VERSION "HNNBNNNYNNNNNNNNNNNNNNNNNNNNNNNNNNNNNNNNNN/4/%%%/4/'%**4NNN///"

NS_ :

BS_:

BU_: BAP_Tester FASFrontradar ICAS1_X_Gateway MFK MFK120 MIK MRR2023 NR_1 NR_2

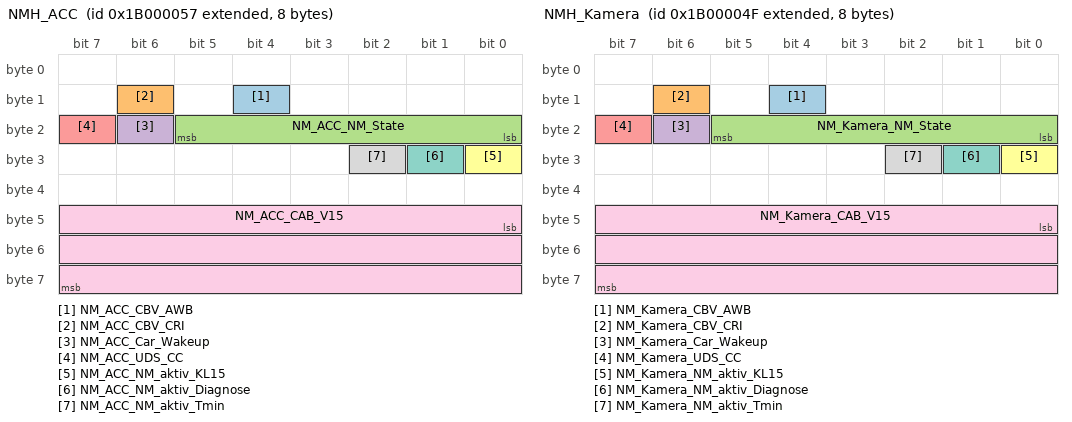
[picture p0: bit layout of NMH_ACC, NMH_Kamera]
BO_ 2600468567 NMH_ACC: 8 FASFrontradar
 SG_ NM_ACC_CBV_AWB : 12|1@1+ (1.0,0.0) [0.0|1] ""  ICAS1_X_Gateway
 SG_ NM_ACC_CBV_CRI : 14|1@1+ (1.0,0.0) [0.0|1] ""  ICAS1_X_Gateway
 SG_ NM_ACC_NM_State : 16|6@1+ (1.0,0.0) [0.0|63] ""  MFK,MFK120,MIK,NR_1,NR_2
 SG_ NM_ACC_Car_Wakeup : 22|1@1+ (1.0,0.0) [0.0|1] ""  ICAS1_X_Gateway
 SG_ NM_ACC_UDS_CC : 23|1@1+ (1.0,0.0) [0.0|1] ""  Vector__XXX
 SG_ NM_ACC_NM_aktiv_KL15 : 24|1@1+ (1.0,0.0) [0.0|1] ""  Vector__XXX
 SG_ NM_ACC_NM_aktiv_Diagnose : 25|1@1+ (1.0,0.0) [0.0|1] ""  Vector__XXX
 SG_ NM_ACC_NM_aktiv_Tmin : 26|1@1+ (1.0,0.0) [0.0|1] ""  Vector__XXX
 SG_ NM_ACC_CAB_V15 : 40|24@1+ (1.0,0.0) [0.0|16777215] ""  ICAS1_X_Gateway

BO_ 2600468496 NMH_Gateway: 8 ICAS1_X_Gateway
 SG_ NM_Gateway_CBV_AWB : 12|1@1+ (1.0,0.0) [0.0|1] ""  Vector__XXX
 SG_ NM_Gateway_CBV_CRI : 14|1@1+ (1.0,0.0) [0.0|1] ""  Vector__XXX
 SG_ NM_Gateway_NM_State : 16|6@1+ (1.0,0.0) [0.0|63] ""  FASFrontradar,MFK,MFK120,MIK,MRR2023,NR_1,NR_2
 SG_ NM_Gateway_Car_Wakeup : 22|1@1+ (1.0,0.0) [0.0|1] ""  Vector__XXX
 SG_ NM_Gateway_UDS_CC : 23|1@1+ (1.0,0.0) [0.0|1] ""  Vector__XXX
 SG_ NM_Gateway_NM_aktiv_KL15 : 24|1@1+ (1.0,0.0) [0.0|1] ""  Vector__XXX
 SG_ NM_Gateway_NM_aktiv_Diagnose : 25|1@1+ (1.0,0.0) [0.0|1] ""  Vector__XXX
 SG_ NM_Gateway_NM_aktiv_Tmin : 26|1@1+ (1.0,0.0) [0.0|1] ""  Vector__XXX
 SG_ NM_Gateway_NM_aktiv_Kessy : 27|1@1+ (1.0,0.0) [0.0|1] ""  Vector__XXX
 SG_ NM_Gateway_NM_aktiv_Energie : 28|1@1+ (1.0,0.0) [0.0|1] ""  Vector__XXX
 SG_ NM_Gateway_NM_aktiv_Licht : 29|1@1+ (1.0,0.0) [0.0|1] ""  Vector__XXX
 SG_ NM_Gateway_NM_aktiv_USS : 30|1@1+ (1.0,0.0) [0.0|1] ""  Vector__XXX
 SG_ NM_Gateway_NM_aktiv_IAA_PSO : 31|1@1+ (1.0,0.0) [0.0|1] ""  Vector__XXX
 SG_ NM_Gateway_NM_aktiv_CAB : 32|1@1+ (1.0,0.0) [0.0|1] ""  Vector__XXX
 SG_ NM_Gateway_NM_aktiv_KS : 33|1@1+ (1.0,0.0) [0.0|1] ""  Vector__XXX
 SG_ NM_Gateway_NM_aktiv_PaCo : 34|1@1+ (1.0,0.0) [0.0|1] ""  Vector__XXX
 SG_ NM_Gateway_NM_aktiv_Standklima : 35|1@1+ (1.0,0.0) [0.0|1] ""  Vector__XXX
 SG_ NM_Gateway_NM_aktiv_ZV : 36|1@1+ (1.0,0.0) [0.0|1] ""  Vector__XXX
 SG_ NM_Gateway_NM_aktiv_RTM : 37|1@1+ (1.0,0.0) [0.0|1] ""  Vector__XXX
 SG_ NM_Gateway_NM_aktiv_ZM : 38|1@1+ (1.0,0.0) [0.0|1] ""  Vector__XXX
 SG_ NM_Gateway_NM_aktiv_FoD : 39|1@1+ (1.0,0.0) [0.0|1] ""  Vector__XXX
 SG_ NM_Gateway_CAB_V15 : 40|24@1+ (1.0,0.0) [0.0|16777215] ""  Vector__XXX

BO_ 2600468559 NMH_Kamera: 8 MFK
 SG_ NM_Kamera_CBV_AWB : 12|1@1+ (1.0,0.0) [0.0|1] ""  ICAS1_X_Gateway
 SG_ NM_Kamera_CBV_CRI : 14|1@1+ (1.0,0.0) [0.0|1] ""  ICAS1_X_Gateway
 SG_ NM_Kamera_NM_State : 16|6@1+ (1.0,0.0) [0.0|63] ""  FASFrontradar,MIK,MRR2023,NR_1,NR_2
 SG_ NM_Kamera_Car_Wakeup : 22|1@1+ (1.0,0.0) [0.0|1] ""  ICAS1_X_Gateway
 SG_ NM_Kamera_UDS_CC : 23|1@1+ (1.0,0.0) [0.0|1] ""  Vector__XXX
 SG_ NM_Kamera_NM_aktiv_KL15 : 24|1@1+ (1.0,0.0) [0.0|1] ""  Vector__XXX
 SG_ NM_Kamera_NM_aktiv_Diagnose : 25|1@1+ (1.0,0.0) [0.0|1] ""  Vector__XXX
 SG_ NM_Kamera_NM_aktiv_Tmin : 26|1@1+ (1.0,0.0) [0.0|1] ""  Vector__XXX
 SG_ NM_Kamera_CAB_V15 : 40|24@1+ (1.0,0.0) [0.0|16777215] ""  ICAS1_X_Gateway

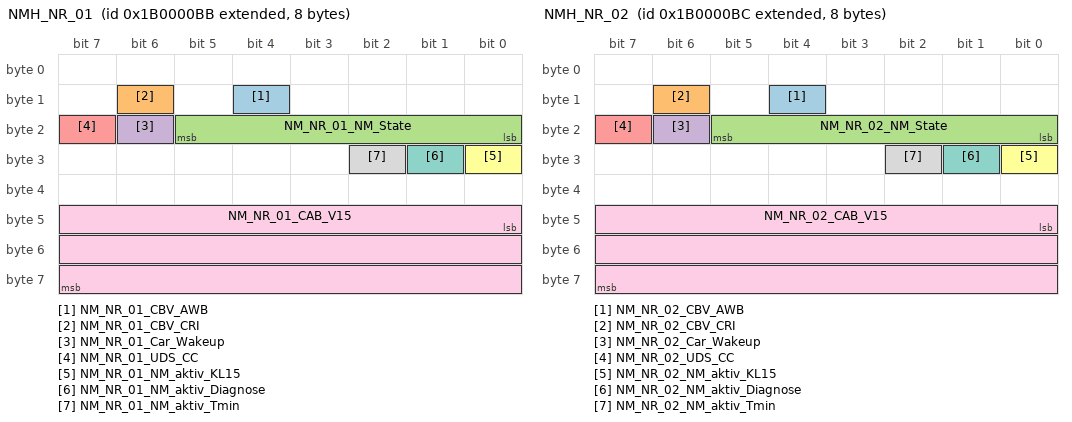
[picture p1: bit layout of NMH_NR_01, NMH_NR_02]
BO_ 2600468667 NMH_NR_01: 8 NR_1
 SG_ NM_NR_01_CBV_AWB : 12|1@1+ (1.0,0.0) [0.0|1] ""  ICAS1_X_Gateway
 SG_ NM_NR_01_CBV_CRI : 14|1@1+ (1.0,0.0) [0.0|1] ""  ICAS1_X_Gateway
 SG_ NM_NR_01_NM_State : 16|6@1+ (1.0,0.0) [0.0|63] ""  MFK120,MIK,MRR2023,NR_2
 SG_ NM_NR_01_Car_Wakeup : 22|1@1+ (1.0,0.0) [0.0|1] ""  ICAS1_X_Gateway
 SG_ NM_NR_01_UDS_CC : 23|1@1+ (1.0,0.0) [0.0|1] ""  Vector__XXX
 SG_ NM_NR_01_NM_aktiv_KL15 : 24|1@1+ (1.0,0.0) [0.0|1] ""  Vector__XXX
 SG_ NM_NR_01_NM_aktiv_Diagnose : 25|1@1+ (1.0,0.0) [0.0|1] ""  Vector__XXX
 SG_ NM_NR_01_NM_aktiv_Tmin : 26|1@1+ (1.0,0.0) [0.0|1] ""  Vector__XXX
 SG_ NM_NR_01_CAB_V15 : 40|24@1+ (1.0,0.0) [0.0|16777215] ""  ICAS1_X_Gateway

BO_ 2600468668 NMH_NR_02: 8 NR_2
 SG_ NM_NR_02_CBV_AWB : 12|1@1+ (1.0,0.0) [0.0|1] ""  ICAS1_X_Gateway
 SG_ NM_NR_02_CBV_CRI : 14|1@1+ (1.0,0.0) [0.0|1] ""  ICAS1_X_Gateway
 SG_ NM_NR_02_NM_State : 16|6@1+ (1.0,0.0) [0.0|63] ""  MFK120,MIK,MRR2023,NR_1
 SG_ NM_NR_02_Car_Wakeup : 22|1@1+ (1.0,0.0) [0.0|1] ""  ICAS1_X_Gateway
 SG_ NM_NR_02_UDS_CC : 23|1@1+ (1.0,0.0) [0.0|1] ""  Vector__XXX
 SG_ NM_NR_02_NM_aktiv_KL15 : 24|1@1+ (1.0,0.0) [0.0|1] ""  Vector__XXX
 SG_ NM_NR_02_NM_aktiv_Diagnose : 25|1@1+ (1.0,0.0) [0.0|1] ""  Vector__XXX
 SG_ NM_NR_02_NM_aktiv_Tmin : 26|1@1+ (1.0,0.0) [0.0|1] ""  Vector__XXX
 SG_ NM_NR_02_CAB_V15 : 40|24@1+ (1.0,0.0) [0.0|16777215] ""  ICAS1_X_Gateway

BO_ 2589283909 NR_01_CAL_Text_01: 8 NR_1
 SG_ NR_01_CAL_Text_Request : 0|1@1+ (1.0,0.0) [0.0|1] ""  ICAS1_X_Gateway
 SG_ NR_01_CAL_Text_Data_1 : 8|56@1+ (1.0,0.0) [0.0|72057594037927935] ""  ICAS1_X_Gateway

BO_ 2589283910 NR_01_CAL_Text_02: 8 NR_1
 SG_ NR_01_CAL_Text_Data_2 : 0|64@1+ (1.0,0.0) [0.0|18446744073709551615] ""  ICAS1_X_Gateway

BO_ 2589283911 NR_01_CAL_Text_03: 8 NR_1
 SG_ NR_01_CAL_Text_Data_3 : 0|64@1+ (1.0,0.0) [0.0|18446744073709551615] ""  ICAS1_X_Gateway

BO_ 2527679889 NR_02_CAL_01: 8 NR_2
 SG_ NR_02_CAL_LgtLimV_StAcv : 12|2@1+ (1.0,0.0) [0.0|3] ""  Vector__XXX
 SG_ NR_02_CAL_LgtLimV_VDmd : 14|7@1+ (0.1,0) [0.0|12.4] "Unit_MeterPerSecon"  Vector__XXX

BO_ 2589283912 NR_02_CAL_Text_01: 8 NR_2
 SG_ NR_02_CAL_Text_Request : 0|1@1+ (1.0,0.0) [0.0|1] ""  ICAS1_X_Gateway
 SG_ NR_02_CAL_Text_Data_1 : 8|56@1+ (1.0,0.0) [0.0|72057594037927935] ""  ICAS1_X_Gateway

BO_ 2589283913 NR_02_CAL_Text_02: 8 NR_2
 SG_ NR_02_CAL_Text_Data_2 : 0|64@1+ (1.0,0.0) [0.0|18446744073709551615] ""  ICAS1_X_Gateway

BO_ 2589283914 NR_02_CAL_Text_03: 8 NR_2
 SG_ NR_02_CAL_Text_Data_3 : 0|64@1+ (1.0,0.0) [0.0|18446744073709551615] ""  ICAS1_X_Gateway

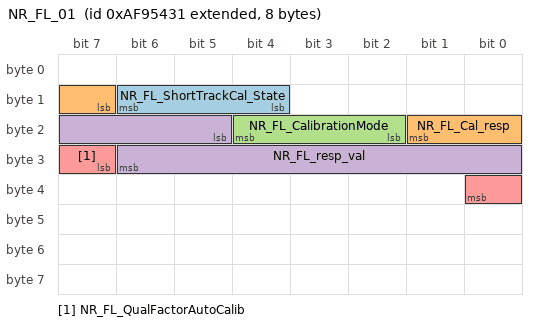
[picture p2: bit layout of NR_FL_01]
BO_ 2331595825 NR_FL_01: 8 NR_1
 SG_ NR_FL_ShortTrackCal_State : 12|3@1+ (1.0,0.0) [0.0|7] ""  ICAS1_X_Gateway,MRR2023
 SG_ NR_FL_Cal_resp : 15|3@1+ (1.0,0.0) [0.0|7] ""  ICAS1_X_Gateway,MRR2023
 SG_ NR_FL_CalibrationMode : 18|3@1+ (1.0,0.0) [0.0|7] ""  ICAS1_X_Gateway,MRR2023
 SG_ NR_FL_resp_val : 21|10@1+ (0.01,-5) [-5.00|5.00] "Unit_DegreOfArc"  ICAS1_X_Gateway,MRR2023
 SG_ NR_FL_QualFactorAutoCalib : 31|2@1+ (1.0,0.0) [0.0|3] ""  ICAS1_X_Gateway,MRR2023

BO_ 2331595790 NR_FL_Contour: 64 NR_1
 SG_ NR_FL_Contour_CRC : 0|8@1+ (1,0) [0|255] ""  ICAS1_X_Gateway,MRR2023
 SG_ NR_FL_Contour_BZ : 8|4@1+ (1,0) [0|15] ""  ICAS1_X_Gateway,MRR2023
 SG_ NR_FL_Contour_BlockID_01 : 12|4@1+ (1,0) [0|15] "Unit_None"  ICAS1_X_Gateway,MRR2023
 SG_ NR_FL_Contour_left_01_x01 : 16|13@1+ (0.0625,-256) [-256.0000|255.8750] "Unit_Meter"  ICAS1_X_Gateway,MRR2023
 SG_ NR_FL_Contour_left_01_y01 : 29|11@1+ (0.0625,-64) [-64.0000|63.8750] "Unit_Meter"  ICAS1_X_Gateway,MRR2023
 SG_ NR_FL_Contour_left_01_x02 : 40|13@1+ (0.0625,-256) [-256.0000|255.8750] "Unit_Meter"  ICAS1_X_Gateway,MRR2023
 SG_ NR_FL_Contour_left_01_y02 : 53|11@1+ (0.0625,-64) [-64.0000|63.8750] "Unit_Meter"  ICAS1_X_Gateway,MRR2023
 SG_ NR_FL_Contour_left_01_x03 : 64|13@1+ (0.0625,-256) [-256.0000|255.8750] "Unit_Meter"  ICAS1_X_Gateway,MRR2023
 SG_ NR_FL_Contour_left_01_y03 : 77|11@1+ (0.0625,-64) [-64.0000|63.8750] "Unit_Meter"  ICAS1_X_Gateway,MRR2023
 SG_ NR_FL_Contour_left_01_x04 : 88|13@1+ (0.0625,-256) [-256.0000|255.8750] "Unit_Meter"  ICAS1_X_Gateway,MRR2023
 SG_ NR_FL_Contour_left_01_y04 : 101|11@1+ (0.0625,-64) [-64.0000|63.8750] "Unit_Meter"  ICAS1_X_Gateway,MRR2023
 SG_ NR_FL_Contour_left_01_x05 : 112|13@1+ (0.0625,-256) [-256.0000|255.8750] "Unit_Meter"  ICAS1_X_Gateway,MRR2023
 SG_ NR_FL_Contour_left_01_y05 : 125|11@1+ (0.0625,-64) [-64.0000|63.8750] "Unit_Meter"  ICAS1_X_Gateway,MRR2023
 SG_ NR_FL_Contour_left_01_x06 : 136|13@1+ (0.0625,-256) [-256.0000|255.8750] "Unit_Meter"  ICAS1_X_Gateway,MRR2023
 SG_ NR_FL_Contour_left_01_y06 : 149|11@1+ (0.0625,-64) [-64.0000|63.8750] "Unit_Meter"  ICAS1_X_Gateway,MRR2023
 SG_ NR_FL_Contour_left_01_x07 : 160|13@1+ (0.0625,-256) [-256.0000|255.8750] "Unit_Meter"  ICAS1_X_Gateway,MRR2023
 SG_ NR_FL_Contour_left_01_y07 : 173|11@1+ (0.0625,-64) [-64.0000|63.8750] "Unit_Meter"  ICAS1_X_Gateway,MRR2023
 SG_ NR_FL_Contour_left_01_Type : 184|3@1+ (1.0,0.0) [0.0|7] ""  ICAS1_X_Gateway,MRR2023
 SG_ NR_FL_Contour_left_01_Age : 187|7@1+ (1,0) [0|126] "Unit_None"  ICAS1_X_Gateway,MRR2023
 SG_ NR_FL_Contour_left_02_x01 : 194|13@1+ (0.0625,-256) [-256.0000|255.8750] "Unit_Meter"  ICAS1_X_Gateway,MRR2023
 SG_ NR_FL_Contour_left_02_y01 : 207|11@1+ (0.0625,-64) [-64.0000|63.8750] "Unit_Meter"  ICAS1_X_Gateway,MRR2023
 SG_ NR_FL_Contour_left_02_x02 : 218|13@1+ (0.0625,-256) [-256.0000|255.8750] "Unit_Meter"  ICAS1_X_Gateway,MRR2023
 SG_ NR_FL_Contour_left_02_y02 : 231|11@1+ (0.0625,-64) [-64.0000|63.8750] "Unit_Meter"  ICAS1_X_Gateway,MRR2023
 SG_ NR_FL_Contour_left_02_x03 : 242|13@1+ (0.0625,-256) [-256.0000|255.8750] "Unit_Meter"  ICAS1_X_Gateway,MRR2023
 SG_ NR_FL_Contour_left_02_y03 : 255|11@1+ (0.0625,-64) [-64.0000|63.8750] "Unit_Meter"  ICAS1_X_Gateway,MRR2023
 SG_ NR_FL_Contour_left_02_x04 : 266|13@1+ (0.0625,-256) [-256.0000|255.8750] "Unit_Meter"  ICAS1_X_Gateway,MRR2023
 SG_ NR_FL_Contour_left_02_y04 : 279|11@1+ (0.0625,-64) [-64.0000|63.8750] "Unit_Meter"  ICAS1_X_Gateway,MRR2023
 SG_ NR_FL_Contour_left_02_x05 : 290|13@1+ (0.0625,-256) [-256.0000|255.8750] "Unit_Meter"  ICAS1_X_Gateway,MRR2023
 SG_ NR_FL_Contour_left_02_y05 : 303|11@1+ (0.0625,-64) [-64.0000|63.8750] "Unit_Meter"  ICAS1_X_Gateway,MRR2023
 SG_ NR_FL_Contour_left_02_x06 : 314|13@1+ (0.0625,-256) [-256.0000|255.8750] "Unit_Meter"  ICAS1_X_Gateway,MRR2023
 SG_ NR_FL_Contour_left_02_y06 : 327|11@1+ (0.0625,-64) [-64.0000|63.8750] "Unit_Meter"  ICAS1_X_Gateway,MRR2023
 SG_ NR_FL_Contour_left_02_x07 : 338|13@1+ (0.0625,-256) [-256.0000|255.8750] "Unit_Meter"  ICAS1_X_Gateway,MRR2023
 SG_ NR_FL_Contour_left_02_y07 : 351|11@1+ (0.0625,-64) [-64.0000|63.8750] "Unit_Meter"  ICAS1_X_Gateway,MRR2023
 SG_ NR_FL_Contour_left_02_Type : 362|3@1+ (1.0,0.0) [0.0|7] ""  ICAS1_X_Gateway,MRR2023
 SG_ NR_FL_Contour_left_02_Age : 365|7@1+ (1,0) [0|126] "Unit_None"  ICAS1_X_Gateway,MRR2023
 SG_ NR_FL_Contour_left_Linkage : 372|1@1+ (1.0,0.0) [0.0|1] ""  ICAS1_X_Gateway,MRR2023
 SG_ SOK_NR_FL_Contour_Signatur : 480|32@1+ (1,0) [0|4294967295] ""  ICAS1_X_Gateway

BO_ 2331595781 NR_FL_Header: 20 NR_1
 SG_ NR_FL_Header_CRC : 0|8@1+ (1,0) [0|255] ""  ICAS1_X_Gateway,MRR2023
 SG_ NR_FL_Header_BZ : 8|4@1+ (1,0) [0|15] ""  ICAS1_X_Gateway,MRR2023
 SG_ NR_FL_BlockID_01 : 12|4@1+ (1,0) [0|15] "Unit_None"  ICAS1_X_Gateway,MRR2023
 SG_ NR_FL_NotAvailable : 16|1@1+ (1.0,0.0) [0.0|1] ""  ICAS1_X_Gateway,MRR2023
 SG_ NR_FL_Failure : 17|1@1+ (1.0,0.0) [0.0|1] ""  ICAS1_X_Gateway,MRR2023
 SG_ NR_FL_Blindness : 18|1@1+ (1.0,0.0) [0.0|1] ""  ICAS1_X_Gateway,MRR2023
 SG_ NR_FL_CalibrationState : 19|3@1+ (1.0,0.0) [0.0|7] ""  ICAS1_X_Gateway,MRR2023
 SG_ NR_FL_Freesight_NOK : 22|1@1+ (1.0,0.0) [0.0|1] ""  ICAS1_X_Gateway,MRR2023
 SG_ NR_FL_MeasurementTimeLow : 30|32@1+ (1,0) [0|999999999] "Unit_NanoSecon"  ICAS1_X_Gateway,MRR2023
 SG_ NR_FL_MeasurementTimeHigh : 62|32@1+ (1,0) [0|4294967293] "Unit_Secon"  ICAS1_X_Gateway,MRR2023
 SG_ NR_FL_RangeDegradation_Sect1 : 94|3@1+ (1.0,0.0) [0.0|7] ""  ICAS1_X_Gateway,MRR2023
 SG_ NR_FL_RangeDegradation_Sect2 : 97|3@1+ (1.0,0.0) [0.0|7] ""  ICAS1_X_Gateway,MRR2023
 SG_ NR_FL_RangeDegradation_Sect3 : 100|3@1+ (1.0,0.0) [0.0|7] ""  ICAS1_X_Gateway,MRR2023
 SG_ NR_FL_MeasurementTimeLapNumber : 103|14@1+ (1,0) [0|16381] "Unit_None"  ICAS1_X_Gateway,MRR2023
 SG_ NR_FL_MeasurementTimeStatus : 117|2@1+ (1.0,0.0) [0.0|3] ""  ICAS1_X_Gateway,MRR2023
 SG_ SOK_NR_FL_Header_Signatur : 128|32@1+ (1,0) [0|4294967295] ""  ICAS1_X_Gateway

BO_ 2331595776 NR_FL_Object_01_02: 64 NR_1
 SG_ NR_FL_Object_01_02_CRC : 0|8@1+ (1,0) [0|255] ""  ICAS1_X_Gateway,MRR2023
 SG_ NR_FL_Object_01_02_BZ : 8|4@1+ (1,0) [0|15] ""  ICAS1_X_Gateway,MRR2023
 SG_ NR_FL_Object_01_02_BlockID_01 : 12|4@1+ (1,0) [0|15] "Unit_None"  ICAS1_X_Gateway,MRR2023
 SG_ NR_FL_Object_01_ID : 16|8@1+ (1,0) [1|254] "Unit_None"  ICAS1_X_Gateway,MRR2023
 SG_ NR_FL_Object_01_ReferencePoint : 24|4@1+ (1.0,0.0) [0.0|15] ""  ICAS1_X_Gateway,MRR2023
 SG_ NR_FL_Object_01_PosX : 28|14@1+ (0.03125,-200) [-200.00000|311.93750] "Unit_Meter"  ICAS1_X_Gateway,MRR2023
 SG_ NR_FL_Object_01_PosXSD : 42|8@1+ (0.03125,0) [0.00000|7.93750] "Unit_Meter"  ICAS1_X_Gateway,MRR2023
 SG_ NR_FL_Object_01_PosY : 50|13@1+ (0.03125,-128) [-128.00000|127.93750] "Unit_Meter"  ICAS1_X_Gateway,MRR2023
 SG_ NR_FL_Object_01_PosYSD : 63|8@1+ (0.03125,0) [0.00000|7.93750] "Unit_Meter"  ICAS1_X_Gateway,MRR2023
 SG_ NR_FL_Object_01_vAbsX : 71|12@1+ (0.0625,-128) [-128.0000|127.8750] "Unit_MeterPerSecon"  ICAS1_X_Gateway,MRR2023
 SG_ NR_FL_Object_01_vAbsXSD : 83|6@1+ (0.0625,0) [0.0000|3.8750] "Unit_MeterPerSecon"  ICAS1_X_Gateway,MRR2023
 SG_ NR_FL_Object_01_vAbsY : 89|12@1+ (0.0625,-128) [-128.0000|127.8750] "Unit_MeterPerSecon"  ICAS1_X_Gateway,MRR2023
 SG_ NR_FL_Object_01_vAbsYSD : 101|6@1+ (0.0625,0) [0.0000|3.8750] "Unit_MeterPerSecon"  ICAS1_X_Gateway,MRR2023
 SG_ NR_FL_Object_01_aAbsX : 107|9@1+ (0.0625,-16) [-16.0000|15.8750] "Unit_MeterPerSeconSquar"  ICAS1_X_Gateway,MRR2023
 SG_ NR_FL_Object_01_aAbsXSD : 116|6@1+ (0.0625,0) [0.0000|3.8750] "Unit_MeterPerSeconSquar"  ICAS1_X_Gateway,MRR2023
 SG_ NR_FL_Object_01_aAbsY : 122|9@1+ (0.0625,-16) [-16.0000|15.8750] "Unit_MeterPerSeconSquar"  ICAS1_X_Gateway,MRR2023
 SG_ NR_FL_Object_01_aAbsYSD : 131|6@1+ (0.0625,0) [0.0000|3.8750] "Unit_MeterPerSeconSquar"  ICAS1_X_Gateway,MRR2023
 SG_ NR_FL_Object_01_DynamicState : 137|2@1+ (1.0,0.0) [0.0|3] ""  ICAS1_X_Gateway,MRR2023
 SG_ NR_FL_Object_01_YawAngle : 139|12@1+ (0.001953125,-4) [-4.000000000|3.996093750] "Unit_Radia"  ICAS1_X_Gateway,MRR2023
 SG_ NR_FL_Object_01_YawAngleSD : 151|9@1+ (0.001953125,0) [0E-9|0.996093750] "Unit_Radia"  ICAS1_X_Gateway,MRR2023
 SG_ NR_FL_Object_01_Width : 160|8@1+ (0.03125,0) [0.00000|7.93750] "Unit_Meter"  ICAS1_X_Gateway,MRR2023
 SG_ NR_FL_Object_01_WidthSD : 168|7@1+ (0.03125,0) [0.00000|3.93750] "Unit_Meter"  ICAS1_X_Gateway,MRR2023
 SG_ NR_FL_Object_01_Length : 175|10@1+ (0.03125,0) [0.00000|31.93750] "Unit_Meter"  ICAS1_X_Gateway,MRR2023
 SG_ NR_FL_Object_01_LengthSD : 185|7@1+ (0.03125,0) [0.00000|3.93750] "Unit_Meter"  ICAS1_X_Gateway,MRR2023
 SG_ NR_FL_Object_01_Class : 192|4@1+ (1.0,0.0) [0.0|15] ""  ICAS1_X_Gateway,MRR2023
 SG_ NR_FL_Object_01_ClassPlausib : 196|4@1+ (0.0714285714,0) [0E-10|0.9999999996] "Unit_None"  ICAS1_X_Gateway,MRR2023
 SG_ NR_FL_Object_01_ExistProb : 200|7@1+ (0.0078125,0.015625) [0.0156250|1.0000000] "Unit_None"  ICAS1_X_Gateway,MRR2023
 SG_ NR_FL_Object_01_Age : 207|7@1+ (1,0) [0|126] "Unit_None"  ICAS1_X_Gateway,MRR2023
 SG_ NR_FL_Object_01_YawRateAbs : 214|12@1+ (0.001953125,-4) [-4.000000000|3.996093750] "Unit_RadiaPerSecon"  ICAS1_X_Gateway,MRR2023
 SG_ NR_FL_Object_01_YawRateAbsSD : 226|6@1+ (0.003906,0) [0.000000|0.242172] "Unit_RadiaPerSecon"  ICAS1_X_Gateway,MRR2023
 SG_ NR_FL_Object_01_MeasurementState : 232|1@1+ (1.0,0.0) [0.0|1] ""  ICAS1_X_Gateway,MRR2023
 SG_ NR_FL_Object_02_ID : 233|8@1+ (1,0) [1|254] "Unit_None"  ICAS1_X_Gateway,MRR2023
 SG_ NR_FL_Object_02_ReferencePoint : 241|4@1+ (1.0,0.0) [0.0|15] ""  ICAS1_X_Gateway,MRR2023
 SG_ NR_FL_Object_02_PosX : 245|14@1+ (0.03125,-200) [-200.00000|311.93750] "Unit_Meter"  ICAS1_X_Gateway,MRR2023
 SG_ NR_FL_Object_02_PosXSD : 259|8@1+ (0.03125,0) [0.00000|7.93750] "Unit_Meter"  ICAS1_X_Gateway,MRR2023
 SG_ NR_FL_Object_02_PosY : 267|13@1+ (0.03125,-128) [-128.00000|127.93750] "Unit_Meter"  ICAS1_X_Gateway,MRR2023
 SG_ NR_FL_Object_02_PosYSD : 280|8@1+ (0.03125,0) [0.00000|7.93750] "Unit_Meter"  ICAS1_X_Gateway,MRR2023
 SG_ NR_FL_Object_02_vAbsX : 288|12@1+ (0.0625,-128) [-128.0000|127.8750] "Unit_MeterPerSecon"  ICAS1_X_Gateway,MRR2023
 SG_ NR_FL_Object_02_vAbsXSD : 300|6@1+ (0.0625,0) [0.0000|3.8750] "Unit_MeterPerSecon"  ICAS1_X_Gateway,MRR2023
 SG_ NR_FL_Object_02_vAbsY : 306|12@1+ (0.0625,-128) [-128.0000|127.8750] "Unit_MeterPerSecon"  ICAS1_X_Gateway,MRR2023
 SG_ NR_FL_Object_02_vAbsYSD : 318|6@1+ (0.0625,0) [0.0000|3.8750] "Unit_MeterPerSecon"  ICAS1_X_Gateway,MRR2023
 SG_ NR_FL_Object_02_aAbsX : 324|9@1+ (0.0625,-16) [-16.0000|15.8750] "Unit_MeterPerSeconSquar"  ICAS1_X_Gateway,MRR2023
 SG_ NR_FL_Object_02_aAbsXSD : 333|6@1+ (0.0625,0) [0.0000|3.8750] "Unit_MeterPerSeconSquar"  ICAS1_X_Gateway,MRR2023
 SG_ NR_FL_Object_02_aAbsY : 339|9@1+ (0.0625,-16) [-16.0000|15.8750] "Unit_MeterPerSeconSquar"  ICAS1_X_Gateway,MRR2023
 SG_ NR_FL_Object_02_aAbsYSD : 348|6@1+ (0.0625,0) [0.0000|3.8750] "Unit_MeterPerSeconSquar"  ICAS1_X_Gateway,MRR2023
 SG_ NR_FL_Object_02_DynamicState : 354|2@1+ (1.0,0.0) [0.0|3] ""  ICAS1_X_Gateway,MRR2023
 SG_ NR_FL_Object_02_YawAngle : 356|12@1+ (0.001953125,-4) [-4.000000000|3.996093750] "Unit_Radia"  ICAS1_X_Gateway,MRR2023
 SG_ NR_FL_Object_02_YawAngleSD : 368|9@1+ (0.001953125,0) [0E-9|0.996093750] "Unit_Radia"  ICAS1_X_Gateway,MRR2023
 SG_ NR_FL_Object_02_Width : 377|8@1+ (0.03125,0) [0.00000|7.93750] "Unit_Meter"  ICAS1_X_Gateway,MRR2023
 SG_ NR_FL_Object_02_WidthSD : 385|7@1+ (0.03125,0) [0.00000|3.93750] "Unit_Meter"  ICAS1_X_Gateway,MRR2023
 SG_ NR_FL_Object_02_Length : 392|10@1+ (0.03125,0) [0.00000|31.93750] "Unit_Meter"  ICAS1_X_Gateway,MRR2023
 SG_ NR_FL_Object_02_LengthSD : 402|7@1+ (0.03125,0) [0.00000|3.93750] "Unit_Meter"  ICAS1_X_Gateway,MRR2023
 SG_ NR_FL_Object_02_Class : 409|4@1+ (1.0,0.0) [0.0|15] ""  ICAS1_X_Gateway,MRR2023
 SG_ NR_FL_Object_02_ClassPlausib : 413|4@1+ (0.0714285714,0) [0E-10|0.9999999996] "Unit_None"  ICAS1_X_Gateway,MRR2023
 SG_ NR_FL_Object_02_ExistProb : 417|7@1+ (0.0078125,0.015625) [0.0156250|1.0000000] "Unit_None"  ICAS1_X_Gateway,MRR2023
 SG_ NR_FL_Object_02_Age : 424|7@1+ (1,0) [0|126] "Unit_None"  ICAS1_X_Gateway,MRR2023
 SG_ NR_FL_Object_02_YawRateAbs : 431|12@1+ (0.001953125,-4) [-4.000000000|3.996093750] "Unit_RadiaPerSecon"  ICAS1_X_Gateway,MRR2023
 SG_ NR_FL_Object_02_YawRateAbsSD : 443|6@1+ (0.003906,0) [0.000000|0.242172] "Unit_RadiaPerSecon"  ICAS1_X_Gateway,MRR2023
 SG_ NR_FL_Object_02_MeasurementState : 449|1@1+ (1.0,0.0) [0.0|1] ""  ICAS1_X_Gateway,MRR2023
 SG_ SOK_NR_FL_Object_01_02_Signatur : 480|32@1+ (1,0) [0|4294967295] ""  ICAS1_X_Gateway

BO_ 2331595777 NR_FL_Object_03_04: 64 NR_1
 SG_ NR_FL_Object_03_04_CRC : 0|8@1+ (1,0) [0|255] ""  ICAS1_X_Gateway,MRR2023
 SG_ NR_FL_Object_03_04_BZ : 8|4@1+ (1,0) [0|15] ""  ICAS1_X_Gateway,MRR2023
 SG_ NR_FL_Object_03_04_BlockID_01 : 12|4@1+ (1,0) [0|15] "Unit_None"  ICAS1_X_Gateway,MRR2023
 SG_ NR_FL_Object_03_ID : 16|8@1+ (1,0) [1|254] "Unit_None"  ICAS1_X_Gateway,MRR2023
 SG_ NR_FL_Object_03_ReferencePoint : 24|4@1+ (1.0,0.0) [0.0|15] ""  ICAS1_X_Gateway,MRR2023
 SG_ NR_FL_Object_03_PosX : 28|14@1+ (0.03125,-200) [-200.00000|311.93750] "Unit_Meter"  ICAS1_X_Gateway,MRR2023
 SG_ NR_FL_Object_03_PosXSD : 42|8@1+ (0.03125,0) [0.00000|7.93750] "Unit_Meter"  ICAS1_X_Gateway,MRR2023
 SG_ NR_FL_Object_03_PosY : 50|13@1+ (0.03125,-128) [-128.00000|127.93750] "Unit_Meter"  ICAS1_X_Gateway,MRR2023
 SG_ NR_FL_Object_03_PosYSD : 63|8@1+ (0.03125,0) [0.00000|7.93750] "Unit_Meter"  ICAS1_X_Gateway,MRR2023
 SG_ NR_FL_Object_03_vAbsX : 71|12@1+ (0.0625,-128) [-128.0000|127.8750] "Unit_MeterPerSecon"  ICAS1_X_Gateway,MRR2023
 SG_ NR_FL_Object_03_vAbsXSD : 83|6@1+ (0.0625,0) [0.0000|3.8750] "Unit_MeterPerSecon"  ICAS1_X_Gateway,MRR2023
 SG_ NR_FL_Object_03_vAbsY : 89|12@1+ (0.0625,-128) [-128.0000|127.8750] "Unit_MeterPerSecon"  ICAS1_X_Gateway,MRR2023
 SG_ NR_FL_Object_03_vAbsYSD : 101|6@1+ (0.0625,0) [0.0000|3.8750] "Unit_MeterPerSecon"  ICAS1_X_Gateway,MRR2023
 SG_ NR_FL_Object_03_aAbsX : 107|9@1+ (0.0625,-16) [-16.0000|15.8750] "Unit_MeterPerSeconSquar"  ICAS1_X_Gateway,MRR2023
 SG_ NR_FL_Object_03_aAbsXSD : 116|6@1+ (0.0625,0) [0.0000|3.8750] "Unit_MeterPerSeconSquar"  ICAS1_X_Gateway,MRR2023
 SG_ NR_FL_Object_03_aAbsY : 122|9@1+ (0.0625,-16) [-16.0000|15.8750] "Unit_MeterPerSeconSquar"  ICAS1_X_Gateway,MRR2023
 SG_ NR_FL_Object_03_aAbsYSD : 131|6@1+ (0.0625,0) [0.0000|3.8750] "Unit_MeterPerSeconSquar"  ICAS1_X_Gateway,MRR2023
 SG_ NR_FL_Object_03_DynamicState : 137|2@1+ (1.0,0.0) [0.0|3] ""  ICAS1_X_Gateway,MRR2023
 SG_ NR_FL_Object_03_YawAngle : 139|12@1+ (0.001953125,-4) [-4.000000000|3.996093750] "Unit_Radia"  ICAS1_X_Gateway,MRR2023
 SG_ NR_FL_Object_03_YawAngleSD : 151|9@1+ (0.001953125,0) [0E-9|0.996093750] "Unit_Radia"  ICAS1_X_Gateway,MRR2023
 SG_ NR_FL_Object_03_Width : 160|8@1+ (0.03125,0) [0.00000|7.93750] "Unit_Meter"  ICAS1_X_Gateway,MRR2023
 SG_ NR_FL_Object_03_WidthSD : 168|7@1+ (0.03125,0) [0.00000|3.93750] "Unit_Meter"  ICAS1_X_Gateway,MRR2023
 SG_ NR_FL_Object_03_Length : 175|10@1+ (0.03125,0) [0.00000|31.93750] "Unit_Meter"  ICAS1_X_Gateway,MRR2023
 SG_ NR_FL_Object_03_LengthSD : 185|7@1+ (0.03125,0) [0.00000|3.93750] "Unit_Meter"  ICAS1_X_Gateway,MRR2023
 SG_ NR_FL_Object_03_Class : 192|4@1+ (1.0,0.0) [0.0|15] ""  ICAS1_X_Gateway,MRR2023
 SG_ NR_FL_Object_03_ClassPlausib : 196|4@1+ (0.0714285714,0) [0E-10|0.9999999996] "Unit_None"  ICAS1_X_Gateway,MRR2023
 SG_ NR_FL_Object_03_ExistProb : 200|7@1+ (0.0078125,0.015625) [0.0156250|1.0000000] "Unit_None"  ICAS1_X_Gateway,MRR2023
 SG_ NR_FL_Object_03_Age : 207|7@1+ (1,0) [0|126] "Unit_None"  ICAS1_X_Gateway,MRR2023
 SG_ NR_FL_Object_03_YawRateAbs : 214|12@1+ (0.001953125,-4) [-4.000000000|3.996093750] "Unit_RadiaPerSecon"  ICAS1_X_Gateway,MRR2023
 SG_ NR_FL_Object_03_YawRateAbsSD : 226|6@1+ (0.003906,0) [0.000000|0.242172] "Unit_RadiaPerSecon"  ICAS1_X_Gateway,MRR2023
 SG_ NR_FL_Object_03_MeasurementState : 232|1@1+ (1.0,0.0) [0.0|1] ""  ICAS1_X_Gateway,MRR2023
 SG_ NR_FL_Object_04_ID : 233|8@1+ (1,0) [1|254] "Unit_None"  ICAS1_X_Gateway,MRR2023
 SG_ NR_FL_Object_04_ReferencePoint : 241|4@1+ (1.0,0.0) [0.0|15] ""  ICAS1_X_Gateway,MRR2023
 SG_ NR_FL_Object_04_PosX : 245|14@1+ (0.03125,-200) [-200.00000|311.93750] "Unit_Meter"  ICAS1_X_Gateway,MRR2023
 SG_ NR_FL_Object_04_PosXSD : 259|8@1+ (0.03125,0) [0.00000|7.93750] "Unit_Meter"  ICAS1_X_Gateway,MRR2023
 SG_ NR_FL_Object_04_PosY : 267|13@1+ (0.03125,-128) [-128.00000|127.93750] "Unit_Meter"  ICAS1_X_Gateway,MRR2023
 SG_ NR_FL_Object_04_PosYSD : 280|8@1+ (0.03125,0) [0.00000|7.93750] "Unit_Meter"  ICAS1_X_Gateway,MRR2023
 SG_ NR_FL_Object_04_vAbsX : 288|12@1+ (0.0625,-128) [-128.0000|127.8750] "Unit_MeterPerSecon"  ICAS1_X_Gateway,MRR2023
 SG_ NR_FL_Object_04_vAbsXSD : 300|6@1+ (0.0625,0) [0.0000|3.8750] "Unit_MeterPerSecon"  ICAS1_X_Gateway,MRR2023
 SG_ NR_FL_Object_04_vAbsY : 306|12@1+ (0.0625,-128) [-128.0000|127.8750] "Unit_MeterPerSecon"  ICAS1_X_Gateway,MRR2023
 SG_ NR_FL_Object_04_vAbsYSD : 318|6@1+ (0.0625,0) [0.0000|3.8750] "Unit_MeterPerSecon"  ICAS1_X_Gateway,MRR2023
 SG_ NR_FL_Object_04_aAbsX : 324|9@1+ (0.0625,-16) [-16.0000|15.8750] "Unit_MeterPerSeconSquar"  ICAS1_X_Gateway,MRR2023
 SG_ NR_FL_Object_04_aAbsXSD : 333|6@1+ (0.0625,0) [0.0000|3.8750] "Unit_MeterPerSeconSquar"  ICAS1_X_Gateway,MRR2023
 SG_ NR_FL_Object_04_aAbsY : 339|9@1+ (0.0625,-16) [-16.0000|15.8750] "Unit_MeterPerSeconSquar"  ICAS1_X_Gateway,MRR2023
 SG_ NR_FL_Object_04_aAbsYSD : 348|6@1+ (0.0625,0) [0.0000|3.8750] "Unit_MeterPerSeconSquar"  ICAS1_X_Gateway,MRR2023
 SG_ NR_FL_Object_04_DynamicState : 354|2@1+ (1.0,0.0) [0.0|3] ""  ICAS1_X_Gateway,MRR2023
 SG_ NR_FL_Object_04_YawAngle : 356|12@1+ (0.001953125,-4) [-4.000000000|3.996093750] "Unit_Radia"  ICAS1_X_Gateway,MRR2023
 SG_ NR_FL_Object_04_YawAngleSD : 368|9@1+ (0.001953125,0) [0E-9|0.996093750] "Unit_Radia"  ICAS1_X_Gateway,MRR2023
 SG_ NR_FL_Object_04_Width : 377|8@1+ (0.03125,0) [0.00000|7.93750] "Unit_Meter"  ICAS1_X_Gateway,MRR2023
 SG_ NR_FL_Object_04_WidthSD : 385|7@1+ (0.03125,0) [0.00000|3.93750] "Unit_Meter"  ICAS1_X_Gateway,MRR2023
 SG_ NR_FL_Object_04_Length : 392|10@1+ (0.03125,0) [0.00000|31.93750] "Unit_Meter"  ICAS1_X_Gateway,MRR2023
 SG_ NR_FL_Object_04_LengthSD : 402|7@1+ (0.03125,0) [0.00000|3.93750] "Unit_Meter"  ICAS1_X_Gateway,MRR2023
 SG_ NR_FL_Object_04_Class : 409|4@1+ (1.0,0.0) [0.0|15] ""  ICAS1_X_Gateway,MRR2023
 SG_ NR_FL_Object_04_ClassPlausib : 413|4@1+ (0.0714285714,0) [0E-10|0.9999999996] "Unit_None"  ICAS1_X_Gateway,MRR2023
 SG_ NR_FL_Object_04_ExistProb : 417|7@1+ (0.0078125,0.015625) [0.0156250|1.0000000] "Unit_None"  ICAS1_X_Gateway,MRR2023
 SG_ NR_FL_Object_04_Age : 424|7@1+ (1,0) [0|126] "Unit_None"  ICAS1_X_Gateway,MRR2023
 SG_ NR_FL_Object_04_YawRateAbs : 431|12@1+ (0.001953125,-4) [-4.000000000|3.996093750] "Unit_RadiaPerSecon"  ICAS1_X_Gateway,MRR2023
 SG_ NR_FL_Object_04_YawRateAbsSD : 443|6@1+ (0.003906,0) [0.000000|0.242172] "Unit_RadiaPerSecon"  ICAS1_X_Gateway,MRR2023
 SG_ NR_FL_Object_04_MeasurementState : 449|1@1+ (1.0,0.0) [0.0|1] ""  ICAS1_X_Gateway,MRR2023
 SG_ SOK_NR_FL_Object_03_04_Signatur : 480|32@1+ (1,0) [0|4294967295] ""  ICAS1_X_Gateway

BO_ 2331595778 NR_FL_Object_05_06: 64 NR_1
 SG_ NR_FL_Object_05_06_CRC : 0|8@1+ (1,0) [0|255] ""  ICAS1_X_Gateway,MRR2023
 SG_ NR_FL_Object_05_06_BZ : 8|4@1+ (1,0) [0|15] ""  ICAS1_X_Gateway,MRR2023
 SG_ NR_FL_Object_05_06_BlockID_01 : 12|4@1+ (1,0) [0|15] "Unit_None"  ICAS1_X_Gateway,MRR2023
 SG_ NR_FL_Object_05_ID : 16|8@1+ (1,0) [1|254] "Unit_None"  ICAS1_X_Gateway,MRR2023
 SG_ NR_FL_Object_05_ReferencePoint : 24|4@1+ (1.0,0.0) [0.0|15] ""  ICAS1_X_Gateway,MRR2023
 SG_ NR_FL_Object_05_PosX : 28|14@1+ (0.03125,-200) [-200.00000|311.93750] "Unit_Meter"  ICAS1_X_Gateway,MRR2023
 SG_ NR_FL_Object_05_PosXSD : 42|8@1+ (0.03125,0) [0.00000|7.93750] "Unit_Meter"  ICAS1_X_Gateway,MRR2023
 SG_ NR_FL_Object_05_PosY : 50|13@1+ (0.03125,-128) [-128.00000|127.93750] "Unit_Meter"  ICAS1_X_Gateway,MRR2023
 SG_ NR_FL_Object_05_PosYSD : 63|8@1+ (0.03125,0) [0.00000|7.93750] "Unit_Meter"  ICAS1_X_Gateway,MRR2023
 SG_ NR_FL_Object_05_vAbsX : 71|12@1+ (0.0625,-128) [-128.0000|127.8750] "Unit_MeterPerSecon"  ICAS1_X_Gateway,MRR2023
 SG_ NR_FL_Object_05_vAbsXSD : 83|6@1+ (0.0625,0) [0.0000|3.8750] "Unit_MeterPerSecon"  ICAS1_X_Gateway,MRR2023
 SG_ NR_FL_Object_05_vAbsY : 89|12@1+ (0.0625,-128) [-128.0000|127.8750] "Unit_MeterPerSecon"  ICAS1_X_Gateway,MRR2023
 SG_ NR_FL_Object_05_vAbsYSD : 101|6@1+ (0.0625,0) [0.0000|3.8750] "Unit_MeterPerSecon"  ICAS1_X_Gateway,MRR2023
 SG_ NR_FL_Object_05_aAbsX : 107|9@1+ (0.0625,-16) [-16.0000|15.8750] "Unit_MeterPerSeconSquar"  ICAS1_X_Gateway,MRR2023
 SG_ NR_FL_Object_05_aAbsXSD : 116|6@1+ (0.0625,0) [0.0000|3.8750] "Unit_MeterPerSeconSquar"  ICAS1_X_Gateway,MRR2023
 SG_ NR_FL_Object_05_aAbsY : 122|9@1+ (0.0625,-16) [-16.0000|15.8750] "Unit_MeterPerSeconSquar"  ICAS1_X_Gateway,MRR2023
 SG_ NR_FL_Object_05_aAbsYSD : 131|6@1+ (0.0625,0) [0.0000|3.8750] "Unit_MeterPerSeconSquar"  ICAS1_X_Gateway,MRR2023
 SG_ NR_FL_Object_05_DynamicState : 137|2@1+ (1.0,0.0) [0.0|3] ""  ICAS1_X_Gateway,MRR2023
 SG_ NR_FL_Object_05_YawAngle : 139|12@1+ (0.001953125,-4) [-4.000000000|3.996093750] "Unit_Radia"  ICAS1_X_Gateway,MRR2023
 SG_ NR_FL_Object_05_YawAngleSD : 151|9@1+ (0.001953125,0) [0E-9|0.996093750] "Unit_Radia"  ICAS1_X_Gateway,MRR2023
 SG_ NR_FL_Object_05_Width : 160|8@1+ (0.03125,0) [0.00000|7.93750] "Unit_Meter"  ICAS1_X_Gateway,MRR2023
 SG_ NR_FL_Object_05_WidthSD : 168|7@1+ (0.03125,0) [0.00000|3.93750] "Unit_Meter"  ICAS1_X_Gateway,MRR2023
 SG_ NR_FL_Object_05_Length : 175|10@1+ (0.03125,0) [0.00000|31.93750] "Unit_Meter"  ICAS1_X_Gateway,MRR2023
 SG_ NR_FL_Object_05_LengthSD : 185|7@1+ (0.03125,0) [0.00000|3.93750] "Unit_Meter"  ICAS1_X_Gateway,MRR2023
 SG_ NR_FL_Object_05_Class : 192|4@1+ (1.0,0.0) [0.0|15] ""  ICAS1_X_Gateway,MRR2023
 SG_ NR_FL_Object_05_ClassPlausib : 196|4@1+ (0.0714285714,0) [0E-10|0.9999999996] "Unit_None"  ICAS1_X_Gateway,MRR2023
 SG_ NR_FL_Object_05_ExistProb : 200|7@1+ (0.0078125,0.015625) [0.0156250|1.0000000] "Unit_None"  ICAS1_X_Gateway,MRR2023
 SG_ NR_FL_Object_05_Age : 207|7@1+ (1,0) [0|126] "Unit_None"  ICAS1_X_Gateway,MRR2023
 SG_ NR_FL_Object_05_YawRateAbs : 214|12@1+ (0.001953125,-4) [-4.000000000|3.996093750] "Unit_RadiaPerSecon"  ICAS1_X_Gateway,MRR2023
 SG_ NR_FL_Object_05_YawRateAbsSD : 226|6@1+ (0.003906,0) [0.000000|0.242172] "Unit_RadiaPerSecon"  ICAS1_X_Gateway,MRR2023
 SG_ NR_FL_Object_05_MeasurementState : 232|1@1+ (1.0,0.0) [0.0|1] ""  ICAS1_X_Gateway,MRR2023
 SG_ NR_FL_Object_06_ID : 233|8@1+ (1,0) [1|254] "Unit_None"  ICAS1_X_Gateway,MRR2023
 SG_ NR_FL_Object_06_ReferencePoint : 241|4@1+ (1.0,0.0) [0.0|15] ""  ICAS1_X_Gateway,MRR2023
 SG_ NR_FL_Object_06_PosX : 245|14@1+ (0.03125,-200) [-200.00000|311.93750] "Unit_Meter"  ICAS1_X_Gateway,MRR2023
 SG_ NR_FL_Object_06_PosXSD : 259|8@1+ (0.03125,0) [0.00000|7.93750] "Unit_Meter"  ICAS1_X_Gateway,MRR2023
 SG_ NR_FL_Object_06_PosY : 267|13@1+ (0.03125,-128) [-128.00000|127.93750] "Unit_Meter"  ICAS1_X_Gateway,MRR2023
 SG_ NR_FL_Object_06_PosYSD : 280|8@1+ (0.03125,0) [0.00000|7.93750] "Unit_Meter"  ICAS1_X_Gateway,MRR2023
 SG_ NR_FL_Object_06_vAbsX : 288|12@1+ (0.0625,-128) [-128.0000|127.8750] "Unit_MeterPerSecon"  ICAS1_X_Gateway,MRR2023
 SG_ NR_FL_Object_06_vAbsXSD : 300|6@1+ (0.0625,0) [0.0000|3.8750] "Unit_MeterPerSecon"  ICAS1_X_Gateway,MRR2023
 SG_ NR_FL_Object_06_vAbsY : 306|12@1+ (0.0625,-128) [-128.0000|127.8750] "Unit_MeterPerSecon"  ICAS1_X_Gateway,MRR2023
 SG_ NR_FL_Object_06_vAbsYSD : 318|6@1+ (0.0625,0) [0.0000|3.8750] "Unit_MeterPerSecon"  ICAS1_X_Gateway,MRR2023
 SG_ NR_FL_Object_06_aAbsX : 324|9@1+ (0.0625,-16) [-16.0000|15.8750] "Unit_MeterPerSeconSquar"  ICAS1_X_Gateway,MRR2023
 SG_ NR_FL_Object_06_aAbsXSD : 333|6@1+ (0.0625,0) [0.0000|3.8750] "Unit_MeterPerSeconSquar"  ICAS1_X_Gateway,MRR2023
 SG_ NR_FL_Object_06_aAbsY : 339|9@1+ (0.0625,-16) [-16.0000|15.8750] "Unit_MeterPerSeconSquar"  ICAS1_X_Gateway,MRR2023
 SG_ NR_FL_Object_06_aAbsYSD : 348|6@1+ (0.0625,0) [0.0000|3.8750] "Unit_MeterPerSeconSquar"  ICAS1_X_Gateway,MRR2023
 SG_ NR_FL_Object_06_DynamicState : 354|2@1+ (1.0,0.0) [0.0|3] ""  ICAS1_X_Gateway,MRR2023
 SG_ NR_FL_Object_06_YawAngle : 356|12@1+ (0.001953125,-4) [-4.000000000|3.996093750] "Unit_Radia"  ICAS1_X_Gateway,MRR2023
 SG_ NR_FL_Object_06_YawAngleSD : 368|9@1+ (0.001953125,0) [0E-9|0.996093750] "Unit_Radia"  ICAS1_X_Gateway,MRR2023
 SG_ NR_FL_Object_06_Width : 377|8@1+ (0.03125,0) [0.00000|7.93750] "Unit_Meter"  ICAS1_X_Gateway,MRR2023
 SG_ NR_FL_Object_06_WidthSD : 385|7@1+ (0.03125,0) [0.00000|3.93750] "Unit_Meter"  ICAS1_X_Gateway,MRR2023
 SG_ NR_FL_Object_06_Length : 392|10@1+ (0.03125,0) [0.00000|31.93750] "Unit_Meter"  ICAS1_X_Gateway,MRR2023
 SG_ NR_FL_Object_06_LengthSD : 402|7@1+ (0.03125,0) [0.00000|3.93750] "Unit_Meter"  ICAS1_X_Gateway,MRR2023
 SG_ NR_FL_Object_06_Class : 409|4@1+ (1.0,0.0) [0.0|15] ""  ICAS1_X_Gateway,MRR2023
 SG_ NR_FL_Object_06_ClassPlausib : 413|4@1+ (0.0714285714,0) [0E-10|0.9999999996] "Unit_None"  ICAS1_X_Gateway,MRR2023
 SG_ NR_FL_Object_06_ExistProb : 417|7@1+ (0.0078125,0.015625) [0.0156250|1.0000000] "Unit_None"  ICAS1_X_Gateway,MRR2023
 SG_ NR_FL_Object_06_Age : 424|7@1+ (1,0) [0|126] "Unit_None"  ICAS1_X_Gateway,MRR2023
 SG_ NR_FL_Object_06_YawRateAbs : 431|12@1+ (0.001953125,-4) [-4.000000000|3.996093750] "Unit_RadiaPerSecon"  ICAS1_X_Gateway,MRR2023
 SG_ NR_FL_Object_06_YawRateAbsSD : 443|6@1+ (0.003906,0) [0.000000|0.242172] "Unit_RadiaPerSecon"  ICAS1_X_Gateway,MRR2023
 SG_ NR_FL_Object_06_MeasurementState : 449|1@1+ (1.0,0.0) [0.0|1] ""  ICAS1_X_Gateway,MRR2023
 SG_ SOK_NR_FL_Object_05_06_Signatur : 480|32@1+ (1,0) [0|4294967295] ""  ICAS1_X_Gateway

BO_ 2331595779 NR_FL_Object_07_08: 64 NR_1
 SG_ NR_FL_Object_07_08_CRC : 0|8@1+ (1,0) [0|255] ""  ICAS1_X_Gateway,MRR2023
 SG_ NR_FL_Object_07_08_BZ : 8|4@1+ (1,0) [0|15] ""  ICAS1_X_Gateway,MRR2023
 SG_ NR_FL_Object_07_08_BlockID_01 : 12|4@1+ (1,0) [0|15] "Unit_None"  ICAS1_X_Gateway,MRR2023
 SG_ NR_FL_Object_07_ID : 16|8@1+ (1,0) [1|254] "Unit_None"  ICAS1_X_Gateway,MRR2023
 SG_ NR_FL_Object_07_ReferencePoint : 24|4@1+ (1.0,0.0) [0.0|15] ""  ICAS1_X_Gateway,MRR2023
 SG_ NR_FL_Object_07_PosX : 28|14@1+ (0.03125,-200) [-200.00000|311.93750] "Unit_Meter"  ICAS1_X_Gateway,MRR2023
 SG_ NR_FL_Object_07_PosXSD : 42|8@1+ (0.03125,0) [0.00000|7.93750] "Unit_Meter"  ICAS1_X_Gateway,MRR2023
 SG_ NR_FL_Object_07_PosY : 50|13@1+ (0.03125,-128) [-128.00000|127.93750] "Unit_Meter"  ICAS1_X_Gateway,MRR2023
 SG_ NR_FL_Object_07_PosYSD : 63|8@1+ (0.03125,0) [0.00000|7.93750] "Unit_Meter"  ICAS1_X_Gateway,MRR2023
 SG_ NR_FL_Object_07_vAbsX : 71|12@1+ (0.0625,-128) [-128.0000|127.8750] "Unit_MeterPerSecon"  ICAS1_X_Gateway,MRR2023
 SG_ NR_FL_Object_07_vAbsXSD : 83|6@1+ (0.0625,0) [0.0000|3.8750] "Unit_MeterPerSecon"  ICAS1_X_Gateway,MRR2023
 SG_ NR_FL_Object_07_vAbsY : 89|12@1+ (0.0625,-128) [-128.0000|127.8750] "Unit_MeterPerSecon"  ICAS1_X_Gateway,MRR2023
 SG_ NR_FL_Object_07_vAbsYSD : 101|6@1+ (0.0625,0) [0.0000|3.8750] "Unit_MeterPerSecon"  ICAS1_X_Gateway,MRR2023
 SG_ NR_FL_Object_07_aAbsX : 107|9@1+ (0.0625,-16) [-16.0000|15.8750] "Unit_MeterPerSeconSquar"  ICAS1_X_Gateway,MRR2023
 SG_ NR_FL_Object_07_aAbsXSD : 116|6@1+ (0.0625,0) [0.0000|3.8750] "Unit_MeterPerSeconSquar"  ICAS1_X_Gateway,MRR2023
 SG_ NR_FL_Object_07_aAbsY : 122|9@1+ (0.0625,-16) [-16.0000|15.8750] "Unit_MeterPerSeconSquar"  ICAS1_X_Gateway,MRR2023
 SG_ NR_FL_Object_07_aAbsYSD : 131|6@1+ (0.0625,0) [0.0000|3.8750] "Unit_MeterPerSeconSquar"  ICAS1_X_Gateway,MRR2023
 SG_ NR_FL_Object_07_DynamicState : 137|2@1+ (1.0,0.0) [0.0|3] ""  ICAS1_X_Gateway,MRR2023
 SG_ NR_FL_Object_07_YawAngle : 139|12@1+ (0.001953125,-4) [-4.000000000|3.996093750] "Unit_Radia"  ICAS1_X_Gateway,MRR2023
 SG_ NR_FL_Object_07_YawAngleSD : 151|9@1+ (0.001953125,0) [0E-9|0.996093750] "Unit_Radia"  ICAS1_X_Gateway,MRR2023
 SG_ NR_FL_Object_07_Width : 160|8@1+ (0.03125,0) [0.00000|7.93750] "Unit_Meter"  ICAS1_X_Gateway,MRR2023
 SG_ NR_FL_Object_07_WidthSD : 168|7@1+ (0.03125,0) [0.00000|3.93750] "Unit_Meter"  ICAS1_X_Gateway,MRR2023
 SG_ NR_FL_Object_07_Length : 175|10@1+ (0.03125,0) [0.00000|31.93750] "Unit_Meter"  ICAS1_X_Gateway,MRR2023
 SG_ NR_FL_Object_07_LengthSD : 185|7@1+ (0.03125,0) [0.00000|3.93750] "Unit_Meter"  ICAS1_X_Gateway,MRR2023
 SG_ NR_FL_Object_07_Class : 192|4@1+ (1.0,0.0) [0.0|15] ""  ICAS1_X_Gateway,MRR2023
 SG_ NR_FL_Object_07_ClassPlausib : 196|4@1+ (0.0714285714,0) [0E-10|0.9999999996] "Unit_None"  ICAS1_X_Gateway,MRR2023
 SG_ NR_FL_Object_07_ExistProb : 200|7@1+ (0.0078125,0.015625) [0.0156250|1.0000000] "Unit_None"  ICAS1_X_Gateway,MRR2023
 SG_ NR_FL_Object_07_Age : 207|7@1+ (1,0) [0|126] "Unit_None"  ICAS1_X_Gateway,MRR2023
 SG_ NR_FL_Object_07_YawRateAbs : 214|12@1+ (0.001953125,-4) [-4.000000000|3.996093750] "Unit_RadiaPerSecon"  ICAS1_X_Gateway,MRR2023
 SG_ NR_FL_Object_07_YawRateAbsSD : 226|6@1+ (0.003906,0) [0.000000|0.242172] "Unit_RadiaPerSecon"  ICAS1_X_Gateway,MRR2023
 SG_ NR_FL_Object_07_MeasurementState : 232|1@1+ (1.0,0.0) [0.0|1] ""  ICAS1_X_Gateway,MRR2023
 SG_ NR_FL_Object_08_ID : 233|8@1+ (1,0) [1|254] "Unit_None"  ICAS1_X_Gateway,MRR2023
 SG_ NR_FL_Object_08_ReferencePoint : 241|4@1+ (1.0,0.0) [0.0|15] ""  ICAS1_X_Gateway,MRR2023
 SG_ NR_FL_Object_08_PosX : 245|14@1+ (0.03125,-200) [-200.00000|311.93750] "Unit_Meter"  ICAS1_X_Gateway,MRR2023
 SG_ NR_FL_Object_08_PosXSD : 259|8@1+ (0.03125,0) [0.00000|7.93750] "Unit_Meter"  ICAS1_X_Gateway,MRR2023
 SG_ NR_FL_Object_08_PosY : 267|13@1+ (0.03125,-128) [-128.00000|127.93750] "Unit_Meter"  ICAS1_X_Gateway,MRR2023
 SG_ NR_FL_Object_08_PosYSD : 280|8@1+ (0.03125,0) [0.00000|7.93750] "Unit_Meter"  ICAS1_X_Gateway,MRR2023
 SG_ NR_FL_Object_08_vAbsX : 288|12@1+ (0.0625,-128) [-128.0000|127.8750] "Unit_MeterPerSecon"  ICAS1_X_Gateway,MRR2023
 SG_ NR_FL_Object_08_vAbsXSD : 300|6@1+ (0.0625,0) [0.0000|3.8750] "Unit_MeterPerSecon"  ICAS1_X_Gateway,MRR2023
 SG_ NR_FL_Object_08_vAbsY : 306|12@1+ (0.0625,-128) [-128.0000|127.8750] "Unit_MeterPerSecon"  ICAS1_X_Gateway,MRR2023
 SG_ NR_FL_Object_08_vAbsYSD : 318|6@1+ (0.0625,0) [0.0000|3.8750] "Unit_MeterPerSecon"  ICAS1_X_Gateway,MRR2023
 SG_ NR_FL_Object_08_aAbsX : 324|9@1+ (0.0625,-16) [-16.0000|15.8750] "Unit_MeterPerSeconSquar"  ICAS1_X_Gateway,MRR2023
 SG_ NR_FL_Object_08_aAbsXSD : 333|6@1+ (0.0625,0) [0.0000|3.8750] "Unit_MeterPerSeconSquar"  ICAS1_X_Gateway,MRR2023
 SG_ NR_FL_Object_08_aAbsY : 339|9@1+ (0.0625,-16) [-16.0000|15.8750] "Unit_MeterPerSeconSquar"  ICAS1_X_Gateway,MRR2023
 SG_ NR_FL_Object_08_aAbsYSD : 348|6@1+ (0.0625,0) [0.0000|3.8750] "Unit_MeterPerSeconSquar"  ICAS1_X_Gateway,MRR2023
 SG_ NR_FL_Object_08_DynamicState : 354|2@1+ (1.0,0.0) [0.0|3] ""  ICAS1_X_Gateway,MRR2023
 SG_ NR_FL_Object_08_YawAngle : 356|12@1+ (0.001953125,-4) [-4.000000000|3.996093750] "Unit_Radia"  ICAS1_X_Gateway,MRR2023
 SG_ NR_FL_Object_08_YawAngleSD : 368|9@1+ (0.001953125,0) [0E-9|0.996093750] "Unit_Radia"  ICAS1_X_Gateway,MRR2023
 SG_ NR_FL_Object_08_Width : 377|8@1+ (0.03125,0) [0.00000|7.93750] "Unit_Meter"  ICAS1_X_Gateway,MRR2023
 SG_ NR_FL_Object_08_WidthSD : 385|7@1+ (0.03125,0) [0.00000|3.93750] "Unit_Meter"  ICAS1_X_Gateway,MRR2023
 SG_ NR_FL_Object_08_Length : 392|10@1+ (0.03125,0) [0.00000|31.93750] "Unit_Meter"  ICAS1_X_Gateway,MRR2023
 SG_ NR_FL_Object_08_LengthSD : 402|7@1+ (0.03125,0) [0.00000|3.93750] "Unit_Meter"  ICAS1_X_Gateway,MRR2023
 SG_ NR_FL_Object_08_Class : 409|4@1+ (1.0,0.0) [0.0|15] ""  ICAS1_X_Gateway,MRR2023
 SG_ NR_FL_Object_08_ClassPlausib : 413|4@1+ (0.0714285714,0) [0E-10|0.9999999996] "Unit_None"  ICAS1_X_Gateway,MRR2023
 SG_ NR_FL_Object_08_ExistProb : 417|7@1+ (0.0078125,0.015625) [0.0156250|1.0000000] "Unit_None"  ICAS1_X_Gateway,MRR2023
 SG_ NR_FL_Object_08_Age : 424|7@1+ (1,0) [0|126] "Unit_None"  ICAS1_X_Gateway,MRR2023
 SG_ NR_FL_Object_08_YawRateAbs : 431|12@1+ (0.001953125,-4) [-4.000000000|3.996093750] "Unit_RadiaPerSecon"  ICAS1_X_Gateway,MRR2023
 SG_ NR_FL_Object_08_YawRateAbsSD : 443|6@1+ (0.003906,0) [0.000000|0.242172] "Unit_RadiaPerSecon"  ICAS1_X_Gateway,MRR2023
 SG_ NR_FL_Object_08_MeasurementState : 449|1@1+ (1.0,0.0) [0.0|1] ""  ICAS1_X_Gateway,MRR2023
 SG_ SOK_NR_FL_Object_07_08_Signatur : 480|32@1+ (1,0) [0|4294967295] ""  ICAS1_X_Gateway

BO_TX_BU_ 2600468567 :FASFrontradar,MRR2023;
BO_TX_BU_ 2600468559 :MFK,MFK120;

CM_ SG_ 2600468567 NM_ACC_CAB_V15 "CAB = Clusteraktivbits (V15)";
CM_ SG_ 2600468567 NM_ACC_Car_Wakeup "Car Wakeup (Gateway wertet aus)";
CM_ SG_ 2600468567 NM_ACC_CBV_AWB "Das Signal ist zu setzen, wenn das SG aktiv den Bus geweckt hat
0 = Passiver_WakeUp = SG hat das Netzwerk nicht aktiv geweckt
1 = Akitiver_WakeUp = SG hat das Netzwerk aktiv geweckt";
CM_ SG_ 2600468567 NM_ACC_CBV_CRI "Das Signal ist dauerhaft gesetzt, wenn das NM-Layout Cluster- Anforderungen enthält";
CM_ SG_ 2600468567 NM_ACC_NM_aktiv_Diagnose "Diagnose befindet sich nach VW80124 in einer NonDefaultDiagnostic-Session, z.B. ExtendedDiagnostic-Session";
CM_ SG_ 2600468567 NM_ACC_NM_aktiv_KL15 "Steuergerät hat KL15-EIN erkannt";
CM_ SG_ 2600468567 NM_ACC_NM_aktiv_Tmin "Mindestaktivzeit ist noch nicht abgelaufen (bei jedem Weckereignis wird die Mindestaktivzeit neu gestartet)";
CM_ SG_ 2600468567 NM_ACC_NM_State "1 = Zustand Repeat Message (<-- Bus-Sleep Mode)
2 = Zustand Repeat Message (<-- Prepare Bus-Sleep Mode)
4 = Zustand Normal Operation (<-- Repeat Message)
8 = Zustand Normal Operation (<-- Ready Sleep)";
CM_ SG_ 2600468567 NM_ACC_UDS_CC "Funktionseinschränkung aufgrund aktivem UDS-Communication Control, siehe VW80124";

CM_ SG_ 2600468496 NM_Gateway_CAB_V15 "CAB = Clusteraktivbits (V15)";
CM_ SG_ 2600468496 NM_Gateway_Car_Wakeup "Car Wakeup (Subbusmaster wertet aus)

MQB: 
-Diagnose- oder Komponentenschutzmaster-Funktion weckt den schlafenden Subbus (z.B. MOST)

E3_Volumen:
- Diagnose aktiv -aktive Diagnosekommunikation am OBD-Stecker

MQBw_Baseline:
- Diagnose aktiv -akt";
CM_ SG_ 2600468496 NM_Gateway_CBV_AWB "Das Signal ist zu setzen, wenn das SG aktiv den Bus geweckt hat
0 = Passiver_WakeUp = SG hat das Netzwerk nicht aktiv geweckt
1 = Akitiver_WakeUp = SG hat das Netzwerk aktiv geweckt";
CM_ SG_ 2600468496 NM_Gateway_CBV_CRI "Das Signal ist dauerhaft gesetzt, wenn das NM-Layout Cluster- Anforderungen enthält";
CM_ SG_ 2600468496 NM_Gateway_NM_aktiv_CAB "Nachlauf aufgrund Kopplung mehrerer Busse. z.B. K-CAN und K2-CAN, Clusteranforderung über CAB und Car Wakeup Anforderung.";
CM_ SG_ 2600468496 NM_Gateway_NM_aktiv_Diagnose "Diagnose befindet sich nach VW80124 in einer NonDefaultDiagnostic-Session, z.B. ExtendedDiagnostic-Session";
CM_ SG_ 2600468496 NM_Gateway_NM_aktiv_Energie "Dieser Bus wird auf Grund einer Aktivität der Funktion EMHLR, HVEM, Dynamic Charging POI, Charging-Management-Server oder Extended Charging Monitoring wachgehalten";
CM_ SG_ 2600468496 NM_Gateway_NM_aktiv_FoD "Dieser Bus wird auf Grund einer Aktivität der Function on Demand wachgehalten";
CM_ SG_ 2600468496 NM_Gateway_NM_aktiv_IAA_PSO "Dieser Bus wird auf Grund einer Aktivität der Personalisierung wachgehalten";
CM_ SG_ 2600468496 NM_Gateway_NM_aktiv_Kessy "Dieser Bus wird auf Grund einer Aktivität der Funktion Kessy wachgehalten";
CM_ SG_ 2600468496 NM_Gateway_NM_aktiv_KL15 "Steuergerät hat KL15-EIN erkannt";
CM_ SG_ 2600468496 NM_Gateway_NM_aktiv_KS "Dieser Bus wird auf Grund einer Aktivität des Komponentenschutzes wachgehalten";
CM_ SG_ 2600468496 NM_Gateway_NM_aktiv_Licht "Dieser Bus wird auf Grund einer Aktivität der Funktion Dimmung oder Standard Außenlicht wachgehalten";
CM_ SG_ 2600468496 NM_Gateway_NM_aktiv_PaCo "Dieser Bus wird auf Grund einer Aktivität des Park Koordinators wachgehalten";
CM_ SG_ 2600468496 NM_Gateway_NM_aktiv_RTM "Dieser Bus wird auf Grund einer Aktivität des Real Time Monitors wachgehalten";
CM_ SG_ 2600468496 NM_Gateway_NM_aktiv_Standklima "Dieser Bus wird auf Grund einer Aktivität der Standklimatisierung wachgehalten";
CM_ SG_ 2600468496 NM_Gateway_NM_aktiv_Tmin "Mindestaktivzeit ist noch nicht abgelaufen (bei jedem Weckereignis wird die Mindestaktivzeit neu gestartet)";
CM_ SG_ 2600468496 NM_Gateway_NM_aktiv_USS "Dieser Bus wird auf Grund einer Aktivität des User State Servers wachgehalten";
CM_ SG_ 2600468496 NM_Gateway_NM_aktiv_ZM "Dieser Bus wird auf Grund einer Aktivität des Zeitmasters wachgehalten";
CM_ SG_ 2600468496 NM_Gateway_NM_aktiv_ZV "Dieser Bus wird auf Grund einer Aktivität der Zentralverriegelung wachgehalten";
CM_ SG_ 2600468496 NM_Gateway_NM_State "1 = Zustand Repeat Message (<-- Bus-Sleep Mode)
2 = Zustand Repeat Message (<-- Prepare Bus-Sleep Mode)
4 = Zustand Normal Operation (<-- Repeat Message)
8 = Zustand Normal Operation (<-- Ready Sleep)";
CM_ SG_ 2600468496 NM_Gateway_UDS_CC "Funktionseinschränkung aufgrund aktivem UDS-Communication Control, siehe VW80124";

CM_ SG_ 2600468559 NM_Kamera_CAB_V15 "CAB = Clusteraktivbits (V15)";
CM_ SG_ 2600468559 NM_Kamera_Car_Wakeup "Car Wakeup (Gateway wertet aus)";
CM_ SG_ 2600468559 NM_Kamera_CBV_AWB "Das Signal ist zu setzen, wenn das SG aktiv den Bus geweckt hat
0 = Passiver_WakeUp = SG hat das Netzwerk nicht aktiv geweckt
1 = Akitiver_WakeUp = SG hat das Netzwerk aktiv geweckt";
CM_ SG_ 2600468559 NM_Kamera_CBV_CRI "Das Signal ist dauerhaft gesetzt, wenn das NM-Layout Cluster- Anforderungen enthält";
CM_ SG_ 2600468559 NM_Kamera_NM_aktiv_Diagnose "Diagnose befindet sich nach VW80124 in einer NonDefaultDiagnostic-Session, z.B. ExtendedDiagnostic-Session";
CM_ SG_ 2600468559 NM_Kamera_NM_aktiv_KL15 "Steuergerät hat KL15-EIN erkannt";
CM_ SG_ 2600468559 NM_Kamera_NM_aktiv_Tmin "Mindestaktivzeit ist noch nicht abgelaufen (bei jedem Weckereignis wird die Mindestaktivzeit neu gestartet)";
CM_ SG_ 2600468559 NM_Kamera_NM_State "1 = Zustand Repeat Message (<-- Bus-Sleep Mode)
2 = Zustand Repeat Message (<-- Prepare Bus-Sleep Mode)
4 = Zustand Normal Operation (<-- Repeat Message)
8 = Zustand Normal Operation (<-- Ready Sleep)";
CM_ SG_ 2600468559 NM_Kamera_UDS_CC "Funktionseinschränkung aufgrund aktivem UDS-Communication Control, siehe VW80124";

CM_ SG_ 2600468667 NM_NR_01_CAB_V15 "CAB = Clusteraktivbits (V15)";
CM_ SG_ 2600468667 NM_NR_01_Car_Wakeup "Car Wakeup (Gateway wertet aus)";
CM_ SG_ 2600468667 NM_NR_01_CBV_AWB "Das Signal ist zu setzen, wenn das SG aktiv den Bus geweckt hat
0 = Passiver_WakeUp = SG hat das Netzwerk nicht aktiv geweckt
1 = Akitiver_WakeUp = SG hat das Netzwerk aktiv geweckt";
CM_ SG_ 2600468667 NM_NR_01_CBV_CRI "Das Signal ist dauerhaft gesetzt, wenn das NM-Layout Cluster- Anforderungen enthält";
CM_ SG_ 2600468667 NM_NR_01_NM_aktiv_Diagnose "Diagnose befindet sich nach VW80124 in einer NonDefaultDiagnostic-Session, z.B. ExtendedDiagnostic-Session";
CM_ SG_ 2600468667 NM_NR_01_NM_aktiv_KL15 "Steuergerät hat KL15-EIN erkannt";
CM_ SG_ 2600468667 NM_NR_01_NM_aktiv_Tmin "Mindestaktivzeit ist noch nicht abgelaufen (bei jedem Weckereignis wird die Mindestaktivzeit neu gestartet)";
CM_ SG_ 2600468667 NM_NR_01_NM_State "1 = Zustand Repeat Message (<-- Bus-Sleep Mode)
2 = Zustand Repeat Message (<-- Prepare Bus-Sleep Mode)
4 = Zustand Normal Operation (<-- Repeat Message)
8 = Zustand Normal Operation (<-- Ready Sleep)";
CM_ SG_ 2600468667 NM_NR_01_UDS_CC "Funktionseinschränkung aufgrund aktivem UDS-Communication Control, siehe VW80124";

CM_ SG_ 2600468668 NM_NR_02_CAB_V15 "CAB = Clusteraktivbits (V15)";
CM_ SG_ 2600468668 NM_NR_02_Car_Wakeup "Car Wakeup (Gateway wertet aus)";
CM_ SG_ 2600468668 NM_NR_02_CBV_AWB "Das Signal ist zu setzen, wenn das SG aktiv den Bus geweckt hat
0 = Passiver_WakeUp = SG hat das Netzwerk nicht aktiv geweckt
1 = Akitiver_WakeUp = SG hat das Netzwerk aktiv geweckt";
CM_ SG_ 2600468668 NM_NR_02_CBV_CRI "Das Signal ist dauerhaft gesetzt, wenn das NM-Layout Cluster- Anforderungen enthält";
CM_ SG_ 2600468668 NM_NR_02_NM_aktiv_Diagnose "Diagnose befindet sich nach VW80124 in einer NonDefaultDiagnostic-Session, z.B. ExtendedDiagnostic-Session";
CM_ SG_ 2600468668 NM_NR_02_NM_aktiv_KL15 "Steuergerät hat KL15-EIN erkannt";
CM_ SG_ 2600468668 NM_NR_02_NM_aktiv_Tmin "Mindestaktivzeit ist noch nicht abgelaufen (bei jedem Weckereignis wird die Mindestaktivzeit neu gestartet)";
CM_ SG_ 2600468668 NM_NR_02_NM_State "1 = Zustand Repeat Message (<-- Bus-Sleep Mode)
2 = Zustand Repeat Message (<-- Prepare Bus-Sleep Mode)
4 = Zustand Normal Operation (<-- Repeat Message)
8 = Zustand Normal Operation (<-- Ready Sleep)";
CM_ SG_ 2600468668 NM_NR_02_UDS_CC "Funktionseinschränkung aufgrund aktivem UDS-Communication Control, siehe VW80124";

CM_ SG_ 2589283909 NR_01_CAL_Text_Data_1 "Information regarding the Initial sensor calibration of the NanoRadar in the Plant and Service do be displayed via HMI. Formatted as UTF-8 String, part 1 (Characters 0 to 6)";
CM_ SG_ 2589283909 NR_01_CAL_Text_Request "Triggers the Display via HMI of the characters in the signals  NR_01_CAL_Text_Data_<1 to 3> for the NanoRadar";

CM_ SG_ 2589283910 NR_01_CAL_Text_Data_2 "Information regarding the Initial sensor calibration of the NanoRadar in the Plant and Service do be displayed via HMI. Formatted as UTF-8 String, part 2 (Characters 7 to 14)";

CM_ SG_ 2589283911 NR_01_CAL_Text_Data_3 "Information regarding the Initial sensor calibration of the NanoRadar in the Plant and Service do be displayed via HMI. Formatted as UTF-8 String, part 3 (Characters 15 to 22)";

CM_ SG_ 2527679889 NR_02_CAL_LgtLimV_StAcv "Activation demand for velocity limitation for initial Sensor Calibration of the NanoRadar";
CM_ SG_ 2527679889 NR_02_CAL_LgtLimV_VDmd "Activation demand for velocity limitation for initial Sensor Calibration of the NanoRadar";

CM_ SG_ 2589283912 NR_02_CAL_Text_Data_1 "Information regarding the Initial sensor calibration of the NanoRadar in the Plant and Service do be displayed via HMI. Formatted as UTF-8 String, part 1 (Characters 0 to 6)";
CM_ SG_ 2589283912 NR_02_CAL_Text_Request "Triggers the Display via HMI of the characters in the signals  NR_02_CAL_Text_Data_<1 to 3> for the NanoRadar";

CM_ SG_ 2589283913 NR_02_CAL_Text_Data_2 "Information regarding the Initial sensor calibration of the NanoRadar in the Plant and Service do be displayed via HMI. Formatted as UTF-8 String, part 2 (Characters 7 to 14)";

CM_ SG_ 2589283914 NR_02_CAL_Text_Data_3 "Information regarding the Initial sensor calibration of the NanoRadar in the Plant and Service do be displayed via HMI. Formatted as UTF-8 String, part 3 (Characters 15 to 22)";

CM_ SG_ 2331595825 NR_FL_Cal_resp "Signal is used for the calibration.";
CM_ SG_ 2331595825 NR_FL_CalibrationMode "Current mode of calibration.";
CM_ SG_ 2331595825 NR_FL_QualFactorAutoCalib "Estimated qulality factor of  auto-alignment.";
CM_ SG_ 2331595825 NR_FL_resp_val "Signal is used for the calibration.";
CM_ SG_ 2331595825 NR_FL_ShortTrackCal_State "Signal is used for short track calibration.";

CM_ SG_ 2331595790 NR_FL_Contour_BlockID_01 "BlockID is a counter to associate data togehter, which are split over severel PDUs.";
CM_ SG_ 2331595790 NR_FL_Contour_BZ "4bit Botschaftszähler, wird mit jeder Sendebotschaft inkrementiert";
CM_ SG_ 2331595790 NR_FL_Contour_CRC "Für MLB:
Berechnung siehe Lastenheft 'Kommunikationsabsicherung für FlexRay und CAN'
Ab MQB und MLBevo:
Berechnung siehe Lastenheft 'End-to-End Kommunikationsabsicherung'

Endwerte siehe Begleitdokument 'S-PDU Kennungsfolgen'";
CM_ SG_ 2331595790 NR_FL_Contour_left_01_Age "The signal indicates the age of the contour 1. How long has the contour been seen";
CM_ SG_ 2331595790 NR_FL_Contour_left_01_Type "Type of edge structure contour 1";
CM_ SG_ 2331595790 NR_FL_Contour_left_01_x01 "X position of the support point of the contour 1";
CM_ SG_ 2331595790 NR_FL_Contour_left_01_x02 "X position of the support point of the contour 1";
CM_ SG_ 2331595790 NR_FL_Contour_left_01_x03 "X position of the support point of the contour 1";
CM_ SG_ 2331595790 NR_FL_Contour_left_01_x04 "X position of the support point of the contour 1";
CM_ SG_ 2331595790 NR_FL_Contour_left_01_x05 "X position of the support point of the contour 1";
CM_ SG_ 2331595790 NR_FL_Contour_left_01_x06 "X position of the support point of the contour 1";
CM_ SG_ 2331595790 NR_FL_Contour_left_01_x07 "X position of the support point of the contour 1";
CM_ SG_ 2331595790 NR_FL_Contour_left_01_y01 "Y position of the support point of the contour 1";
CM_ SG_ 2331595790 NR_FL_Contour_left_01_y02 "Y position of the support point of the contour 1";
CM_ SG_ 2331595790 NR_FL_Contour_left_01_y03 "Y position of the support point of the contour 1";
CM_ SG_ 2331595790 NR_FL_Contour_left_01_y04 "Y position of the support point of the contour 1";
CM_ SG_ 2331595790 NR_FL_Contour_left_01_y05 "Y position of the support point of the contour 1";
CM_ SG_ 2331595790 NR_FL_Contour_left_01_y06 "Y position of the support point of the contour 1";
CM_ SG_ 2331595790 NR_FL_Contour_left_01_y07 "Y position of the support point of the contour 1";
CM_ SG_ 2331595790 NR_FL_Contour_left_02_Age "The signal indicates the age of the contour 2. How long has the contour been seen";
CM_ SG_ 2331595790 NR_FL_Contour_left_02_Type "Type of edge structure contour 2";
CM_ SG_ 2331595790 NR_FL_Contour_left_02_x01 "X position of the support point of the contour 2";
CM_ SG_ 2331595790 NR_FL_Contour_left_02_x02 "X position of the support point of the contour 2";
CM_ SG_ 2331595790 NR_FL_Contour_left_02_x03 "X position of the support point of the contour 2";
CM_ SG_ 2331595790 NR_FL_Contour_left_02_x04 "X position of the support point of the contour 2";
CM_ SG_ 2331595790 NR_FL_Contour_left_02_x05 "X position of the support point of the contour 2";
CM_ SG_ 2331595790 NR_FL_Contour_left_02_x06 "X position of the support point of the contour 2";
CM_ SG_ 2331595790 NR_FL_Contour_left_02_x07 "X position of the support point of the contour 2";
CM_ SG_ 2331595790 NR_FL_Contour_left_02_y01 "Y position of the support point of the contour 2";
CM_ SG_ 2331595790 NR_FL_Contour_left_02_y02 "Y position of the support point of the contour 2";
CM_ SG_ 2331595790 NR_FL_Contour_left_02_y03 "Y position of the support point of the contour 2";
CM_ SG_ 2331595790 NR_FL_Contour_left_02_y04 "Y position of the support point of the contour 2";
CM_ SG_ 2331595790 NR_FL_Contour_left_02_y05 "Y position of the support point of the contour 2";
CM_ SG_ 2331595790 NR_FL_Contour_left_02_y06 "Y position of the support point of the contour 2";
CM_ SG_ 2331595790 NR_FL_Contour_left_02_y07 "Y position of the support point of the contour 2";
CM_ SG_ 2331595790 NR_FL_Contour_left_Linkage "The signal indicates  whether contours are interconected";
CM_ SG_ 2331595790 SOK_NR_FL_Contour_Signatur "Signatur im Rahmen der durch SOK geschützen Broadcast-Kommunikation
";

CM_ SG_ 2331595781 NR_FL_Blindness "The signal indicates sensor blindness/occlusion";
CM_ SG_ 2331595781 NR_FL_BlockID_01 "BlockID is a counter to associate data togehter, which are split over severel PDUs.";
CM_ SG_ 2331595781 NR_FL_CalibrationState "The signal indicates the current calibration status of the sensor.";
CM_ SG_ 2331595781 NR_FL_Failure "The signal indicates an active failure on the sensor";
CM_ SG_ 2331595781 NR_FL_Freesight_NOK "The signal indicates if a free view was not possible";
CM_ SG_ 2331595781 NR_FL_Header_BZ "4bit Botschaftszähler, wird mit jeder Sendebotschaft inkrementiert";
CM_ SG_ 2331595781 NR_FL_Header_CRC "Für MLB:
Berechnung siehe Lastenheft 'Kommunikationsabsicherung für FlexRay und CAN'
Ab MQB und MLBevo:
Berechnung siehe Lastenheft 'End-to-End Kommunikationsabsicherung'

Endwerte siehe Begleitdokument 'S-PDU Kennungsfolgen'";
CM_ SG_ 2331595781 NR_FL_MeasurementTimeHigh "Time stamp based on time stamp format of base service Zeitmaster and its definition of 'Precise Local Time' and time format TMF_01. High part of the time stamp corresponds to the seconds part of the time";
CM_ SG_ 2331595781 NR_FL_MeasurementTimeLapNumber "The lap number of the TLT master under which the MeasurementTime was derived";
CM_ SG_ 2331595781 NR_FL_MeasurementTimeLow "Time stamp based on time stamp format of base service Zeitmaster and its definition of 'Precise Local Time' and time format TMF_01. Low part of the time stamp corresponds to the nanoseconds part of the time";
CM_ SG_ 2331595781 NR_FL_MeasurementTimeStatus "Describes the quality of the timestamp";
CM_ SG_ 2331595781 NR_FL_NotAvailable "The signal indicates not availability of the sensor";
CM_ SG_ 2331595781 NR_FL_RangeDegradation_Sect1 "Estimated degradation of the sensor in range for sector 1.";
CM_ SG_ 2331595781 NR_FL_RangeDegradation_Sect2 "Estimated degradation of the sensor in range for sector 2.";
CM_ SG_ 2331595781 NR_FL_RangeDegradation_Sect3 "This signal is used for the feature 'Blindheitsverdacht'(due to K-Matrix Freeze, this existing signal is used, instead of a correctly named signal). Like NR_XX_Blindness the signal indicates sensor blindness and uses the same algorithm. Parameters are adj";
CM_ SG_ 2331595781 SOK_NR_FL_Header_Signatur "Signatur im Rahmen der durch SOK geschützen Broadcast-Kommunikation
";

CM_ SG_ 2331595776 NR_FL_Object_01_02_BlockID_01 "BlockID is a counter to associate data togehter, which are split over severel PDUs.";
CM_ SG_ 2331595776 NR_FL_Object_01_02_BZ "4bit Botschaftszähler, wird mit jeder Sendebotschaft inkrementiert";
CM_ SG_ 2331595776 NR_FL_Object_01_02_CRC "Für MLB:
Berechnung siehe Lastenheft 'Kommunikationsabsicherung für FlexRay und CAN'
Ab MQB und MLBevo:
Berechnung siehe Lastenheft 'End-to-End Kommunikationsabsicherung'

Endwerte siehe Begleitdokument 'S-PDU Kennungsfolgen'";
CM_ SG_ 2331595776 NR_FL_Object_01_aAbsX "The signal indicates the absolute acceleration of the object in the X direction.";
CM_ SG_ 2331595776 NR_FL_Object_01_aAbsXSD "The signal indicates the standard deviation of the absolute acceleration of the object in the X direction.";
CM_ SG_ 2331595776 NR_FL_Object_01_aAbsY "The signal indicates the absolute acceleration of the object in the Y direction.";
CM_ SG_ 2331595776 NR_FL_Object_01_aAbsYSD "The signal indicates the standard deviation of the absolute acceleration of the object in the Y direction.";
CM_ SG_ 2331595776 NR_FL_Object_01_Age "The signal indicates the age of the object. How long has the object been seen";
CM_ SG_ 2331595776 NR_FL_Object_01_Class "The signal indicates the object class.";
CM_ SG_ 2331595776 NR_FL_Object_01_ClassPlausib "The signal indicates the plausibility of the object class.";
CM_ SG_ 2331595776 NR_FL_Object_01_DynamicState "The signal indicates the motion state of the object.";
CM_ SG_ 2331595776 NR_FL_Object_01_ExistProb "The signal indicates the existence probability of the object.";
CM_ SG_ 2331595776 NR_FL_Object_01_ID "Signal indicates the ID of the object.";
CM_ SG_ 2331595776 NR_FL_Object_01_Length "The signal indicates the length of the object.";
CM_ SG_ 2331595776 NR_FL_Object_01_LengthSD "The signal indicates the standard deviation of the length of the object.";
CM_ SG_ 2331595776 NR_FL_Object_01_MeasurementState "The signal indicates whether the object was measured in the current cycle.";
CM_ SG_ 2331595776 NR_FL_Object_01_PosX "Object X position in UKS";
CM_ SG_ 2331595776 NR_FL_Object_01_PosXSD "The signal indicates the standard deviation of the X position";
CM_ SG_ 2331595776 NR_FL_Object_01_PosY "Object Y position in UKS";
CM_ SG_ 2331595776 NR_FL_Object_01_PosYSD "The signal indicates the standard deviation of the Y position";
CM_ SG_ 2331595776 NR_FL_Object_01_ReferencePoint "Reference Point of the Object";
CM_ SG_ 2331595776 NR_FL_Object_01_vAbsX "The signal indicates the velocity in X direction";
CM_ SG_ 2331595776 NR_FL_Object_01_vAbsXSD "The signal indicates the standard deviation of the velocity in X direction";
CM_ SG_ 2331595776 NR_FL_Object_01_vAbsY "The signal indicates the velocity in Y direction.";
CM_ SG_ 2331595776 NR_FL_Object_01_vAbsYSD "The signal indicates the standard deviation of the velocity in Y direction.";
CM_ SG_ 2331595776 NR_FL_Object_01_Width "The signal indicates the width of the object.";
CM_ SG_ 2331595776 NR_FL_Object_01_WidthSD "The signal indicates the standard deviation of the width of the object.";
CM_ SG_ 2331595776 NR_FL_Object_01_YawAngle "The signal indicates the yaw angle of the object relative to the UKS.";
CM_ SG_ 2331595776 NR_FL_Object_01_YawAngleSD "The signal indicates the standard deviation to the yaw angle.";
CM_ SG_ 2331595776 NR_FL_Object_01_YawRateAbs "The signal indicates the yaw rate of the object relative to the UKS.";
CM_ SG_ 2331595776 NR_FL_Object_01_YawRateAbsSD "The signal indicates the standard deviation to the yaw rate.";
CM_ SG_ 2331595776 NR_FL_Object_02_aAbsX "The signal indicates the absolute acceleration of the object in the X direction.";
CM_ SG_ 2331595776 NR_FL_Object_02_aAbsXSD "The signal indicates the standard deviation of the absolute acceleration of the object in the X direction.";
CM_ SG_ 2331595776 NR_FL_Object_02_aAbsY "The signal indicates the absolute acceleration of the object in the Y direction.";
CM_ SG_ 2331595776 NR_FL_Object_02_aAbsYSD "The signal indicates the standard deviation of the absolute acceleration of the object in the Y direction.";
CM_ SG_ 2331595776 NR_FL_Object_02_Age "The signal indicates the age of the object. How long has the object been seen";
CM_ SG_ 2331595776 NR_FL_Object_02_Class "The signal indicates the object class.";
CM_ SG_ 2331595776 NR_FL_Object_02_ClassPlausib "The signal indicates the plausibility of the object class.";
CM_ SG_ 2331595776 NR_FL_Object_02_DynamicState "The signal indicates the motion state of the object.";
CM_ SG_ 2331595776 NR_FL_Object_02_ExistProb "The signal indicates the existence probability of the object.";
CM_ SG_ 2331595776 NR_FL_Object_02_ID "Signal indicates the ID of the object.";
CM_ SG_ 2331595776 NR_FL_Object_02_Length "The signal indicates the length of the object.";
CM_ SG_ 2331595776 NR_FL_Object_02_LengthSD "The signal indicates the standard deviation of the length of the object.";
CM_ SG_ 2331595776 NR_FL_Object_02_MeasurementState "The signal indicates whether the object was measured in the current cycle.";
CM_ SG_ 2331595776 NR_FL_Object_02_PosX "Object X position in UKS";
CM_ SG_ 2331595776 NR_FL_Object_02_PosXSD "The signal indicates the standard deviation of the X position";
CM_ SG_ 2331595776 NR_FL_Object_02_PosY "Object Y position in UKS";
CM_ SG_ 2331595776 NR_FL_Object_02_PosYSD "The signal indicates the standard deviation of the Y position";
CM_ SG_ 2331595776 NR_FL_Object_02_ReferencePoint "Reference Point of the Object";
CM_ SG_ 2331595776 NR_FL_Object_02_vAbsX "The signal indicates the velocity in X direction";
CM_ SG_ 2331595776 NR_FL_Object_02_vAbsXSD "The signal indicates the standard deviation of the velocity in X direction";
CM_ SG_ 2331595776 NR_FL_Object_02_vAbsY "The signal indicates the velocity in Y direction.";
CM_ SG_ 2331595776 NR_FL_Object_02_vAbsYSD "The signal indicates the standard deviation of the velocity in Y direction.";
CM_ SG_ 2331595776 NR_FL_Object_02_Width "The signal indicates the width of the object.";
CM_ SG_ 2331595776 NR_FL_Object_02_WidthSD "The signal indicates the standard deviation of the width of the object.";
CM_ SG_ 2331595776 NR_FL_Object_02_YawAngle "The signal indicates the yaw angle of the object relative to the UKS.";
CM_ SG_ 2331595776 NR_FL_Object_02_YawAngleSD "The signal indicates the standard deviation to the yaw angle.";
CM_ SG_ 2331595776 NR_FL_Object_02_YawRateAbs "The signal indicates the yaw rate of the object relative to the UKS.";
CM_ SG_ 2331595776 NR_FL_Object_02_YawRateAbsSD "The signal indicates the standard deviation to the yaw rate.";
CM_ SG_ 2331595776 SOK_NR_FL_Object_01_02_Signatur "Signatur im Rahmen der durch SOK geschützen Broadcast-Kommunikation
";

CM_ SG_ 2331595777 NR_FL_Object_03_04_BlockID_01 "BlockID is a counter to associate data togehter, which are split over severel PDUs.";
CM_ SG_ 2331595777 NR_FL_Object_03_04_BZ "4bit Botschaftszähler, wird mit jeder Sendebotschaft inkrementiert";
CM_ SG_ 2331595777 NR_FL_Object_03_04_CRC "Für MLB:
Berechnung siehe Lastenheft 'Kommunikationsabsicherung für FlexRay und CAN'
Ab MQB und MLBevo:
Berechnung siehe Lastenheft 'End-to-End Kommunikationsabsicherung'

Endwerte siehe Begleitdokument 'S-PDU Kennungsfolgen'";
CM_ SG_ 2331595777 NR_FL_Object_03_aAbsX "The signal indicates the absolute acceleration of the object in the X direction.";
CM_ SG_ 2331595777 NR_FL_Object_03_aAbsXSD "The signal indicates the standard deviation of the absolute acceleration of the object in the X direction.";
CM_ SG_ 2331595777 NR_FL_Object_03_aAbsY "The signal indicates the absolute acceleration of the object in the Y direction.";
CM_ SG_ 2331595777 NR_FL_Object_03_aAbsYSD "The signal indicates the standard deviation of the absolute acceleration of the object in the Y direction.";
CM_ SG_ 2331595777 NR_FL_Object_03_Age "The signal indicates the age of the object. How long has the object been seen";
CM_ SG_ 2331595777 NR_FL_Object_03_Class "The signal indicates the object class.";
CM_ SG_ 2331595777 NR_FL_Object_03_ClassPlausib "The signal indicates the plausibility of the object class.";
CM_ SG_ 2331595777 NR_FL_Object_03_DynamicState "The signal indicates the motion state of the object.";
CM_ SG_ 2331595777 NR_FL_Object_03_ExistProb "The signal indicates the existence probability of the object.";
CM_ SG_ 2331595777 NR_FL_Object_03_ID "Signal indicates the ID of the object.";
CM_ SG_ 2331595777 NR_FL_Object_03_Length "The signal indicates the length of the object.";
CM_ SG_ 2331595777 NR_FL_Object_03_LengthSD "The signal indicates the standard deviation of the length of the object.";
CM_ SG_ 2331595777 NR_FL_Object_03_MeasurementState "The signal indicates whether the object was measured in the current cycle.";
CM_ SG_ 2331595777 NR_FL_Object_03_PosX "Object X position in UKS";
CM_ SG_ 2331595777 NR_FL_Object_03_PosXSD "The signal indicates the standard deviation of the X position";
CM_ SG_ 2331595777 NR_FL_Object_03_PosY "Object Y position in UKS";
CM_ SG_ 2331595777 NR_FL_Object_03_PosYSD "The signal indicates the standard deviation of the Y position";
CM_ SG_ 2331595777 NR_FL_Object_03_ReferencePoint "Reference Point of the Object";
CM_ SG_ 2331595777 NR_FL_Object_03_vAbsX "The signal indicates the velocity in X direction";
CM_ SG_ 2331595777 NR_FL_Object_03_vAbsXSD "The signal indicates the standard deviation of the velocity in X direction";
CM_ SG_ 2331595777 NR_FL_Object_03_vAbsY "The signal indicates the velocity in Y direction.";
CM_ SG_ 2331595777 NR_FL_Object_03_vAbsYSD "The signal indicates the standard deviation of the velocity in Y direction.";
CM_ SG_ 2331595777 NR_FL_Object_03_Width "The signal indicates the width of the object.";
CM_ SG_ 2331595777 NR_FL_Object_03_WidthSD "The signal indicates the standard deviation of the width of the object.";
CM_ SG_ 2331595777 NR_FL_Object_03_YawAngle "The signal indicates the yaw angle of the object relative to the UKS.";
CM_ SG_ 2331595777 NR_FL_Object_03_YawAngleSD "The signal indicates the standard deviation to the yaw angle.";
CM_ SG_ 2331595777 NR_FL_Object_03_YawRateAbs "The signal indicates the yaw rate of the object relative to the UKS.";
CM_ SG_ 2331595777 NR_FL_Object_03_YawRateAbsSD "The signal indicates the standard deviation to the yaw rate.";
CM_ SG_ 2331595777 NR_FL_Object_04_aAbsX "The signal indicates the absolute acceleration of the object in the X direction.";
CM_ SG_ 2331595777 NR_FL_Object_04_aAbsXSD "The signal indicates the standard deviation of the absolute acceleration of the object in the X direction.";
CM_ SG_ 2331595777 NR_FL_Object_04_aAbsY "The signal indicates the absolute acceleration of the object in the Y direction.";
CM_ SG_ 2331595777 NR_FL_Object_04_aAbsYSD "The signal indicates the standard deviation of the absolute acceleration of the object in the Y direction.";
CM_ SG_ 2331595777 NR_FL_Object_04_Age "The signal indicates the age of the object. How long has the object been seen";
CM_ SG_ 2331595777 NR_FL_Object_04_Class "The signal indicates the object class.";
CM_ SG_ 2331595777 NR_FL_Object_04_ClassPlausib "The signal indicates the plausibility of the object class.";
CM_ SG_ 2331595777 NR_FL_Object_04_DynamicState "The signal indicates the motion state of the object.";
CM_ SG_ 2331595777 NR_FL_Object_04_ExistProb "The signal indicates the existence probability of the object.";
CM_ SG_ 2331595777 NR_FL_Object_04_ID "Signal indicates the ID of the object.";
CM_ SG_ 2331595777 NR_FL_Object_04_Length "The signal indicates the length of the object.";
CM_ SG_ 2331595777 NR_FL_Object_04_LengthSD "The signal indicates the standard deviation of the length of the object.";
CM_ SG_ 2331595777 NR_FL_Object_04_MeasurementState "The signal indicates whether the object was measured in the current cycle.";
CM_ SG_ 2331595777 NR_FL_Object_04_PosX "Object X position in UKS";
CM_ SG_ 2331595777 NR_FL_Object_04_PosXSD "The signal indicates the standard deviation of the X position";
CM_ SG_ 2331595777 NR_FL_Object_04_PosY "Object Y position in UKS";
CM_ SG_ 2331595777 NR_FL_Object_04_PosYSD "The signal indicates the standard deviation of the Y position";
CM_ SG_ 2331595777 NR_FL_Object_04_ReferencePoint "Reference Point of the Object";
CM_ SG_ 2331595777 NR_FL_Object_04_vAbsX "The signal indicates the velocity in X direction";
CM_ SG_ 2331595777 NR_FL_Object_04_vAbsXSD "The signal indicates the standard deviation of the velocity in X direction";
CM_ SG_ 2331595777 NR_FL_Object_04_vAbsY "The signal indicates the velocity in Y direction.";
CM_ SG_ 2331595777 NR_FL_Object_04_vAbsYSD "The signal indicates the standard deviation of the velocity in Y direction.";
CM_ SG_ 2331595777 NR_FL_Object_04_Width "The signal indicates the width of the object.";
CM_ SG_ 2331595777 NR_FL_Object_04_WidthSD "The signal indicates the standard deviation of the width of the object.";
CM_ SG_ 2331595777 NR_FL_Object_04_YawAngle "The signal indicates the yaw angle of the object relative to the UKS.";
CM_ SG_ 2331595777 NR_FL_Object_04_YawAngleSD "The signal indicates the standard deviation to the yaw angle.";
CM_ SG_ 2331595777 NR_FL_Object_04_YawRateAbs "The signal indicates the yaw rate of the object relative to the UKS.";
CM_ SG_ 2331595777 NR_FL_Object_04_YawRateAbsSD "The signal indicates the standard deviation to the yaw rate.";
CM_ SG_ 2331595777 SOK_NR_FL_Object_03_04_Signatur "Signatur im Rahmen der durch SOK geschützen Broadcast-Kommunikation
";

CM_ SG_ 2331595778 NR_FL_Object_05_06_BlockID_01 "BlockID is a counter to associate data togehter, which are split over severel PDUs.";
CM_ SG_ 2331595778 NR_FL_Object_05_06_BZ "4bit Botschaftszähler, wird mit jeder Sendebotschaft inkrementiert";
CM_ SG_ 2331595778 NR_FL_Object_05_06_CRC "Für MLB:
Berechnung siehe Lastenheft 'Kommunikationsabsicherung für FlexRay und CAN'
Ab MQB und MLBevo:
Berechnung siehe Lastenheft 'End-to-End Kommunikationsabsicherung'

Endwerte siehe Begleitdokument 'S-PDU Kennungsfolgen'";
CM_ SG_ 2331595778 NR_FL_Object_05_aAbsX "The signal indicates the absolute acceleration of the object in the X direction.";
CM_ SG_ 2331595778 NR_FL_Object_05_aAbsXSD "The signal indicates the standard deviation of the absolute acceleration of the object in the X direction.";
CM_ SG_ 2331595778 NR_FL_Object_05_aAbsY "The signal indicates the absolute acceleration of the object in the Y direction.";
CM_ SG_ 2331595778 NR_FL_Object_05_aAbsYSD "The signal indicates the standard deviation of the absolute acceleration of the object in the Y direction.";
CM_ SG_ 2331595778 NR_FL_Object_05_Age "The signal indicates the age of the object. How long has the object been seen";
CM_ SG_ 2331595778 NR_FL_Object_05_Class "The signal indicates the object class.";
CM_ SG_ 2331595778 NR_FL_Object_05_ClassPlausib "The signal indicates the plausibility of the object class.";
CM_ SG_ 2331595778 NR_FL_Object_05_DynamicState "The signal indicates the motion state of the object.";
CM_ SG_ 2331595778 NR_FL_Object_05_ExistProb "The signal indicates the existence probability of the object.";
CM_ SG_ 2331595778 NR_FL_Object_05_ID "Signal indicates the ID of the object.";
CM_ SG_ 2331595778 NR_FL_Object_05_Length "The signal indicates the length of the object.";
CM_ SG_ 2331595778 NR_FL_Object_05_LengthSD "The signal indicates the standard deviation of the length of the object.";
CM_ SG_ 2331595778 NR_FL_Object_05_MeasurementState "The signal indicates whether the object was measured in the current cycle.";
CM_ SG_ 2331595778 NR_FL_Object_05_PosX "Object X position in UKS";
CM_ SG_ 2331595778 NR_FL_Object_05_PosXSD "The signal indicates the standard deviation of the X position";
CM_ SG_ 2331595778 NR_FL_Object_05_PosY "Object Y position in UKS";
CM_ SG_ 2331595778 NR_FL_Object_05_PosYSD "The signal indicates the standard deviation of the Y position";
CM_ SG_ 2331595778 NR_FL_Object_05_ReferencePoint "Reference Point of the Object";
CM_ SG_ 2331595778 NR_FL_Object_05_vAbsX "The signal indicates the velocity in X direction";
CM_ SG_ 2331595778 NR_FL_Object_05_vAbsXSD "The signal indicates the standard deviation of the velocity in X direction";
CM_ SG_ 2331595778 NR_FL_Object_05_vAbsY "The signal indicates the velocity in Y direction.";
CM_ SG_ 2331595778 NR_FL_Object_05_vAbsYSD "The signal indicates the standard deviation of the velocity in Y direction.";
CM_ SG_ 2331595778 NR_FL_Object_05_Width "The signal indicates the width of the object.";
CM_ SG_ 2331595778 NR_FL_Object_05_WidthSD "The signal indicates the standard deviation of the width of the object.";
CM_ SG_ 2331595778 NR_FL_Object_05_YawAngle "The signal indicates the yaw angle of the object relative to the UKS.";
CM_ SG_ 2331595778 NR_FL_Object_05_YawAngleSD "The signal indicates the standard deviation to the yaw angle.";
CM_ SG_ 2331595778 NR_FL_Object_05_YawRateAbs "The signal indicates the yaw rate of the object relative to the UKS.";
CM_ SG_ 2331595778 NR_FL_Object_05_YawRateAbsSD "The signal indicates the standard deviation to the yaw rate.";
CM_ SG_ 2331595778 NR_FL_Object_06_aAbsX "The signal indicates the absolute acceleration of the object in the X direction.";
CM_ SG_ 2331595778 NR_FL_Object_06_aAbsXSD "The signal indicates the standard deviation of the absolute acceleration of the object in the X direction.";
CM_ SG_ 2331595778 NR_FL_Object_06_aAbsY "The signal indicates the absolute acceleration of the object in the Y direction.";
CM_ SG_ 2331595778 NR_FL_Object_06_aAbsYSD "The signal indicates the standard deviation of the absolute acceleration of the object in the Y direction.";
CM_ SG_ 2331595778 NR_FL_Object_06_Age "The signal indicates the age of the object. How long has the object been seen";
CM_ SG_ 2331595778 NR_FL_Object_06_Class "The signal indicates the object class.";
CM_ SG_ 2331595778 NR_FL_Object_06_ClassPlausib "The signal indicates the plausibility of the object class.";
CM_ SG_ 2331595778 NR_FL_Object_06_DynamicState "The signal indicates the motion state of the object.";
CM_ SG_ 2331595778 NR_FL_Object_06_ExistProb "The signal indicates the existence probability of the object.";
CM_ SG_ 2331595778 NR_FL_Object_06_ID "Signal indicates the ID of the object.";
CM_ SG_ 2331595778 NR_FL_Object_06_Length "The signal indicates the length of the object.";
CM_ SG_ 2331595778 NR_FL_Object_06_LengthSD "The signal indicates the standard deviation of the length of the object.";
CM_ SG_ 2331595778 NR_FL_Object_06_MeasurementState "The signal indicates whether the object was measured in the current cycle.";
CM_ SG_ 2331595778 NR_FL_Object_06_PosX "Object X position in UKS";
CM_ SG_ 2331595778 NR_FL_Object_06_PosXSD "The signal indicates the standard deviation of the X position";
CM_ SG_ 2331595778 NR_FL_Object_06_PosY "Object Y position in UKS";
CM_ SG_ 2331595778 NR_FL_Object_06_PosYSD "The signal indicates the standard deviation of the Y position";
CM_ SG_ 2331595778 NR_FL_Object_06_ReferencePoint "Reference Point of the Object";
CM_ SG_ 2331595778 NR_FL_Object_06_vAbsX "The signal indicates the velocity in X direction";
CM_ SG_ 2331595778 NR_FL_Object_06_vAbsXSD "The signal indicates the standard deviation of the velocity in X direction";
CM_ SG_ 2331595778 NR_FL_Object_06_vAbsY "The signal indicates the velocity in Y direction.";
CM_ SG_ 2331595778 NR_FL_Object_06_vAbsYSD "The signal indicates the standard deviation of the velocity in Y direction.";
CM_ SG_ 2331595778 NR_FL_Object_06_Width "The signal indicates the width of the object.";
CM_ SG_ 2331595778 NR_FL_Object_06_WidthSD "The signal indicates the standard deviation of the width of the object.";
CM_ SG_ 2331595778 NR_FL_Object_06_YawAngle "The signal indicates the yaw angle of the object relative to the UKS.";
CM_ SG_ 2331595778 NR_FL_Object_06_YawAngleSD "The signal indicates the standard deviation to the yaw angle.";
CM_ SG_ 2331595778 NR_FL_Object_06_YawRateAbs "The signal indicates the yaw rate of the object relative to the UKS.";
CM_ SG_ 2331595778 NR_FL_Object_06_YawRateAbsSD "The signal indicates the standard deviation to the yaw rate.";
CM_ SG_ 2331595778 SOK_NR_FL_Object_05_06_Signatur "Signatur im Rahmen der durch SOK geschützen Broadcast-Kommunikation
";

CM_ SG_ 2331595779 NR_FL_Object_07_08_BlockID_01 "BlockID is a counter to associate data togehter, which are split over severel PDUs.";
CM_ SG_ 2331595779 NR_FL_Object_07_08_BZ "4bit Botschaftszähler, wird mit jeder Sendebotschaft inkrementiert";
CM_ SG_ 2331595779 NR_FL_Object_07_08_CRC "Für MLB:
Berechnung siehe Lastenheft 'Kommunikationsabsicherung für FlexRay und CAN'
Ab MQB und MLBevo:
Berechnung siehe Lastenheft 'End-to-End Kommunikationsabsicherung'

Endwerte siehe Begleitdokument 'S-PDU Kennungsfolgen'";
CM_ SG_ 2331595779 NR_FL_Object_07_aAbsX "The signal indicates the absolute acceleration of the object in the X direction.";
CM_ SG_ 2331595779 NR_FL_Object_07_aAbsXSD "The signal indicates the standard deviation of the absolute acceleration of the object in the X direction.";
CM_ SG_ 2331595779 NR_FL_Object_07_aAbsY "The signal indicates the absolute acceleration of the object in the Y direction.";
CM_ SG_ 2331595779 NR_FL_Object_07_aAbsYSD "The signal indicates the standard deviation of the absolute acceleration of the object in the Y direction.";
CM_ SG_ 2331595779 NR_FL_Object_07_Age "The signal indicates the age of the object. How long has the object been seen";
CM_ SG_ 2331595779 NR_FL_Object_07_Class "The signal indicates the object class.";
CM_ SG_ 2331595779 NR_FL_Object_07_ClassPlausib "The signal indicates the plausibility of the object class.";
CM_ SG_ 2331595779 NR_FL_Object_07_DynamicState "The signal indicates the motion state of the object.";
CM_ SG_ 2331595779 NR_FL_Object_07_ExistProb "The signal indicates the existence probability of the object.";
CM_ SG_ 2331595779 NR_FL_Object_07_ID "Signal indicates the ID of the object.";
CM_ SG_ 2331595779 NR_FL_Object_07_Length "The signal indicates the length of the object.";
CM_ SG_ 2331595779 NR_FL_Object_07_LengthSD "The signal indicates the standard deviation of the length of the object.";
CM_ SG_ 2331595779 NR_FL_Object_07_MeasurementState "The signal indicates whether the object was measured in the current cycle.";
CM_ SG_ 2331595779 NR_FL_Object_07_PosX "Object X position in UKS";
CM_ SG_ 2331595779 NR_FL_Object_07_PosXSD "The signal indicates the standard deviation of the X position";
CM_ SG_ 2331595779 NR_FL_Object_07_PosY "Object Y position in UKS";
CM_ SG_ 2331595779 NR_FL_Object_07_PosYSD "The signal indicates the standard deviation of the Y position";
CM_ SG_ 2331595779 NR_FL_Object_07_ReferencePoint "Reference Point of the Object";
CM_ SG_ 2331595779 NR_FL_Object_07_vAbsX "The signal indicates the velocity in X direction";
CM_ SG_ 2331595779 NR_FL_Object_07_vAbsXSD "The signal indicates the standard deviation of the velocity in X direction";
CM_ SG_ 2331595779 NR_FL_Object_07_vAbsY "The signal indicates the velocity in Y direction.";
CM_ SG_ 2331595779 NR_FL_Object_07_vAbsYSD "The signal indicates the standard deviation of the velocity in Y direction.";
CM_ SG_ 2331595779 NR_FL_Object_07_Width "The signal indicates the width of the object.";
CM_ SG_ 2331595779 NR_FL_Object_07_WidthSD "The signal indicates the standard deviation of the width of the object.";
CM_ SG_ 2331595779 NR_FL_Object_07_YawAngle "The signal indicates the yaw angle of the object relative to the UKS.";
CM_ SG_ 2331595779 NR_FL_Object_07_YawAngleSD "The signal indicates the standard deviation to the yaw angle.";
CM_ SG_ 2331595779 NR_FL_Object_07_YawRateAbs "The signal indicates the yaw rate of the object relative to the UKS.";
CM_ SG_ 2331595779 NR_FL_Object_07_YawRateAbsSD "The signal indicates the standard deviation to the yaw rate.";
CM_ SG_ 2331595779 NR_FL_Object_08_aAbsX "The signal indicates the absolute acceleration of the object in the X direction.";
CM_ SG_ 2331595779 NR_FL_Object_08_aAbsXSD "The signal indicates the standard deviation of the absolute acceleration of the object in the X direction.";
CM_ SG_ 2331595779 NR_FL_Object_08_aAbsY "The signal indicates the absolute acceleration of the object in the Y direction.";
CM_ SG_ 2331595779 NR_FL_Object_08_aAbsYSD "The signal indicates the standard deviation of the absolute acceleration of the object in the Y direction.";
CM_ SG_ 2331595779 NR_FL_Object_08_Age "The signal indicates the age of the object. How long has the object been seen";
CM_ SG_ 2331595779 NR_FL_Object_08_Class "The signal indicates the object class.";
CM_ SG_ 2331595779 NR_FL_Object_08_ClassPlausib "The signal indicates the plausibility of the object class.";
CM_ SG_ 2331595779 NR_FL_Object_08_DynamicState "The signal indicates the motion state of the object.";
CM_ SG_ 2331595779 NR_FL_Object_08_ExistProb "The signal indicates the existence probability of the object.";
CM_ SG_ 2331595779 NR_FL_Object_08_ID "Signal indicates the ID of the object.";
CM_ SG_ 2331595779 NR_FL_Object_08_Length "The signal indicates the length of the object.";
CM_ SG_ 2331595779 NR_FL_Object_08_LengthSD "The signal indicates the standard deviation of the length of the object.";
CM_ SG_ 2331595779 NR_FL_Object_08_MeasurementState "The signal indicates whether the object was measured in the current cycle.";
CM_ SG_ 2331595779 NR_FL_Object_08_PosX "Object X position in UKS";
CM_ SG_ 2331595779 NR_FL_Object_08_PosXSD "The signal indicates the standard deviation of the X position";
CM_ SG_ 2331595779 NR_FL_Object_08_PosY "Object Y position in UKS";
CM_ SG_ 2331595779 NR_FL_Object_08_PosYSD "The signal indicates the standard deviation of the Y position";
CM_ SG_ 2331595779 NR_FL_Object_08_ReferencePoint "Reference Point of the Object";
CM_ SG_ 2331595779 NR_FL_Object_08_vAbsX "The signal indicates the velocity in X direction";
CM_ SG_ 2331595779 NR_FL_Object_08_vAbsXSD "The signal indicates the standard deviation of the velocity in X direction";
CM_ SG_ 2331595779 NR_FL_Object_08_vAbsY "The signal indicates the velocity in Y direction.";
CM_ SG_ 2331595779 NR_FL_Object_08_vAbsYSD "The signal indicates the standard deviation of the velocity in Y direction.";
CM_ SG_ 2331595779 NR_FL_Object_08_Width "The signal indicates the width of the object.";
CM_ SG_ 2331595779 NR_FL_Object_08_WidthSD "The signal indicates the standard deviation of the width of the object.";
CM_ SG_ 2331595779 NR_FL_Object_08_YawAngle "The signal indicates the yaw angle of the object relative to the UKS.";
CM_ SG_ 2331595779 NR_FL_Object_08_YawAngleSD "The signal indicates the standard deviation to the yaw angle.";
CM_ SG_ 2331595779 NR_FL_Object_08_YawRateAbs "The signal indicates the yaw rate of the object relative to the UKS.";
CM_ SG_ 2331595779 NR_FL_Object_08_YawRateAbsSD "The signal indicates the standard deviation to the yaw rate.";
CM_ SG_ 2331595779 SOK_NR_FL_Object_07_08_Signatur "Signatur im Rahmen der durch SOK geschützen Broadcast-Kommunikation
";
BA_DEF_REL_ BU_SG_REL_  "GenSigTimeoutTime" INT 0 65535;
BA_DEF_ BO_  "DiagRequest" ENUM "No", "Yes";
BA_DEF_ BO_  "DiagResponse" ENUM "No", "Yes";
BA_DEF_ BO_  "DiagState" ENUM "No", "Yes";
BA_DEF_ BO_  "GenMsgChkConstant" HEX 0 4095;
BA_DEF_ BO_  "GenMsgCycleTime" INT 0 65535;
BA_DEF_ BO_  "GenMsgCycleTimeFast" INT 0 65535;
BA_DEF_ BO_  "GenMsgDelayTime" INT 0 100000;
BA_DEF_ BO_  "GenMsgILSupport" ENUM "No", "Yes";
BA_DEF_ BO_  "GenMsgNrOfRepetition" INT 0 100;
BA_DEF_ BO_  "GenMsgPDUConstants" STRING;
BA_DEF_ BO_  "GenMsgSendType" ENUM "Cyclic", "not_used", "not_used", "not_used", "not_used", "not_used", "not_used", "IfActive", "NoMsgSendType";
BA_DEF_ BO_  "GenMsgStartDelayTime" INT 0 100000;
BA_DEF_ BO_  "NmMessage" ENUM "No", "Yes";
BA_DEF_ BO_  "NmhMessage" ENUM "No", "Yes";
BA_DEF_ BO_  "MsgType" ENUM "Application", "NM ", "NMH", "TP2.0", "ISO-TP ", "BAP", "EID", "KS", "XCP_PRE_CONFIGURED", "XCP_RUNTIME_CONFIGURED";
BA_DEF_ BO_  "VAGTP20_API" HEX 0 255;
BA_DEF_ BO_  "VAGTP20_DynConnection" ENUM "No", "Yes";
BA_DEF_ BO_  "VAGTP20_DynSetup" ENUM "No", "Yes";
BA_DEF_ BO_  "VAGTP20_StatConnection" ENUM "No", "Yes";
BA_DEF_ BO_  "CANFD_BRS" ENUM "0", "1";
BA_DEF_ BO_  "VFrameFormat" ENUM "StandardCAN", "ExtendedCAN", "reserved", "reserved", "reserved", "reserved", "reserved", "reserved", "reserved", "reserved", "reserved", "reserved", "reserved", "reserved", "StandardCAN_FD", "ExtendedCAN_FD";
BA_DEF_ SG_  "GenSigActiveRepetitions" INT -2147483648 2147483647;
BA_DEF_ SG_  "GenSigInactiveValue" INT -2147483648 2147483647;
BA_DEF_ SG_  "GenSigSendType" ENUM "Cyclic", "OnWrite", "OnWriteWithRepetition", "OnChange", "OnChangeWithRepetition", "IfActive", "IfActiveWithRepetition", "NoSigSendType", "OnChangeAndIfActive", "OnChangeAndIfActiveWithRepetition";
BA_DEF_ SG_  "GenSigStartValue" INT -2147483648 2147483647;
BA_DEF_ SG_  "NWM-WakeupAllowed" ENUM "No", "Yes";
BA_DEF_ SG_  "GenSigFuncType" ENUM "NoFunction", "MsgCounter", "CRC-8", "XOR", "XOR-2", "DatedBit", "SW-Kl15", "CHK", "Constant", "Protocol", "CRC-8-SAE_J1850", "CRC-32", "DataLength", "DataID", "MsgCounter16", "SOK-Signatur", "Cluster";
BA_DEF_ SG_  "GenSigSwitchedByIgnition" ENUM "No", "Yes";
BA_DEF_ SG_  "Fehlerwert" HEX 0 2147483647;
BA_DEF_ SG_  "GenSigMissingSourceValue" HEX 0 2147483647;
BA_DEF_DEF_REL_  "GenSigTimeoutTime" 0;
BA_DEF_DEF_  "DiagRequest" "No";
BA_DEF_DEF_  "DiagResponse" "No";
BA_DEF_DEF_  "DiagState" "No";
BA_DEF_DEF_  "GenMsgChkConstant" 0;
BA_DEF_DEF_  "GenMsgCycleTime" 0;
BA_DEF_DEF_  "GenMsgCycleTimeFast" 0;
BA_DEF_DEF_  "GenMsgDelayTime" 0;
BA_DEF_DEF_  "GenMsgILSupport" "No";
BA_DEF_DEF_  "GenMsgNrOfRepetition" 0;
BA_DEF_DEF_  "GenMsgPDUConstants" "";
BA_DEF_DEF_  "GenMsgSendType" "NoMsgSendType";
BA_DEF_DEF_  "GenMsgStartDelayTime" 0;
BA_DEF_DEF_  "NmMessage" "No";
BA_DEF_DEF_  "NmhMessage" "No";
BA_DEF_DEF_  "MsgType" "Application";
BA_DEF_DEF_  "VAGTP20_API" 0;
BA_DEF_DEF_  "VAGTP20_DynConnection" "No";
BA_DEF_DEF_  "VAGTP20_DynSetup" "No";
BA_DEF_DEF_  "VAGTP20_StatConnection" "No";
BA_DEF_DEF_  "CANFD_BRS" "1";
BA_DEF_DEF_  "VFrameFormat" "StandardCAN";
BA_DEF_DEF_  "GenSigActiveRepetitions" 0;
BA_DEF_DEF_  "GenSigInactiveValue" 0;
BA_DEF_DEF_  "GenSigSendType" "NoSigSendType";
BA_DEF_DEF_  "GenSigStartValue" 0;
BA_DEF_DEF_  "NWM-WakeupAllowed" "No";
BA_DEF_DEF_  "GenSigFuncType" "NoFunction";
BA_DEF_DEF_  "GenSigSwitchedByIgnition" "Yes";
BA_DEF_DEF_  "Fehlerwert" 0;
BA_DEF_DEF_  "GenSigMissingSourceValue" 0;
BA_ "GenMsgCycleTime" BO_ 2600468567 200;
BA_ "GenMsgCycleTimeFast" BO_ 2600468567 10;
BA_ "NmhMessage" BO_ 2600468567 1;
BA_ "MsgType" BO_ 2600468567 2;
BA_ "CANFD_BRS" BO_ 2600468567 0;
BA_ "VFrameFormat" BO_ 2600468567 1;
BA_ "GenMsgCycleTime" BO_ 2600468496 200;
BA_ "GenMsgCycleTimeFast" BO_ 2600468496 10;
BA_ "NmhMessage" BO_ 2600468496 1;
BA_ "MsgType" BO_ 2600468496 2;
BA_ "CANFD_BRS" BO_ 2600468496 0;
BA_ "VFrameFormat" BO_ 2600468496 1;
BA_ "GenMsgCycleTime" BO_ 2600468559 200;
BA_ "GenMsgCycleTimeFast" BO_ 2600468559 10;
BA_ "NmhMessage" BO_ 2600468559 1;
BA_ "MsgType" BO_ 2600468559 2;
BA_ "CANFD_BRS" BO_ 2600468559 0;
BA_ "VFrameFormat" BO_ 2600468559 1;
BA_ "GenMsgCycleTime" BO_ 2600468667 200;
BA_ "GenMsgCycleTimeFast" BO_ 2600468667 10;
BA_ "NmhMessage" BO_ 2600468667 1;
BA_ "MsgType" BO_ 2600468667 2;
BA_ "CANFD_BRS" BO_ 2600468667 0;
BA_ "VFrameFormat" BO_ 2600468667 1;
BA_ "GenMsgCycleTime" BO_ 2600468668 200;
BA_ "GenMsgCycleTimeFast" BO_ 2600468668 10;
BA_ "NmhMessage" BO_ 2600468668 1;
BA_ "MsgType" BO_ 2600468668 2;
BA_ "CANFD_BRS" BO_ 2600468668 0;
BA_ "VFrameFormat" BO_ 2600468668 1;
BA_ "GenMsgCycleTime" BO_ 2589283909 1000;
BA_ "GenMsgDelayTime" BO_ 2589283909 200;
BA_ "GenMsgILSupport" BO_ 2589283909 1;
BA_ "GenMsgSendType" BO_ 2589283909 0;
BA_ "VFrameFormat" BO_ 2589283909 15;
BA_ "GenMsgCycleTime" BO_ 2589283910 1000;
BA_ "GenMsgDelayTime" BO_ 2589283910 200;
BA_ "GenMsgILSupport" BO_ 2589283910 1;
BA_ "GenMsgSendType" BO_ 2589283910 0;
BA_ "VFrameFormat" BO_ 2589283910 15;
BA_ "GenMsgCycleTime" BO_ 2589283911 1000;
BA_ "GenMsgDelayTime" BO_ 2589283911 200;
BA_ "GenMsgILSupport" BO_ 2589283911 1;
BA_ "GenMsgSendType" BO_ 2589283911 0;
BA_ "VFrameFormat" BO_ 2589283911 15;
BA_ "GenMsgCycleTime" BO_ 2527679889 1000;
BA_ "GenMsgCycleTimeFast" BO_ 2527679889 100;
BA_ "GenMsgILSupport" BO_ 2527679889 1;
BA_ "GenMsgSendType" BO_ 2527679889 0;
BA_ "VFrameFormat" BO_ 2527679889 15;
BA_ "GenMsgCycleTime" BO_ 2589283912 1000;
BA_ "GenMsgDelayTime" BO_ 2589283912 200;
BA_ "GenMsgILSupport" BO_ 2589283912 1;
BA_ "GenMsgSendType" BO_ 2589283912 0;
BA_ "VFrameFormat" BO_ 2589283912 15;
BA_ "GenMsgCycleTime" BO_ 2589283913 1000;
BA_ "GenMsgDelayTime" BO_ 2589283913 200;
BA_ "GenMsgILSupport" BO_ 2589283913 1;
BA_ "GenMsgSendType" BO_ 2589283913 0;
BA_ "VFrameFormat" BO_ 2589283913 15;
BA_ "GenMsgCycleTime" BO_ 2589283914 1000;
BA_ "GenMsgDelayTime" BO_ 2589283914 200;
BA_ "GenMsgILSupport" BO_ 2589283914 1;
BA_ "GenMsgSendType" BO_ 2589283914 0;
BA_ "VFrameFormat" BO_ 2589283914 15;
BA_ "GenMsgCycleTime" BO_ 2331595825 50;
BA_ "GenMsgILSupport" BO_ 2331595825 1;
BA_ "GenMsgSendType" BO_ 2331595825 0;
BA_ "VFrameFormat" BO_ 2331595825 15;
BA_ "GenMsgCycleTime" BO_ 2331595790 50;
BA_ "GenMsgILSupport" BO_ 2331595790 1;
BA_ "GenMsgPDUConstants" BO_ 2331595790 "0x8d,0x78,0x0c,0x68,0x7e,0x3a,0x5e,0x31,0xeb,0x16,0x1e,0x08,0x3d,0x4f,0x8f,0xde";
BA_ "GenMsgSendType" BO_ 2331595790 0;
BA_ "VFrameFormat" BO_ 2331595790 15;
BA_ "GenMsgCycleTime" BO_ 2331595781 50;
BA_ "GenMsgILSupport" BO_ 2331595781 1;
BA_ "GenMsgPDUConstants" BO_ 2331595781 "0xe0,0x30,0x5a,0xf5,0xe6,0x04,0x6b,0x10,0xdb,0x58,0x21,0x4c,0x7c,0x3e,0xed,0xaa";
BA_ "GenMsgSendType" BO_ 2331595781 0;
BA_ "VFrameFormat" BO_ 2331595781 15;
BA_ "GenMsgCycleTime" BO_ 2331595776 50;
BA_ "GenMsgILSupport" BO_ 2331595776 1;
BA_ "GenMsgPDUConstants" BO_ 2331595776 "0xa9,0x4d,0x9c,0xb9,0x8d,0x2d,0x76,0x36,0x4b,0x78,0xb4,0xea,0x21,0x52,0x0c,0x3b";
BA_ "GenMsgSendType" BO_ 2331595776 0;
BA_ "VFrameFormat" BO_ 2331595776 15;
BA_ "GenMsgCycleTime" BO_ 2331595777 50;
BA_ "GenMsgILSupport" BO_ 2331595777 1;
BA_ "GenMsgPDUConstants" BO_ 2331595777 "0xa0,0x7c,0x1f,0xf6,0x43,0x2e,0xc0,0x74,0xb8,0xc3,0x9f,0x26,0x68,0x61,0xfb,0x70";
BA_ "GenMsgSendType" BO_ 2331595777 0;
BA_ "VFrameFormat" BO_ 2331595777 15;
BA_ "GenMsgCycleTime" BO_ 2331595778 50;
BA_ "GenMsgILSupport" BO_ 2331595778 1;
BA_ "GenMsgPDUConstants" BO_ 2331595778 "0xbe,0x17,0x52,0x1d,0xc4,0x8c,0x15,0x3c,0x50,0xe2,0x9e,0xee,0x8b,0xb8,0x4f,0x54";
BA_ "GenMsgSendType" BO_ 2331595778 0;
BA_ "VFrameFormat" BO_ 2331595778 15;
BA_ "GenMsgCycleTime" BO_ 2331595779 50;
BA_ "GenMsgILSupport" BO_ 2331595779 1;
BA_ "GenMsgPDUConstants" BO_ 2331595779 "0xd8,0xc4,0x5e,0xe2,0xcb,0x4f,0x4e,0xe4,0x33,0xf8,0x48,0x2f,0xa4,0x56,0xf0,0x81";
BA_ "GenMsgSendType" BO_ 2331595779 0;
BA_ "VFrameFormat" BO_ 2331595779 15;
BA_ "GenSigFuncType" SG_ 2600468567 NM_ACC_CAB_V15 16;
BA_ "GenSigSwitchedByIgnition" SG_ 2600468567 NM_ACC_CAB_V15 0;
BA_ "GenSigSwitchedByIgnition" SG_ 2600468567 NM_ACC_Car_Wakeup 0;
BA_ "GenSigSwitchedByIgnition" SG_ 2600468567 NM_ACC_CBV_AWB 0;
BA_ "GenSigSwitchedByIgnition" SG_ 2600468567 NM_ACC_CBV_CRI 0;
BA_ "GenSigSwitchedByIgnition" SG_ 2600468567 NM_ACC_NM_aktiv_Diagnose 0;
BA_ "GenSigSwitchedByIgnition" SG_ 2600468567 NM_ACC_NM_aktiv_KL15 0;
BA_ "GenSigSwitchedByIgnition" SG_ 2600468567 NM_ACC_NM_aktiv_Tmin 0;
BA_ "GenSigSwitchedByIgnition" SG_ 2600468567 NM_ACC_NM_State 0;
BA_ "GenSigSwitchedByIgnition" SG_ 2600468567 NM_ACC_UDS_CC 0;
BA_ "GenSigFuncType" SG_ 2600468496 NM_Gateway_CAB_V15 16;
BA_ "GenSigSwitchedByIgnition" SG_ 2600468496 NM_Gateway_CAB_V15 0;
BA_ "GenSigSwitchedByIgnition" SG_ 2600468496 NM_Gateway_Car_Wakeup 0;
BA_ "GenSigSwitchedByIgnition" SG_ 2600468496 NM_Gateway_CBV_AWB 0;
BA_ "GenSigSwitchedByIgnition" SG_ 2600468496 NM_Gateway_CBV_CRI 0;
BA_ "GenSigSwitchedByIgnition" SG_ 2600468496 NM_Gateway_NM_aktiv_CAB 0;
BA_ "GenSigSwitchedByIgnition" SG_ 2600468496 NM_Gateway_NM_aktiv_Diagnose 0;
BA_ "GenSigSwitchedByIgnition" SG_ 2600468496 NM_Gateway_NM_aktiv_Energie 0;
BA_ "GenSigSwitchedByIgnition" SG_ 2600468496 NM_Gateway_NM_aktiv_FoD 0;
BA_ "GenSigSwitchedByIgnition" SG_ 2600468496 NM_Gateway_NM_aktiv_IAA_PSO 0;
BA_ "GenSigSwitchedByIgnition" SG_ 2600468496 NM_Gateway_NM_aktiv_Kessy 0;
BA_ "GenSigSwitchedByIgnition" SG_ 2600468496 NM_Gateway_NM_aktiv_KL15 0;
BA_ "GenSigSwitchedByIgnition" SG_ 2600468496 NM_Gateway_NM_aktiv_KS 0;
BA_ "GenSigSwitchedByIgnition" SG_ 2600468496 NM_Gateway_NM_aktiv_Licht 0;
BA_ "GenSigSwitchedByIgnition" SG_ 2600468496 NM_Gateway_NM_aktiv_PaCo 0;
BA_ "GenSigSwitchedByIgnition" SG_ 2600468496 NM_Gateway_NM_aktiv_RTM 0;
BA_ "GenSigSwitchedByIgnition" SG_ 2600468496 NM_Gateway_NM_aktiv_Standklima 0;
BA_ "GenSigSwitchedByIgnition" SG_ 2600468496 NM_Gateway_NM_aktiv_Tmin 0;
BA_ "GenSigSwitchedByIgnition" SG_ 2600468496 NM_Gateway_NM_aktiv_USS 0;
BA_ "GenSigSwitchedByIgnition" SG_ 2600468496 NM_Gateway_NM_aktiv_ZM 0;
BA_ "GenSigSwitchedByIgnition" SG_ 2600468496 NM_Gateway_NM_aktiv_ZV 0;
BA_ "GenSigSwitchedByIgnition" SG_ 2600468496 NM_Gateway_NM_State 0;
BA_ "GenSigSwitchedByIgnition" SG_ 2600468496 NM_Gateway_UDS_CC 0;
BA_ "GenSigFuncType" SG_ 2600468559 NM_Kamera_CAB_V15 16;
BA_ "GenSigSwitchedByIgnition" SG_ 2600468559 NM_Kamera_CAB_V15 0;
BA_ "GenSigSwitchedByIgnition" SG_ 2600468559 NM_Kamera_Car_Wakeup 0;
BA_ "GenSigSwitchedByIgnition" SG_ 2600468559 NM_Kamera_CBV_AWB 0;
BA_ "GenSigSwitchedByIgnition" SG_ 2600468559 NM_Kamera_CBV_CRI 0;
BA_ "GenSigSwitchedByIgnition" SG_ 2600468559 NM_Kamera_NM_aktiv_Diagnose 0;
BA_ "GenSigSwitchedByIgnition" SG_ 2600468559 NM_Kamera_NM_aktiv_KL15 0;
BA_ "GenSigSwitchedByIgnition" SG_ 2600468559 NM_Kamera_NM_aktiv_Tmin 0;
BA_ "GenSigSwitchedByIgnition" SG_ 2600468559 NM_Kamera_NM_State 0;
BA_ "GenSigSwitchedByIgnition" SG_ 2600468559 NM_Kamera_UDS_CC 0;
BA_ "GenSigFuncType" SG_ 2600468667 NM_NR_01_CAB_V15 16;
BA_ "GenSigSwitchedByIgnition" SG_ 2600468667 NM_NR_01_CAB_V15 0;
BA_ "GenSigSwitchedByIgnition" SG_ 2600468667 NM_NR_01_Car_Wakeup 0;
BA_ "GenSigSwitchedByIgnition" SG_ 2600468667 NM_NR_01_CBV_AWB 0;
BA_ "GenSigSwitchedByIgnition" SG_ 2600468667 NM_NR_01_CBV_CRI 0;
BA_ "GenSigSwitchedByIgnition" SG_ 2600468667 NM_NR_01_NM_aktiv_Diagnose 0;
BA_ "GenSigSwitchedByIgnition" SG_ 2600468667 NM_NR_01_NM_aktiv_KL15 0;
BA_ "GenSigSwitchedByIgnition" SG_ 2600468667 NM_NR_01_NM_aktiv_Tmin 0;
BA_ "GenSigSwitchedByIgnition" SG_ 2600468667 NM_NR_01_NM_State 0;
BA_ "GenSigSwitchedByIgnition" SG_ 2600468667 NM_NR_01_UDS_CC 0;
BA_ "GenSigFuncType" SG_ 2600468668 NM_NR_02_CAB_V15 16;
BA_ "GenSigSwitchedByIgnition" SG_ 2600468668 NM_NR_02_CAB_V15 0;
BA_ "GenSigSwitchedByIgnition" SG_ 2600468668 NM_NR_02_Car_Wakeup 0;
BA_ "GenSigSwitchedByIgnition" SG_ 2600468668 NM_NR_02_CBV_AWB 0;
BA_ "GenSigSwitchedByIgnition" SG_ 2600468668 NM_NR_02_CBV_CRI 0;
BA_ "GenSigSwitchedByIgnition" SG_ 2600468668 NM_NR_02_NM_aktiv_Diagnose 0;
BA_ "GenSigSwitchedByIgnition" SG_ 2600468668 NM_NR_02_NM_aktiv_KL15 0;
BA_ "GenSigSwitchedByIgnition" SG_ 2600468668 NM_NR_02_NM_aktiv_Tmin 0;
BA_ "GenSigSwitchedByIgnition" SG_ 2600468668 NM_NR_02_NM_State 0;
BA_ "GenSigSwitchedByIgnition" SG_ 2600468668 NM_NR_02_UDS_CC 0;
BA_ "GenSigSendType" SG_ 2589283909 NR_01_CAL_Text_Data_1 3;
BA_ "GenSigSendType" SG_ 2589283909 NR_01_CAL_Text_Request 3;
BA_ "GenSigSendType" SG_ 2589283910 NR_01_CAL_Text_Data_2 3;
BA_ "GenSigSendType" SG_ 2589283911 NR_01_CAL_Text_Data_3 3;
BA_ "GenSigSendType" SG_ 2527679889 NR_02_CAL_LgtLimV_StAcv 5;
BA_ "GenSigStartValue" SG_ 2527679889 NR_02_CAL_LgtLimV_StAcv 2;
BA_ "Fehlerwert" SG_ 2527679889 NR_02_CAL_LgtLimV_StAcv 3;
BA_ "GenSigInactiveValue" SG_ 2527679889 NR_02_CAL_LgtLimV_VDmd 125;
BA_ "GenSigSendType" SG_ 2527679889 NR_02_CAL_LgtLimV_VDmd 5;
BA_ "GenSigStartValue" SG_ 2527679889 NR_02_CAL_LgtLimV_VDmd 126;
BA_ "Fehlerwert" SG_ 2527679889 NR_02_CAL_LgtLimV_VDmd 127;
BA_ "GenSigSendType" SG_ 2589283912 NR_02_CAL_Text_Data_1 3;
BA_ "GenSigSendType" SG_ 2589283912 NR_02_CAL_Text_Request 3;
BA_ "GenSigSendType" SG_ 2589283913 NR_02_CAL_Text_Data_2 3;
BA_ "GenSigSendType" SG_ 2589283914 NR_02_CAL_Text_Data_3 3;
BA_ "GenSigSendType" SG_ 2331595825 NR_FL_Cal_resp 0;
BA_ "GenSigSendType" SG_ 2331595825 NR_FL_CalibrationMode 0;
BA_ "GenSigSendType" SG_ 2331595825 NR_FL_QualFactorAutoCalib 0;
BA_ "GenSigSendType" SG_ 2331595825 NR_FL_resp_val 0;
BA_ "GenSigSendType" SG_ 2331595825 NR_FL_ShortTrackCal_State 0;
BA_ "GenSigStartValue" SG_ 2331595825 NR_FL_ShortTrackCal_State 7;
BA_ "GenSigSendType" SG_ 2331595790 NR_FL_Contour_BlockID_01 0;
BA_ "GenSigSendType" SG_ 2331595790 NR_FL_Contour_BZ 0;
BA_ "GenSigFuncType" SG_ 2331595790 NR_FL_Contour_BZ 1;
BA_ "GenSigSwitchedByIgnition" SG_ 2331595790 NR_FL_Contour_BZ 0;
BA_ "GenSigSendType" SG_ 2331595790 NR_FL_Contour_CRC 0;
BA_ "GenSigFuncType" SG_ 2331595790 NR_FL_Contour_CRC 2;
BA_ "GenSigSwitchedByIgnition" SG_ 2331595790 NR_FL_Contour_CRC 0;
BA_ "GenSigSendType" SG_ 2331595790 NR_FL_Contour_left_01_Age 0;
BA_ "GenSigStartValue" SG_ 2331595790 NR_FL_Contour_left_01_Age 127;
BA_ "GenSigSendType" SG_ 2331595790 NR_FL_Contour_left_01_Type 0;
BA_ "GenSigStartValue" SG_ 2331595790 NR_FL_Contour_left_01_Type 7;
BA_ "GenSigSendType" SG_ 2331595790 NR_FL_Contour_left_01_x01 0;
BA_ "GenSigStartValue" SG_ 2331595790 NR_FL_Contour_left_01_x01 8191;
BA_ "GenSigSendType" SG_ 2331595790 NR_FL_Contour_left_01_x02 0;
BA_ "GenSigStartValue" SG_ 2331595790 NR_FL_Contour_left_01_x02 8191;
BA_ "GenSigSendType" SG_ 2331595790 NR_FL_Contour_left_01_x03 0;
BA_ "GenSigStartValue" SG_ 2331595790 NR_FL_Contour_left_01_x03 8191;
BA_ "GenSigSendType" SG_ 2331595790 NR_FL_Contour_left_01_x04 0;
BA_ "GenSigStartValue" SG_ 2331595790 NR_FL_Contour_left_01_x04 8191;
BA_ "GenSigSendType" SG_ 2331595790 NR_FL_Contour_left_01_x05 0;
BA_ "GenSigStartValue" SG_ 2331595790 NR_FL_Contour_left_01_x05 8191;
BA_ "GenSigSendType" SG_ 2331595790 NR_FL_Contour_left_01_x06 0;
BA_ "GenSigStartValue" SG_ 2331595790 NR_FL_Contour_left_01_x06 8191;
BA_ "GenSigSendType" SG_ 2331595790 NR_FL_Contour_left_01_x07 0;
BA_ "GenSigStartValue" SG_ 2331595790 NR_FL_Contour_left_01_x07 8191;
BA_ "GenSigSendType" SG_ 2331595790 NR_FL_Contour_left_01_y01 0;
BA_ "GenSigStartValue" SG_ 2331595790 NR_FL_Contour_left_01_y01 2047;
BA_ "GenSigSendType" SG_ 2331595790 NR_FL_Contour_left_01_y02 0;
BA_ "GenSigStartValue" SG_ 2331595790 NR_FL_Contour_left_01_y02 2047;
BA_ "GenSigSendType" SG_ 2331595790 NR_FL_Contour_left_01_y03 0;
BA_ "GenSigStartValue" SG_ 2331595790 NR_FL_Contour_left_01_y03 2047;
BA_ "GenSigSendType" SG_ 2331595790 NR_FL_Contour_left_01_y04 0;
BA_ "GenSigStartValue" SG_ 2331595790 NR_FL_Contour_left_01_y04 2047;
BA_ "GenSigSendType" SG_ 2331595790 NR_FL_Contour_left_01_y05 0;
BA_ "GenSigStartValue" SG_ 2331595790 NR_FL_Contour_left_01_y05 2047;
BA_ "GenSigSendType" SG_ 2331595790 NR_FL_Contour_left_01_y06 0;
BA_ "GenSigStartValue" SG_ 2331595790 NR_FL_Contour_left_01_y06 2047;
BA_ "GenSigSendType" SG_ 2331595790 NR_FL_Contour_left_01_y07 0;
BA_ "GenSigStartValue" SG_ 2331595790 NR_FL_Contour_left_01_y07 2047;
BA_ "GenSigSendType" SG_ 2331595790 NR_FL_Contour_left_02_Age 0;
BA_ "GenSigStartValue" SG_ 2331595790 NR_FL_Contour_left_02_Age 127;
BA_ "GenSigSendType" SG_ 2331595790 NR_FL_Contour_left_02_Type 0;
BA_ "GenSigStartValue" SG_ 2331595790 NR_FL_Contour_left_02_Type 7;
BA_ "GenSigSendType" SG_ 2331595790 NR_FL_Contour_left_02_x01 0;
BA_ "GenSigStartValue" SG_ 2331595790 NR_FL_Contour_left_02_x01 8191;
BA_ "GenSigSendType" SG_ 2331595790 NR_FL_Contour_left_02_x02 0;
BA_ "GenSigStartValue" SG_ 2331595790 NR_FL_Contour_left_02_x02 8191;
BA_ "GenSigSendType" SG_ 2331595790 NR_FL_Contour_left_02_x03 0;
BA_ "GenSigStartValue" SG_ 2331595790 NR_FL_Contour_left_02_x03 8191;
BA_ "GenSigSendType" SG_ 2331595790 NR_FL_Contour_left_02_x04 0;
BA_ "GenSigStartValue" SG_ 2331595790 NR_FL_Contour_left_02_x04 8191;
BA_ "GenSigSendType" SG_ 2331595790 NR_FL_Contour_left_02_x05 0;
BA_ "GenSigStartValue" SG_ 2331595790 NR_FL_Contour_left_02_x05 8191;
BA_ "GenSigSendType" SG_ 2331595790 NR_FL_Contour_left_02_x06 0;
BA_ "GenSigStartValue" SG_ 2331595790 NR_FL_Contour_left_02_x06 8191;
BA_ "GenSigSendType" SG_ 2331595790 NR_FL_Contour_left_02_x07 0;
BA_ "GenSigStartValue" SG_ 2331595790 NR_FL_Contour_left_02_x07 8191;
BA_ "GenSigSendType" SG_ 2331595790 NR_FL_Contour_left_02_y01 0;
BA_ "GenSigStartValue" SG_ 2331595790 NR_FL_Contour_left_02_y01 2047;
BA_ "GenSigSendType" SG_ 2331595790 NR_FL_Contour_left_02_y02 0;
BA_ "GenSigStartValue" SG_ 2331595790 NR_FL_Contour_left_02_y02 2047;
BA_ "GenSigSendType" SG_ 2331595790 NR_FL_Contour_left_02_y03 0;
BA_ "GenSigStartValue" SG_ 2331595790 NR_FL_Contour_left_02_y03 2047;
BA_ "GenSigSendType" SG_ 2331595790 NR_FL_Contour_left_02_y04 0;
BA_ "GenSigStartValue" SG_ 2331595790 NR_FL_Contour_left_02_y04 2047;
BA_ "GenSigSendType" SG_ 2331595790 NR_FL_Contour_left_02_y05 0;
BA_ "GenSigStartValue" SG_ 2331595790 NR_FL_Contour_left_02_y05 2047;
BA_ "GenSigSendType" SG_ 2331595790 NR_FL_Contour_left_02_y06 0;
BA_ "GenSigStartValue" SG_ 2331595790 NR_FL_Contour_left_02_y06 2047;
BA_ "GenSigSendType" SG_ 2331595790 NR_FL_Contour_left_02_y07 0;
BA_ "GenSigStartValue" SG_ 2331595790 NR_FL_Contour_left_02_y07 2047;
BA_ "GenSigSendType" SG_ 2331595790 NR_FL_Contour_left_Linkage 0;
BA_ "GenSigStartValue" SG_ 2331595790 NR_FL_Contour_left_Linkage 1;
BA_ "GenSigSendType" SG_ 2331595790 SOK_NR_FL_Contour_Signatur 0;
BA_ "GenSigFuncType" SG_ 2331595790 SOK_NR_FL_Contour_Signatur 15;
BA_ "GenSigSendType" SG_ 2331595781 NR_FL_Blindness 0;
BA_ "GenSigSendType" SG_ 2331595781 NR_FL_BlockID_01 0;
BA_ "GenSigSendType" SG_ 2331595781 NR_FL_CalibrationState 0;
BA_ "GenSigSendType" SG_ 2331595781 NR_FL_Failure 0;
BA_ "GenSigSendType" SG_ 2331595781 NR_FL_Freesight_NOK 0;
BA_ "GenSigSendType" SG_ 2331595781 NR_FL_Header_BZ 0;
BA_ "GenSigFuncType" SG_ 2331595781 NR_FL_Header_BZ 1;
BA_ "GenSigSwitchedByIgnition" SG_ 2331595781 NR_FL_Header_BZ 0;
BA_ "GenSigSendType" SG_ 2331595781 NR_FL_Header_CRC 0;
BA_ "GenSigFuncType" SG_ 2331595781 NR_FL_Header_CRC 2;
BA_ "GenSigSwitchedByIgnition" SG_ 2331595781 NR_FL_Header_CRC 0;
BA_ "GenSigSendType" SG_ 2331595781 NR_FL_MeasurementTimeHigh 0;
BA_ "GenSigSendType" SG_ 2331595781 NR_FL_MeasurementTimeLapNumber 0;
BA_ "Fehlerwert" SG_ 2331595781 NR_FL_MeasurementTimeLapNumber 16383;
BA_ "GenSigSendType" SG_ 2331595781 NR_FL_MeasurementTimeLow 0;
BA_ "GenSigSendType" SG_ 2331595781 NR_FL_MeasurementTimeStatus 0;
BA_ "GenSigSendType" SG_ 2331595781 NR_FL_NotAvailable 0;
BA_ "GenSigStartValue" SG_ 2331595781 NR_FL_NotAvailable 1;
BA_ "GenSigSendType" SG_ 2331595781 NR_FL_RangeDegradation_Sect1 0;
BA_ "GenSigSendType" SG_ 2331595781 NR_FL_RangeDegradation_Sect2 0;
BA_ "GenSigSendType" SG_ 2331595781 NR_FL_RangeDegradation_Sect3 0;
BA_ "GenSigSendType" SG_ 2331595781 SOK_NR_FL_Header_Signatur 0;
BA_ "GenSigFuncType" SG_ 2331595781 SOK_NR_FL_Header_Signatur 15;
BA_ "GenSigSendType" SG_ 2331595776 NR_FL_Object_01_02_BlockID_01 0;
BA_ "GenSigSendType" SG_ 2331595776 NR_FL_Object_01_02_BZ 0;
BA_ "GenSigFuncType" SG_ 2331595776 NR_FL_Object_01_02_BZ 1;
BA_ "GenSigSwitchedByIgnition" SG_ 2331595776 NR_FL_Object_01_02_BZ 0;
BA_ "GenSigSendType" SG_ 2331595776 NR_FL_Object_01_02_CRC 0;
BA_ "GenSigFuncType" SG_ 2331595776 NR_FL_Object_01_02_CRC 2;
BA_ "GenSigSwitchedByIgnition" SG_ 2331595776 NR_FL_Object_01_02_CRC 0;
BA_ "GenSigSendType" SG_ 2331595776 NR_FL_Object_01_aAbsX 0;
BA_ "GenSigStartValue" SG_ 2331595776 NR_FL_Object_01_aAbsX 511;
BA_ "GenSigSendType" SG_ 2331595776 NR_FL_Object_01_aAbsXSD 0;
BA_ "GenSigStartValue" SG_ 2331595776 NR_FL_Object_01_aAbsXSD 63;
BA_ "GenSigSendType" SG_ 2331595776 NR_FL_Object_01_aAbsY 0;
BA_ "GenSigStartValue" SG_ 2331595776 NR_FL_Object_01_aAbsY 511;
BA_ "GenSigSendType" SG_ 2331595776 NR_FL_Object_01_aAbsYSD 0;
BA_ "GenSigStartValue" SG_ 2331595776 NR_FL_Object_01_aAbsYSD 63;
BA_ "GenSigSendType" SG_ 2331595776 NR_FL_Object_01_Age 0;
BA_ "GenSigStartValue" SG_ 2331595776 NR_FL_Object_01_Age 127;
BA_ "GenSigSendType" SG_ 2331595776 NR_FL_Object_01_Class 0;
BA_ "GenSigStartValue" SG_ 2331595776 NR_FL_Object_01_Class 15;
BA_ "GenSigSendType" SG_ 2331595776 NR_FL_Object_01_ClassPlausib 0;
BA_ "GenSigStartValue" SG_ 2331595776 NR_FL_Object_01_ClassPlausib 15;
BA_ "GenSigSendType" SG_ 2331595776 NR_FL_Object_01_DynamicState 0;
BA_ "GenSigStartValue" SG_ 2331595776 NR_FL_Object_01_DynamicState 3;
BA_ "GenSigSendType" SG_ 2331595776 NR_FL_Object_01_ExistProb 0;
BA_ "GenSigStartValue" SG_ 2331595776 NR_FL_Object_01_ExistProb 127;
BA_ "GenSigSendType" SG_ 2331595776 NR_FL_Object_01_ID 0;
BA_ "GenSigStartValue" SG_ 2331595776 NR_FL_Object_01_ID 255;
BA_ "GenSigSendType" SG_ 2331595776 NR_FL_Object_01_Length 0;
BA_ "GenSigStartValue" SG_ 2331595776 NR_FL_Object_01_Length 1023;
BA_ "GenSigSendType" SG_ 2331595776 NR_FL_Object_01_LengthSD 0;
BA_ "GenSigStartValue" SG_ 2331595776 NR_FL_Object_01_LengthSD 127;
BA_ "GenSigSendType" SG_ 2331595776 NR_FL_Object_01_MeasurementState 0;
BA_ "GenSigSendType" SG_ 2331595776 NR_FL_Object_01_PosX 0;
BA_ "GenSigStartValue" SG_ 2331595776 NR_FL_Object_01_PosX 16383;
BA_ "GenSigSendType" SG_ 2331595776 NR_FL_Object_01_PosXSD 0;
BA_ "GenSigStartValue" SG_ 2331595776 NR_FL_Object_01_PosXSD 255;
BA_ "GenSigSendType" SG_ 2331595776 NR_FL_Object_01_PosY 0;
BA_ "GenSigStartValue" SG_ 2331595776 NR_FL_Object_01_PosY 8191;
BA_ "GenSigSendType" SG_ 2331595776 NR_FL_Object_01_PosYSD 0;
BA_ "GenSigStartValue" SG_ 2331595776 NR_FL_Object_01_PosYSD 255;
BA_ "GenSigSendType" SG_ 2331595776 NR_FL_Object_01_ReferencePoint 0;
BA_ "GenSigStartValue" SG_ 2331595776 NR_FL_Object_01_ReferencePoint 15;
BA_ "GenSigSendType" SG_ 2331595776 NR_FL_Object_01_vAbsX 0;
BA_ "GenSigStartValue" SG_ 2331595776 NR_FL_Object_01_vAbsX 4095;
BA_ "GenSigSendType" SG_ 2331595776 NR_FL_Object_01_vAbsXSD 0;
BA_ "GenSigStartValue" SG_ 2331595776 NR_FL_Object_01_vAbsXSD 63;
BA_ "GenSigSendType" SG_ 2331595776 NR_FL_Object_01_vAbsY 0;
BA_ "GenSigStartValue" SG_ 2331595776 NR_FL_Object_01_vAbsY 4095;
BA_ "GenSigSendType" SG_ 2331595776 NR_FL_Object_01_vAbsYSD 0;
BA_ "GenSigStartValue" SG_ 2331595776 NR_FL_Object_01_vAbsYSD 63;
BA_ "GenSigSendType" SG_ 2331595776 NR_FL_Object_01_Width 0;
BA_ "GenSigStartValue" SG_ 2331595776 NR_FL_Object_01_Width 255;
BA_ "GenSigSendType" SG_ 2331595776 NR_FL_Object_01_WidthSD 0;
BA_ "GenSigStartValue" SG_ 2331595776 NR_FL_Object_01_WidthSD 127;
BA_ "GenSigSendType" SG_ 2331595776 NR_FL_Object_01_YawAngle 0;
BA_ "GenSigStartValue" SG_ 2331595776 NR_FL_Object_01_YawAngle 4095;
BA_ "GenSigSendType" SG_ 2331595776 NR_FL_Object_01_YawAngleSD 0;
BA_ "GenSigStartValue" SG_ 2331595776 NR_FL_Object_01_YawAngleSD 511;
BA_ "GenSigSendType" SG_ 2331595776 NR_FL_Object_01_YawRateAbs 0;
BA_ "GenSigStartValue" SG_ 2331595776 NR_FL_Object_01_YawRateAbs 4095;
BA_ "GenSigSendType" SG_ 2331595776 NR_FL_Object_01_YawRateAbsSD 0;
BA_ "GenSigStartValue" SG_ 2331595776 NR_FL_Object_01_YawRateAbsSD 63;
BA_ "GenSigSendType" SG_ 2331595776 NR_FL_Object_02_aAbsX 0;
BA_ "GenSigStartValue" SG_ 2331595776 NR_FL_Object_02_aAbsX 511;
BA_ "GenSigSendType" SG_ 2331595776 NR_FL_Object_02_aAbsXSD 0;
BA_ "GenSigStartValue" SG_ 2331595776 NR_FL_Object_02_aAbsXSD 63;
BA_ "GenSigSendType" SG_ 2331595776 NR_FL_Object_02_aAbsY 0;
BA_ "GenSigStartValue" SG_ 2331595776 NR_FL_Object_02_aAbsY 511;
BA_ "GenSigSendType" SG_ 2331595776 NR_FL_Object_02_aAbsYSD 0;
BA_ "GenSigStartValue" SG_ 2331595776 NR_FL_Object_02_aAbsYSD 63;
BA_ "GenSigSendType" SG_ 2331595776 NR_FL_Object_02_Age 0;
BA_ "GenSigStartValue" SG_ 2331595776 NR_FL_Object_02_Age 127;
BA_ "GenSigSendType" SG_ 2331595776 NR_FL_Object_02_Class 0;
BA_ "GenSigStartValue" SG_ 2331595776 NR_FL_Object_02_Class 15;
BA_ "GenSigSendType" SG_ 2331595776 NR_FL_Object_02_ClassPlausib 0;
BA_ "GenSigStartValue" SG_ 2331595776 NR_FL_Object_02_ClassPlausib 15;
BA_ "GenSigSendType" SG_ 2331595776 NR_FL_Object_02_DynamicState 0;
BA_ "GenSigStartValue" SG_ 2331595776 NR_FL_Object_02_DynamicState 3;
BA_ "GenSigSendType" SG_ 2331595776 NR_FL_Object_02_ExistProb 0;
BA_ "GenSigStartValue" SG_ 2331595776 NR_FL_Object_02_ExistProb 127;
BA_ "GenSigSendType" SG_ 2331595776 NR_FL_Object_02_ID 0;
BA_ "GenSigStartValue" SG_ 2331595776 NR_FL_Object_02_ID 255;
BA_ "GenSigSendType" SG_ 2331595776 NR_FL_Object_02_Length 0;
BA_ "GenSigStartValue" SG_ 2331595776 NR_FL_Object_02_Length 1023;
BA_ "GenSigSendType" SG_ 2331595776 NR_FL_Object_02_LengthSD 0;
BA_ "GenSigStartValue" SG_ 2331595776 NR_FL_Object_02_LengthSD 127;
BA_ "GenSigSendType" SG_ 2331595776 NR_FL_Object_02_MeasurementState 0;
BA_ "GenSigSendType" SG_ 2331595776 NR_FL_Object_02_PosX 0;
BA_ "GenSigStartValue" SG_ 2331595776 NR_FL_Object_02_PosX 16383;
BA_ "GenSigSendType" SG_ 2331595776 NR_FL_Object_02_PosXSD 0;
BA_ "GenSigStartValue" SG_ 2331595776 NR_FL_Object_02_PosXSD 255;
BA_ "GenSigSendType" SG_ 2331595776 NR_FL_Object_02_PosY 0;
BA_ "GenSigStartValue" SG_ 2331595776 NR_FL_Object_02_PosY 8191;
BA_ "GenSigSendType" SG_ 2331595776 NR_FL_Object_02_PosYSD 0;
BA_ "GenSigStartValue" SG_ 2331595776 NR_FL_Object_02_PosYSD 255;
BA_ "GenSigSendType" SG_ 2331595776 NR_FL_Object_02_ReferencePoint 0;
BA_ "GenSigStartValue" SG_ 2331595776 NR_FL_Object_02_ReferencePoint 15;
BA_ "GenSigSendType" SG_ 2331595776 NR_FL_Object_02_vAbsX 0;
BA_ "GenSigStartValue" SG_ 2331595776 NR_FL_Object_02_vAbsX 4095;
BA_ "GenSigSendType" SG_ 2331595776 NR_FL_Object_02_vAbsXSD 0;
BA_ "GenSigStartValue" SG_ 2331595776 NR_FL_Object_02_vAbsXSD 63;
BA_ "GenSigSendType" SG_ 2331595776 NR_FL_Object_02_vAbsY 0;
BA_ "GenSigStartValue" SG_ 2331595776 NR_FL_Object_02_vAbsY 4095;
BA_ "GenSigSendType" SG_ 2331595776 NR_FL_Object_02_vAbsYSD 0;
BA_ "GenSigStartValue" SG_ 2331595776 NR_FL_Object_02_vAbsYSD 63;
BA_ "GenSigSendType" SG_ 2331595776 NR_FL_Object_02_Width 0;
BA_ "GenSigStartValue" SG_ 2331595776 NR_FL_Object_02_Width 255;
BA_ "GenSigSendType" SG_ 2331595776 NR_FL_Object_02_WidthSD 0;
BA_ "GenSigStartValue" SG_ 2331595776 NR_FL_Object_02_WidthSD 127;
BA_ "GenSigSendType" SG_ 2331595776 NR_FL_Object_02_YawAngle 0;
BA_ "GenSigStartValue" SG_ 2331595776 NR_FL_Object_02_YawAngle 4095;
BA_ "GenSigSendType" SG_ 2331595776 NR_FL_Object_02_YawAngleSD 0;
BA_ "GenSigStartValue" SG_ 2331595776 NR_FL_Object_02_YawAngleSD 511;
BA_ "GenSigSendType" SG_ 2331595776 NR_FL_Object_02_YawRateAbs 0;
BA_ "GenSigStartValue" SG_ 2331595776 NR_FL_Object_02_YawRateAbs 4095;
BA_ "GenSigSendType" SG_ 2331595776 NR_FL_Object_02_YawRateAbsSD 0;
BA_ "GenSigStartValue" SG_ 2331595776 NR_FL_Object_02_YawRateAbsSD 63;
BA_ "GenSigSendType" SG_ 2331595776 SOK_NR_FL_Object_01_02_Signatur 0;
BA_ "GenSigFuncType" SG_ 2331595776 SOK_NR_FL_Object_01_02_Signatur 15;
BA_ "GenSigSendType" SG_ 2331595777 NR_FL_Object_03_04_BlockID_01 0;
BA_ "GenSigSendType" SG_ 2331595777 NR_FL_Object_03_04_BZ 0;
BA_ "GenSigFuncType" SG_ 2331595777 NR_FL_Object_03_04_BZ 1;
BA_ "GenSigSwitchedByIgnition" SG_ 2331595777 NR_FL_Object_03_04_BZ 0;
BA_ "GenSigSendType" SG_ 2331595777 NR_FL_Object_03_04_CRC 0;
BA_ "GenSigFuncType" SG_ 2331595777 NR_FL_Object_03_04_CRC 2;
BA_ "GenSigSwitchedByIgnition" SG_ 2331595777 NR_FL_Object_03_04_CRC 0;
BA_ "GenSigSendType" SG_ 2331595777 NR_FL_Object_03_aAbsX 0;
BA_ "GenSigStartValue" SG_ 2331595777 NR_FL_Object_03_aAbsX 511;
BA_ "GenSigSendType" SG_ 2331595777 NR_FL_Object_03_aAbsXSD 0;
BA_ "GenSigStartValue" SG_ 2331595777 NR_FL_Object_03_aAbsXSD 63;
BA_ "GenSigSendType" SG_ 2331595777 NR_FL_Object_03_aAbsY 0;
BA_ "GenSigStartValue" SG_ 2331595777 NR_FL_Object_03_aAbsY 511;
BA_ "GenSigSendType" SG_ 2331595777 NR_FL_Object_03_aAbsYSD 0;
BA_ "GenSigStartValue" SG_ 2331595777 NR_FL_Object_03_aAbsYSD 63;
BA_ "GenSigSendType" SG_ 2331595777 NR_FL_Object_03_Age 0;
BA_ "GenSigStartValue" SG_ 2331595777 NR_FL_Object_03_Age 127;
BA_ "GenSigSendType" SG_ 2331595777 NR_FL_Object_03_Class 0;
BA_ "GenSigStartValue" SG_ 2331595777 NR_FL_Object_03_Class 15;
BA_ "GenSigSendType" SG_ 2331595777 NR_FL_Object_03_ClassPlausib 0;
BA_ "GenSigStartValue" SG_ 2331595777 NR_FL_Object_03_ClassPlausib 15;
BA_ "GenSigSendType" SG_ 2331595777 NR_FL_Object_03_DynamicState 0;
BA_ "GenSigStartValue" SG_ 2331595777 NR_FL_Object_03_DynamicState 3;
BA_ "GenSigSendType" SG_ 2331595777 NR_FL_Object_03_ExistProb 0;
BA_ "GenSigStartValue" SG_ 2331595777 NR_FL_Object_03_ExistProb 127;
BA_ "GenSigSendType" SG_ 2331595777 NR_FL_Object_03_ID 0;
BA_ "GenSigStartValue" SG_ 2331595777 NR_FL_Object_03_ID 255;
BA_ "GenSigSendType" SG_ 2331595777 NR_FL_Object_03_Length 0;
BA_ "GenSigStartValue" SG_ 2331595777 NR_FL_Object_03_Length 1023;
BA_ "GenSigSendType" SG_ 2331595777 NR_FL_Object_03_LengthSD 0;
BA_ "GenSigStartValue" SG_ 2331595777 NR_FL_Object_03_LengthSD 127;
BA_ "GenSigSendType" SG_ 2331595777 NR_FL_Object_03_MeasurementState 0;
BA_ "GenSigSendType" SG_ 2331595777 NR_FL_Object_03_PosX 0;
BA_ "GenSigStartValue" SG_ 2331595777 NR_FL_Object_03_PosX 16383;
BA_ "GenSigSendType" SG_ 2331595777 NR_FL_Object_03_PosXSD 0;
BA_ "GenSigStartValue" SG_ 2331595777 NR_FL_Object_03_PosXSD 255;
BA_ "GenSigSendType" SG_ 2331595777 NR_FL_Object_03_PosY 0;
BA_ "GenSigStartValue" SG_ 2331595777 NR_FL_Object_03_PosY 8191;
BA_ "GenSigSendType" SG_ 2331595777 NR_FL_Object_03_PosYSD 0;
BA_ "GenSigStartValue" SG_ 2331595777 NR_FL_Object_03_PosYSD 255;
BA_ "GenSigSendType" SG_ 2331595777 NR_FL_Object_03_ReferencePoint 0;
BA_ "GenSigStartValue" SG_ 2331595777 NR_FL_Object_03_ReferencePoint 15;
BA_ "GenSigSendType" SG_ 2331595777 NR_FL_Object_03_vAbsX 0;
BA_ "GenSigStartValue" SG_ 2331595777 NR_FL_Object_03_vAbsX 4095;
BA_ "GenSigSendType" SG_ 2331595777 NR_FL_Object_03_vAbsXSD 0;
BA_ "GenSigStartValue" SG_ 2331595777 NR_FL_Object_03_vAbsXSD 63;
BA_ "GenSigSendType" SG_ 2331595777 NR_FL_Object_03_vAbsY 0;
BA_ "GenSigStartValue" SG_ 2331595777 NR_FL_Object_03_vAbsY 4095;
BA_ "GenSigSendType" SG_ 2331595777 NR_FL_Object_03_vAbsYSD 0;
BA_ "GenSigStartValue" SG_ 2331595777 NR_FL_Object_03_vAbsYSD 63;
BA_ "GenSigSendType" SG_ 2331595777 NR_FL_Object_03_Width 0;
BA_ "GenSigStartValue" SG_ 2331595777 NR_FL_Object_03_Width 255;
BA_ "GenSigSendType" SG_ 2331595777 NR_FL_Object_03_WidthSD 0;
BA_ "GenSigStartValue" SG_ 2331595777 NR_FL_Object_03_WidthSD 127;
BA_ "GenSigSendType" SG_ 2331595777 NR_FL_Object_03_YawAngle 0;
BA_ "GenSigStartValue" SG_ 2331595777 NR_FL_Object_03_YawAngle 4095;
BA_ "GenSigSendType" SG_ 2331595777 NR_FL_Object_03_YawAngleSD 0;
BA_ "GenSigStartValue" SG_ 2331595777 NR_FL_Object_03_YawAngleSD 511;
BA_ "GenSigSendType" SG_ 2331595777 NR_FL_Object_03_YawRateAbs 0;
BA_ "GenSigStartValue" SG_ 2331595777 NR_FL_Object_03_YawRateAbs 4095;
BA_ "GenSigSendType" SG_ 2331595777 NR_FL_Object_03_YawRateAbsSD 0;
BA_ "GenSigStartValue" SG_ 2331595777 NR_FL_Object_03_YawRateAbsSD 63;
BA_ "GenSigSendType" SG_ 2331595777 NR_FL_Object_04_aAbsX 0;
BA_ "GenSigStartValue" SG_ 2331595777 NR_FL_Object_04_aAbsX 511;
BA_ "GenSigSendType" SG_ 2331595777 NR_FL_Object_04_aAbsXSD 0;
BA_ "GenSigStartValue" SG_ 2331595777 NR_FL_Object_04_aAbsXSD 63;
BA_ "GenSigSendType" SG_ 2331595777 NR_FL_Object_04_aAbsY 0;
BA_ "GenSigStartValue" SG_ 2331595777 NR_FL_Object_04_aAbsY 511;
BA_ "GenSigSendType" SG_ 2331595777 NR_FL_Object_04_aAbsYSD 0;
BA_ "GenSigStartValue" SG_ 2331595777 NR_FL_Object_04_aAbsYSD 63;
BA_ "GenSigSendType" SG_ 2331595777 NR_FL_Object_04_Age 0;
BA_ "GenSigStartValue" SG_ 2331595777 NR_FL_Object_04_Age 127;
BA_ "GenSigSendType" SG_ 2331595777 NR_FL_Object_04_Class 0;
BA_ "GenSigStartValue" SG_ 2331595777 NR_FL_Object_04_Class 15;
BA_ "GenSigSendType" SG_ 2331595777 NR_FL_Object_04_ClassPlausib 0;
BA_ "GenSigStartValue" SG_ 2331595777 NR_FL_Object_04_ClassPlausib 15;
BA_ "GenSigSendType" SG_ 2331595777 NR_FL_Object_04_DynamicState 0;
BA_ "GenSigStartValue" SG_ 2331595777 NR_FL_Object_04_DynamicState 3;
BA_ "GenSigSendType" SG_ 2331595777 NR_FL_Object_04_ExistProb 0;
BA_ "GenSigStartValue" SG_ 2331595777 NR_FL_Object_04_ExistProb 127;
BA_ "GenSigSendType" SG_ 2331595777 NR_FL_Object_04_ID 0;
BA_ "GenSigStartValue" SG_ 2331595777 NR_FL_Object_04_ID 255;
BA_ "GenSigSendType" SG_ 2331595777 NR_FL_Object_04_Length 0;
BA_ "GenSigStartValue" SG_ 2331595777 NR_FL_Object_04_Length 1023;
BA_ "GenSigSendType" SG_ 2331595777 NR_FL_Object_04_LengthSD 0;
BA_ "GenSigStartValue" SG_ 2331595777 NR_FL_Object_04_LengthSD 127;
BA_ "GenSigSendType" SG_ 2331595777 NR_FL_Object_04_MeasurementState 0;
BA_ "GenSigSendType" SG_ 2331595777 NR_FL_Object_04_PosX 0;
BA_ "GenSigStartValue" SG_ 2331595777 NR_FL_Object_04_PosX 16383;
BA_ "GenSigSendType" SG_ 2331595777 NR_FL_Object_04_PosXSD 0;
BA_ "GenSigStartValue" SG_ 2331595777 NR_FL_Object_04_PosXSD 255;
BA_ "GenSigSendType" SG_ 2331595777 NR_FL_Object_04_PosY 0;
BA_ "GenSigStartValue" SG_ 2331595777 NR_FL_Object_04_PosY 8191;
BA_ "GenSigSendType" SG_ 2331595777 NR_FL_Object_04_PosYSD 0;
BA_ "GenSigStartValue" SG_ 2331595777 NR_FL_Object_04_PosYSD 255;
BA_ "GenSigSendType" SG_ 2331595777 NR_FL_Object_04_ReferencePoint 0;
BA_ "GenSigStartValue" SG_ 2331595777 NR_FL_Object_04_ReferencePoint 15;
BA_ "GenSigSendType" SG_ 2331595777 NR_FL_Object_04_vAbsX 0;
BA_ "GenSigStartValue" SG_ 2331595777 NR_FL_Object_04_vAbsX 4095;
BA_ "GenSigSendType" SG_ 2331595777 NR_FL_Object_04_vAbsXSD 0;
BA_ "GenSigStartValue" SG_ 2331595777 NR_FL_Object_04_vAbsXSD 63;
BA_ "GenSigSendType" SG_ 2331595777 NR_FL_Object_04_vAbsY 0;
BA_ "GenSigStartValue" SG_ 2331595777 NR_FL_Object_04_vAbsY 4095;
BA_ "GenSigSendType" SG_ 2331595777 NR_FL_Object_04_vAbsYSD 0;
BA_ "GenSigStartValue" SG_ 2331595777 NR_FL_Object_04_vAbsYSD 63;
BA_ "GenSigSendType" SG_ 2331595777 NR_FL_Object_04_Width 0;
BA_ "GenSigStartValue" SG_ 2331595777 NR_FL_Object_04_Width 255;
BA_ "GenSigSendType" SG_ 2331595777 NR_FL_Object_04_WidthSD 0;
BA_ "GenSigStartValue" SG_ 2331595777 NR_FL_Object_04_WidthSD 127;
BA_ "GenSigSendType" SG_ 2331595777 NR_FL_Object_04_YawAngle 0;
BA_ "GenSigStartValue" SG_ 2331595777 NR_FL_Object_04_YawAngle 4095;
BA_ "GenSigSendType" SG_ 2331595777 NR_FL_Object_04_YawAngleSD 0;
BA_ "GenSigStartValue" SG_ 2331595777 NR_FL_Object_04_YawAngleSD 511;
BA_ "GenSigSendType" SG_ 2331595777 NR_FL_Object_04_YawRateAbs 0;
BA_ "GenSigStartValue" SG_ 2331595777 NR_FL_Object_04_YawRateAbs 4095;
BA_ "GenSigSendType" SG_ 2331595777 NR_FL_Object_04_YawRateAbsSD 0;
BA_ "GenSigStartValue" SG_ 2331595777 NR_FL_Object_04_YawRateAbsSD 63;
BA_ "GenSigSendType" SG_ 2331595777 SOK_NR_FL_Object_03_04_Signatur 0;
BA_ "GenSigFuncType" SG_ 2331595777 SOK_NR_FL_Object_03_04_Signatur 15;
BA_ "GenSigSendType" SG_ 2331595778 NR_FL_Object_05_06_BlockID_01 0;
BA_ "GenSigSendType" SG_ 2331595778 NR_FL_Object_05_06_BZ 0;
BA_ "GenSigFuncType" SG_ 2331595778 NR_FL_Object_05_06_BZ 1;
BA_ "GenSigSwitchedByIgnition" SG_ 2331595778 NR_FL_Object_05_06_BZ 0;
BA_ "GenSigSendType" SG_ 2331595778 NR_FL_Object_05_06_CRC 0;
BA_ "GenSigFuncType" SG_ 2331595778 NR_FL_Object_05_06_CRC 2;
BA_ "GenSigSwitchedByIgnition" SG_ 2331595778 NR_FL_Object_05_06_CRC 0;
BA_ "GenSigSendType" SG_ 2331595778 NR_FL_Object_05_aAbsX 0;
BA_ "GenSigStartValue" SG_ 2331595778 NR_FL_Object_05_aAbsX 511;
BA_ "GenSigSendType" SG_ 2331595778 NR_FL_Object_05_aAbsXSD 0;
BA_ "GenSigStartValue" SG_ 2331595778 NR_FL_Object_05_aAbsXSD 63;
BA_ "GenSigSendType" SG_ 2331595778 NR_FL_Object_05_aAbsY 0;
BA_ "GenSigStartValue" SG_ 2331595778 NR_FL_Object_05_aAbsY 511;
BA_ "GenSigSendType" SG_ 2331595778 NR_FL_Object_05_aAbsYSD 0;
BA_ "GenSigStartValue" SG_ 2331595778 NR_FL_Object_05_aAbsYSD 63;
BA_ "GenSigSendType" SG_ 2331595778 NR_FL_Object_05_Age 0;
BA_ "GenSigStartValue" SG_ 2331595778 NR_FL_Object_05_Age 127;
BA_ "GenSigSendType" SG_ 2331595778 NR_FL_Object_05_Class 0;
BA_ "GenSigStartValue" SG_ 2331595778 NR_FL_Object_05_Class 15;
BA_ "GenSigSendType" SG_ 2331595778 NR_FL_Object_05_ClassPlausib 0;
BA_ "GenSigStartValue" SG_ 2331595778 NR_FL_Object_05_ClassPlausib 15;
BA_ "GenSigSendType" SG_ 2331595778 NR_FL_Object_05_DynamicState 0;
BA_ "GenSigStartValue" SG_ 2331595778 NR_FL_Object_05_DynamicState 3;
BA_ "GenSigSendType" SG_ 2331595778 NR_FL_Object_05_ExistProb 0;
BA_ "GenSigStartValue" SG_ 2331595778 NR_FL_Object_05_ExistProb 127;
BA_ "GenSigSendType" SG_ 2331595778 NR_FL_Object_05_ID 0;
BA_ "GenSigStartValue" SG_ 2331595778 NR_FL_Object_05_ID 255;
BA_ "GenSigSendType" SG_ 2331595778 NR_FL_Object_05_Length 0;
BA_ "GenSigStartValue" SG_ 2331595778 NR_FL_Object_05_Length 1023;
BA_ "GenSigSendType" SG_ 2331595778 NR_FL_Object_05_LengthSD 0;
BA_ "GenSigStartValue" SG_ 2331595778 NR_FL_Object_05_LengthSD 127;
BA_ "GenSigSendType" SG_ 2331595778 NR_FL_Object_05_MeasurementState 0;
BA_ "GenSigSendType" SG_ 2331595778 NR_FL_Object_05_PosX 0;
BA_ "GenSigStartValue" SG_ 2331595778 NR_FL_Object_05_PosX 16383;
BA_ "GenSigSendType" SG_ 2331595778 NR_FL_Object_05_PosXSD 0;
BA_ "GenSigStartValue" SG_ 2331595778 NR_FL_Object_05_PosXSD 255;
BA_ "GenSigSendType" SG_ 2331595778 NR_FL_Object_05_PosY 0;
BA_ "GenSigStartValue" SG_ 2331595778 NR_FL_Object_05_PosY 8191;
BA_ "GenSigSendType" SG_ 2331595778 NR_FL_Object_05_PosYSD 0;
BA_ "GenSigStartValue" SG_ 2331595778 NR_FL_Object_05_PosYSD 255;
BA_ "GenSigSendType" SG_ 2331595778 NR_FL_Object_05_ReferencePoint 0;
BA_ "GenSigStartValue" SG_ 2331595778 NR_FL_Object_05_ReferencePoint 15;
BA_ "GenSigSendType" SG_ 2331595778 NR_FL_Object_05_vAbsX 0;
BA_ "GenSigStartValue" SG_ 2331595778 NR_FL_Object_05_vAbsX 4095;
BA_ "GenSigSendType" SG_ 2331595778 NR_FL_Object_05_vAbsXSD 0;
BA_ "GenSigStartValue" SG_ 2331595778 NR_FL_Object_05_vAbsXSD 63;
BA_ "GenSigSendType" SG_ 2331595778 NR_FL_Object_05_vAbsY 0;
BA_ "GenSigStartValue" SG_ 2331595778 NR_FL_Object_05_vAbsY 4095;
BA_ "GenSigSendType" SG_ 2331595778 NR_FL_Object_05_vAbsYSD 0;
BA_ "GenSigStartValue" SG_ 2331595778 NR_FL_Object_05_vAbsYSD 63;
BA_ "GenSigSendType" SG_ 2331595778 NR_FL_Object_05_Width 0;
BA_ "GenSigStartValue" SG_ 2331595778 NR_FL_Object_05_Width 255;
BA_ "GenSigSendType" SG_ 2331595778 NR_FL_Object_05_WidthSD 0;
BA_ "GenSigStartValue" SG_ 2331595778 NR_FL_Object_05_WidthSD 127;
BA_ "GenSigSendType" SG_ 2331595778 NR_FL_Object_05_YawAngle 0;
BA_ "GenSigStartValue" SG_ 2331595778 NR_FL_Object_05_YawAngle 4095;
BA_ "GenSigSendType" SG_ 2331595778 NR_FL_Object_05_YawAngleSD 0;
BA_ "GenSigStartValue" SG_ 2331595778 NR_FL_Object_05_YawAngleSD 511;
BA_ "GenSigSendType" SG_ 2331595778 NR_FL_Object_05_YawRateAbs 0;
BA_ "GenSigStartValue" SG_ 2331595778 NR_FL_Object_05_YawRateAbs 4095;
BA_ "GenSigSendType" SG_ 2331595778 NR_FL_Object_05_YawRateAbsSD 0;
BA_ "GenSigStartValue" SG_ 2331595778 NR_FL_Object_05_YawRateAbsSD 63;
BA_ "GenSigSendType" SG_ 2331595778 NR_FL_Object_06_aAbsX 0;
BA_ "GenSigStartValue" SG_ 2331595778 NR_FL_Object_06_aAbsX 511;
BA_ "GenSigSendType" SG_ 2331595778 NR_FL_Object_06_aAbsXSD 0;
BA_ "GenSigStartValue" SG_ 2331595778 NR_FL_Object_06_aAbsXSD 63;
BA_ "GenSigSendType" SG_ 2331595778 NR_FL_Object_06_aAbsY 0;
BA_ "GenSigStartValue" SG_ 2331595778 NR_FL_Object_06_aAbsY 511;
BA_ "GenSigSendType" SG_ 2331595778 NR_FL_Object_06_aAbsYSD 0;
BA_ "GenSigStartValue" SG_ 2331595778 NR_FL_Object_06_aAbsYSD 63;
BA_ "GenSigSendType" SG_ 2331595778 NR_FL_Object_06_Age 0;
BA_ "GenSigStartValue" SG_ 2331595778 NR_FL_Object_06_Age 127;
BA_ "GenSigSendType" SG_ 2331595778 NR_FL_Object_06_Class 0;
BA_ "GenSigStartValue" SG_ 2331595778 NR_FL_Object_06_Class 15;
BA_ "GenSigSendType" SG_ 2331595778 NR_FL_Object_06_ClassPlausib 0;
BA_ "GenSigStartValue" SG_ 2331595778 NR_FL_Object_06_ClassPlausib 15;
BA_ "GenSigSendType" SG_ 2331595778 NR_FL_Object_06_DynamicState 0;
BA_ "GenSigStartValue" SG_ 2331595778 NR_FL_Object_06_DynamicState 3;
BA_ "GenSigSendType" SG_ 2331595778 NR_FL_Object_06_ExistProb 0;
BA_ "GenSigStartValue" SG_ 2331595778 NR_FL_Object_06_ExistProb 127;
BA_ "GenSigSendType" SG_ 2331595778 NR_FL_Object_06_ID 0;
BA_ "GenSigStartValue" SG_ 2331595778 NR_FL_Object_06_ID 255;
BA_ "GenSigSendType" SG_ 2331595778 NR_FL_Object_06_Length 0;
BA_ "GenSigStartValue" SG_ 2331595778 NR_FL_Object_06_Length 1023;
BA_ "GenSigSendType" SG_ 2331595778 NR_FL_Object_06_LengthSD 0;
BA_ "GenSigStartValue" SG_ 2331595778 NR_FL_Object_06_LengthSD 127;
BA_ "GenSigSendType" SG_ 2331595778 NR_FL_Object_06_MeasurementState 0;
BA_ "GenSigSendType" SG_ 2331595778 NR_FL_Object_06_PosX 0;
BA_ "GenSigStartValue" SG_ 2331595778 NR_FL_Object_06_PosX 16383;
BA_ "GenSigSendType" SG_ 2331595778 NR_FL_Object_06_PosXSD 0;
BA_ "GenSigStartValue" SG_ 2331595778 NR_FL_Object_06_PosXSD 255;
BA_ "GenSigSendType" SG_ 2331595778 NR_FL_Object_06_PosY 0;
BA_ "GenSigStartValue" SG_ 2331595778 NR_FL_Object_06_PosY 8191;
BA_ "GenSigSendType" SG_ 2331595778 NR_FL_Object_06_PosYSD 0;
BA_ "GenSigStartValue" SG_ 2331595778 NR_FL_Object_06_PosYSD 255;
BA_ "GenSigSendType" SG_ 2331595778 NR_FL_Object_06_ReferencePoint 0;
BA_ "GenSigStartValue" SG_ 2331595778 NR_FL_Object_06_ReferencePoint 15;
BA_ "GenSigSendType" SG_ 2331595778 NR_FL_Object_06_vAbsX 0;
BA_ "GenSigStartValue" SG_ 2331595778 NR_FL_Object_06_vAbsX 4095;
BA_ "GenSigSendType" SG_ 2331595778 NR_FL_Object_06_vAbsXSD 0;
BA_ "GenSigStartValue" SG_ 2331595778 NR_FL_Object_06_vAbsXSD 63;
BA_ "GenSigSendType" SG_ 2331595778 NR_FL_Object_06_vAbsY 0;
BA_ "GenSigStartValue" SG_ 2331595778 NR_FL_Object_06_vAbsY 4095;
BA_ "GenSigSendType" SG_ 2331595778 NR_FL_Object_06_vAbsYSD 0;
BA_ "GenSigStartValue" SG_ 2331595778 NR_FL_Object_06_vAbsYSD 63;
BA_ "GenSigSendType" SG_ 2331595778 NR_FL_Object_06_Width 0;
BA_ "GenSigStartValue" SG_ 2331595778 NR_FL_Object_06_Width 255;
BA_ "GenSigSendType" SG_ 2331595778 NR_FL_Object_06_WidthSD 0;
BA_ "GenSigStartValue" SG_ 2331595778 NR_FL_Object_06_WidthSD 127;
BA_ "GenSigSendType" SG_ 2331595778 NR_FL_Object_06_YawAngle 0;
BA_ "GenSigStartValue" SG_ 2331595778 NR_FL_Object_06_YawAngle 4095;
BA_ "GenSigSendType" SG_ 2331595778 NR_FL_Object_06_YawAngleSD 0;
BA_ "GenSigStartValue" SG_ 2331595778 NR_FL_Object_06_YawAngleSD 511;
BA_ "GenSigSendType" SG_ 2331595778 NR_FL_Object_06_YawRateAbs 0;
BA_ "GenSigStartValue" SG_ 2331595778 NR_FL_Object_06_YawRateAbs 4095;
BA_ "GenSigSendType" SG_ 2331595778 NR_FL_Object_06_YawRateAbsSD 0;
BA_ "GenSigStartValue" SG_ 2331595778 NR_FL_Object_06_YawRateAbsSD 63;
BA_ "GenSigSendType" SG_ 2331595778 SOK_NR_FL_Object_05_06_Signatur 0;
BA_ "GenSigFuncType" SG_ 2331595778 SOK_NR_FL_Object_05_06_Signatur 15;
BA_ "GenSigSendType" SG_ 2331595779 NR_FL_Object_07_08_BlockID_01 0;
BA_ "GenSigSendType" SG_ 2331595779 NR_FL_Object_07_08_BZ 0;
BA_ "GenSigFuncType" SG_ 2331595779 NR_FL_Object_07_08_BZ 1;
BA_ "GenSigSwitchedByIgnition" SG_ 2331595779 NR_FL_Object_07_08_BZ 0;
BA_ "GenSigSendType" SG_ 2331595779 NR_FL_Object_07_08_CRC 0;
BA_ "GenSigFuncType" SG_ 2331595779 NR_FL_Object_07_08_CRC 2;
BA_ "GenSigSwitchedByIgnition" SG_ 2331595779 NR_FL_Object_07_08_CRC 0;
BA_ "GenSigSendType" SG_ 2331595779 NR_FL_Object_07_aAbsX 0;
BA_ "GenSigStartValue" SG_ 2331595779 NR_FL_Object_07_aAbsX 511;
BA_ "GenSigSendType" SG_ 2331595779 NR_FL_Object_07_aAbsXSD 0;
BA_ "GenSigStartValue" SG_ 2331595779 NR_FL_Object_07_aAbsXSD 63;
BA_ "GenSigSendType" SG_ 2331595779 NR_FL_Object_07_aAbsY 0;
BA_ "GenSigStartValue" SG_ 2331595779 NR_FL_Object_07_aAbsY 511;
BA_ "GenSigSendType" SG_ 2331595779 NR_FL_Object_07_aAbsYSD 0;
BA_ "GenSigStartValue" SG_ 2331595779 NR_FL_Object_07_aAbsYSD 63;
BA_ "GenSigSendType" SG_ 2331595779 NR_FL_Object_07_Age 0;
BA_ "GenSigStartValue" SG_ 2331595779 NR_FL_Object_07_Age 127;
BA_ "GenSigSendType" SG_ 2331595779 NR_FL_Object_07_Class 0;
BA_ "GenSigStartValue" SG_ 2331595779 NR_FL_Object_07_Class 15;
BA_ "GenSigSendType" SG_ 2331595779 NR_FL_Object_07_ClassPlausib 0;
BA_ "GenSigStartValue" SG_ 2331595779 NR_FL_Object_07_ClassPlausib 15;
BA_ "GenSigSendType" SG_ 2331595779 NR_FL_Object_07_DynamicState 0;
BA_ "GenSigStartValue" SG_ 2331595779 NR_FL_Object_07_DynamicState 3;
BA_ "GenSigSendType" SG_ 2331595779 NR_FL_Object_07_ExistProb 0;
BA_ "GenSigStartValue" SG_ 2331595779 NR_FL_Object_07_ExistProb 127;
BA_ "GenSigSendType" SG_ 2331595779 NR_FL_Object_07_ID 0;
BA_ "GenSigStartValue" SG_ 2331595779 NR_FL_Object_07_ID 255;
BA_ "GenSigSendType" SG_ 2331595779 NR_FL_Object_07_Length 0;
BA_ "GenSigStartValue" SG_ 2331595779 NR_FL_Object_07_Length 1023;
BA_ "GenSigSendType" SG_ 2331595779 NR_FL_Object_07_LengthSD 0;
BA_ "GenSigStartValue" SG_ 2331595779 NR_FL_Object_07_LengthSD 127;
BA_ "GenSigSendType" SG_ 2331595779 NR_FL_Object_07_MeasurementState 0;
BA_ "GenSigSendType" SG_ 2331595779 NR_FL_Object_07_PosX 0;
BA_ "GenSigStartValue" SG_ 2331595779 NR_FL_Object_07_PosX 16383;
BA_ "GenSigSendType" SG_ 2331595779 NR_FL_Object_07_PosXSD 0;
BA_ "GenSigStartValue" SG_ 2331595779 NR_FL_Object_07_PosXSD 255;
BA_ "GenSigSendType" SG_ 2331595779 NR_FL_Object_07_PosY 0;
BA_ "GenSigStartValue" SG_ 2331595779 NR_FL_Object_07_PosY 8191;
BA_ "GenSigSendType" SG_ 2331595779 NR_FL_Object_07_PosYSD 0;
BA_ "GenSigStartValue" SG_ 2331595779 NR_FL_Object_07_PosYSD 255;
BA_ "GenSigSendType" SG_ 2331595779 NR_FL_Object_07_ReferencePoint 0;
BA_ "GenSigStartValue" SG_ 2331595779 NR_FL_Object_07_ReferencePoint 15;
BA_ "GenSigSendType" SG_ 2331595779 NR_FL_Object_07_vAbsX 0;
BA_ "GenSigStartValue" SG_ 2331595779 NR_FL_Object_07_vAbsX 4095;
BA_ "GenSigSendType" SG_ 2331595779 NR_FL_Object_07_vAbsXSD 0;
BA_ "GenSigStartValue" SG_ 2331595779 NR_FL_Object_07_vAbsXSD 63;
BA_ "GenSigSendType" SG_ 2331595779 NR_FL_Object_07_vAbsY 0;
BA_ "GenSigStartValue" SG_ 2331595779 NR_FL_Object_07_vAbsY 4095;
BA_ "GenSigSendType" SG_ 2331595779 NR_FL_Object_07_vAbsYSD 0;
BA_ "GenSigStartValue" SG_ 2331595779 NR_FL_Object_07_vAbsYSD 63;
BA_ "GenSigSendType" SG_ 2331595779 NR_FL_Object_07_Width 0;
BA_ "GenSigStartValue" SG_ 2331595779 NR_FL_Object_07_Width 255;
BA_ "GenSigSendType" SG_ 2331595779 NR_FL_Object_07_WidthSD 0;
BA_ "GenSigStartValue" SG_ 2331595779 NR_FL_Object_07_WidthSD 127;
BA_ "GenSigSendType" SG_ 2331595779 NR_FL_Object_07_YawAngle 0;
BA_ "GenSigStartValue" SG_ 2331595779 NR_FL_Object_07_YawAngle 4095;
BA_ "GenSigSendType" SG_ 2331595779 NR_FL_Object_07_YawAngleSD 0;
BA_ "GenSigStartValue" SG_ 2331595779 NR_FL_Object_07_YawAngleSD 511;
BA_ "GenSigSendType" SG_ 2331595779 NR_FL_Object_07_YawRateAbs 0;
BA_ "GenSigStartValue" SG_ 2331595779 NR_FL_Object_07_YawRateAbs 4095;
BA_ "GenSigSendType" SG_ 2331595779 NR_FL_Object_07_YawRateAbsSD 0;
BA_ "GenSigStartValue" SG_ 2331595779 NR_FL_Object_07_YawRateAbsSD 63;
BA_ "GenSigSendType" SG_ 2331595779 NR_FL_Object_08_aAbsX 0;
BA_ "GenSigStartValue" SG_ 2331595779 NR_FL_Object_08_aAbsX 511;
BA_ "GenSigSendType" SG_ 2331595779 NR_FL_Object_08_aAbsXSD 0;
BA_ "GenSigStartValue" SG_ 2331595779 NR_FL_Object_08_aAbsXSD 63;
BA_ "GenSigSendType" SG_ 2331595779 NR_FL_Object_08_aAbsY 0;
BA_ "GenSigStartValue" SG_ 2331595779 NR_FL_Object_08_aAbsY 511;
BA_ "GenSigSendType" SG_ 2331595779 NR_FL_Object_08_aAbsYSD 0;
BA_ "GenSigStartValue" SG_ 2331595779 NR_FL_Object_08_aAbsYSD 63;
BA_ "GenSigSendType" SG_ 2331595779 NR_FL_Object_08_Age 0;
BA_ "GenSigStartValue" SG_ 2331595779 NR_FL_Object_08_Age 127;
BA_ "GenSigSendType" SG_ 2331595779 NR_FL_Object_08_Class 0;
BA_ "GenSigStartValue" SG_ 2331595779 NR_FL_Object_08_Class 15;
BA_ "GenSigSendType" SG_ 2331595779 NR_FL_Object_08_ClassPlausib 0;
BA_ "GenSigStartValue" SG_ 2331595779 NR_FL_Object_08_ClassPlausib 15;
BA_ "GenSigSendType" SG_ 2331595779 NR_FL_Object_08_DynamicState 0;
BA_ "GenSigStartValue" SG_ 2331595779 NR_FL_Object_08_DynamicState 3;
BA_ "GenSigSendType" SG_ 2331595779 NR_FL_Object_08_ExistProb 0;
BA_ "GenSigStartValue" SG_ 2331595779 NR_FL_Object_08_ExistProb 127;
BA_ "GenSigSendType" SG_ 2331595779 NR_FL_Object_08_ID 0;
BA_ "GenSigStartValue" SG_ 2331595779 NR_FL_Object_08_ID 255;
BA_ "GenSigSendType" SG_ 2331595779 NR_FL_Object_08_Length 0;
BA_ "GenSigStartValue" SG_ 2331595779 NR_FL_Object_08_Length 1023;
BA_ "GenSigSendType" SG_ 2331595779 NR_FL_Object_08_LengthSD 0;
BA_ "GenSigStartValue" SG_ 2331595779 NR_FL_Object_08_LengthSD 127;
BA_ "GenSigSendType" SG_ 2331595779 NR_FL_Object_08_MeasurementState 0;
BA_ "GenSigSendType" SG_ 2331595779 NR_FL_Object_08_PosX 0;
BA_ "GenSigStartValue" SG_ 2331595779 NR_FL_Object_08_PosX 16383;
BA_ "GenSigSendType" SG_ 2331595779 NR_FL_Object_08_PosXSD 0;
BA_ "GenSigStartValue" SG_ 2331595779 NR_FL_Object_08_PosXSD 255;
BA_ "GenSigSendType" SG_ 2331595779 NR_FL_Object_08_PosY 0;
BA_ "GenSigStartValue" SG_ 2331595779 NR_FL_Object_08_PosY 8191;
BA_ "GenSigSendType" SG_ 2331595779 NR_FL_Object_08_PosYSD 0;
BA_ "GenSigStartValue" SG_ 2331595779 NR_FL_Object_08_PosYSD 255;
BA_ "GenSigSendType" SG_ 2331595779 NR_FL_Object_08_ReferencePoint 0;
BA_ "GenSigStartValue" SG_ 2331595779 NR_FL_Object_08_ReferencePoint 15;
BA_ "GenSigSendType" SG_ 2331595779 NR_FL_Object_08_vAbsX 0;
BA_ "GenSigStartValue" SG_ 2331595779 NR_FL_Object_08_vAbsX 4095;
BA_ "GenSigSendType" SG_ 2331595779 NR_FL_Object_08_vAbsXSD 0;
BA_ "GenSigStartValue" SG_ 2331595779 NR_FL_Object_08_vAbsXSD 63;
BA_ "GenSigSendType" SG_ 2331595779 NR_FL_Object_08_vAbsY 0;
BA_ "GenSigStartValue" SG_ 2331595779 NR_FL_Object_08_vAbsY 4095;
BA_ "GenSigSendType" SG_ 2331595779 NR_FL_Object_08_vAbsYSD 0;
BA_ "GenSigStartValue" SG_ 2331595779 NR_FL_Object_08_vAbsYSD 63;
BA_ "GenSigSendType" SG_ 2331595779 NR_FL_Object_08_Width 0;
BA_ "GenSigStartValue" SG_ 2331595779 NR_FL_Object_08_Width 255;
BA_ "GenSigSendType" SG_ 2331595779 NR_FL_Object_08_WidthSD 0;
BA_ "GenSigStartValue" SG_ 2331595779 NR_FL_Object_08_WidthSD 127;
BA_ "GenSigSendType" SG_ 2331595779 NR_FL_Object_08_YawAngle 0;
BA_ "GenSigStartValue" SG_ 2331595779 NR_FL_Object_08_YawAngle 4095;
BA_ "GenSigSendType" SG_ 2331595779 NR_FL_Object_08_YawAngleSD 0;
BA_ "GenSigStartValue" SG_ 2331595779 NR_FL_Object_08_YawAngleSD 511;
BA_ "GenSigSendType" SG_ 2331595779 NR_FL_Object_08_YawRateAbs 0;
BA_ "GenSigStartValue" SG_ 2331595779 NR_FL_Object_08_YawRateAbs 4095;
BA_ "GenSigSendType" SG_ 2331595779 NR_FL_Object_08_YawRateAbsSD 0;
BA_ "GenSigStartValue" SG_ 2331595779 NR_FL_Object_08_YawRateAbsSD 63;
BA_ "GenSigSendType" SG_ 2331595779 SOK_NR_FL_Object_07_08_Signatur 0;
BA_ "GenSigFuncType" SG_ 2331595779 SOK_NR_FL_Object_07_08_Signatur 15;
BA_REL_ "GenSigTimeoutTime" BU_SG_REL_ FASFrontradar SG_ 2600468496 NM_Gateway_NM_State 2000;
BA_REL_ "GenSigTimeoutTime" BU_SG_REL_ FASFrontradar SG_ 2600468559 NM_Kamera_NM_State 2000;
BA_REL_ "GenSigTimeoutTime" BU_SG_REL_ ICAS1_X_Gateway SG_ 2600468567 NM_ACC_CBV_AWB 2000;
BA_REL_ "GenSigTimeoutTime" BU_SG_REL_ ICAS1_X_Gateway SG_ 2600468567 NM_ACC_CBV_CRI 2000;
BA_REL_ "GenSigTimeoutTime" BU_SG_REL_ ICAS1_X_Gateway SG_ 2600468567 NM_ACC_Car_Wakeup 2000;
BA_REL_ "GenSigTimeoutTime" BU_SG_REL_ ICAS1_X_Gateway SG_ 2600468567 NM_ACC_CAB_V15 2000;
BA_REL_ "GenSigTimeoutTime" BU_SG_REL_ ICAS1_X_Gateway SG_ 2600468559 NM_Kamera_CBV_AWB 2000;
BA_REL_ "GenSigTimeoutTime" BU_SG_REL_ ICAS1_X_Gateway SG_ 2600468559 NM_Kamera_CBV_CRI 2000;
BA_REL_ "GenSigTimeoutTime" BU_SG_REL_ ICAS1_X_Gateway SG_ 2600468559 NM_Kamera_Car_Wakeup 2000;
BA_REL_ "GenSigTimeoutTime" BU_SG_REL_ ICAS1_X_Gateway SG_ 2600468559 NM_Kamera_CAB_V15 2000;
BA_REL_ "GenSigTimeoutTime" BU_SG_REL_ ICAS1_X_Gateway SG_ 2600468667 NM_NR_01_CBV_AWB 2000;
BA_REL_ "GenSigTimeoutTime" BU_SG_REL_ ICAS1_X_Gateway SG_ 2600468667 NM_NR_01_CBV_CRI 2000;
BA_REL_ "GenSigTimeoutTime" BU_SG_REL_ ICAS1_X_Gateway SG_ 2600468667 NM_NR_01_Car_Wakeup 2000;
BA_REL_ "GenSigTimeoutTime" BU_SG_REL_ ICAS1_X_Gateway SG_ 2600468667 NM_NR_01_CAB_V15 2000;
BA_REL_ "GenSigTimeoutTime" BU_SG_REL_ ICAS1_X_Gateway SG_ 2600468668 NM_NR_02_CBV_AWB 2000;
BA_REL_ "GenSigTimeoutTime" BU_SG_REL_ ICAS1_X_Gateway SG_ 2600468668 NM_NR_02_CBV_CRI 2000;
BA_REL_ "GenSigTimeoutTime" BU_SG_REL_ ICAS1_X_Gateway SG_ 2600468668 NM_NR_02_Car_Wakeup 2000;
BA_REL_ "GenSigTimeoutTime" BU_SG_REL_ ICAS1_X_Gateway SG_ 2600468668 NM_NR_02_CAB_V15 2000;
BA_REL_ "GenSigTimeoutTime" BU_SG_REL_ MFK SG_ 2600468567 NM_ACC_NM_State 2000;
BA_REL_ "GenSigTimeoutTime" BU_SG_REL_ MFK SG_ 2600468496 NM_Gateway_NM_State 2000;
BA_REL_ "GenSigTimeoutTime" BU_SG_REL_ MFK120 SG_ 2600468567 NM_ACC_NM_State 2000;
BA_REL_ "GenSigTimeoutTime" BU_SG_REL_ MFK120 SG_ 2600468496 NM_Gateway_NM_State 2000;
BA_REL_ "GenSigTimeoutTime" BU_SG_REL_ MFK120 SG_ 2600468667 NM_NR_01_NM_State 2000;
BA_REL_ "GenSigTimeoutTime" BU_SG_REL_ MFK120 SG_ 2600468668 NM_NR_02_NM_State 2000;
BA_REL_ "GenSigTimeoutTime" BU_SG_REL_ MIK SG_ 2600468567 NM_ACC_NM_State 2000;
BA_REL_ "GenSigTimeoutTime" BU_SG_REL_ MIK SG_ 2600468496 NM_Gateway_NM_State 2000;
BA_REL_ "GenSigTimeoutTime" BU_SG_REL_ MIK SG_ 2600468559 NM_Kamera_NM_State 2000;
BA_REL_ "GenSigTimeoutTime" BU_SG_REL_ MIK SG_ 2600468667 NM_NR_01_NM_State 2000;
BA_REL_ "GenSigTimeoutTime" BU_SG_REL_ MIK SG_ 2600468668 NM_NR_02_NM_State 2000;
BA_REL_ "GenSigTimeoutTime" BU_SG_REL_ MRR2023 SG_ 2600468496 NM_Gateway_NM_State 2000;
BA_REL_ "GenSigTimeoutTime" BU_SG_REL_ MRR2023 SG_ 2600468559 NM_Kamera_NM_State 2000;
BA_REL_ "GenSigTimeoutTime" BU_SG_REL_ MRR2023 SG_ 2600468667 NM_NR_01_NM_State 2000;
BA_REL_ "GenSigTimeoutTime" BU_SG_REL_ MRR2023 SG_ 2600468668 NM_NR_02_NM_State 2000;
BA_REL_ "GenSigTimeoutTime" BU_SG_REL_ MRR2023 SG_ 2331595825 NR_FL_ShortTrackCal_State 500;
BA_REL_ "GenSigTimeoutTime" BU_SG_REL_ MRR2023 SG_ 2331595825 NR_FL_Cal_resp 500;
BA_REL_ "GenSigTimeoutTime" BU_SG_REL_ MRR2023 SG_ 2331595825 NR_FL_CalibrationMode 500;
BA_REL_ "GenSigTimeoutTime" BU_SG_REL_ MRR2023 SG_ 2331595825 NR_FL_resp_val 500;
BA_REL_ "GenSigTimeoutTime" BU_SG_REL_ MRR2023 SG_ 2331595825 NR_FL_QualFactorAutoCalib 500;
BA_REL_ "GenSigTimeoutTime" BU_SG_REL_ MRR2023 SG_ 2331595790 NR_FL_Contour_CRC 500;
BA_REL_ "GenSigTimeoutTime" BU_SG_REL_ MRR2023 SG_ 2331595790 NR_FL_Contour_BZ 500;
BA_REL_ "GenSigTimeoutTime" BU_SG_REL_ MRR2023 SG_ 2331595790 NR_FL_Contour_BlockID_01 500;
BA_REL_ "GenSigTimeoutTime" BU_SG_REL_ MRR2023 SG_ 2331595790 NR_FL_Contour_left_01_x01 500;
BA_REL_ "GenSigTimeoutTime" BU_SG_REL_ MRR2023 SG_ 2331595790 NR_FL_Contour_left_01_y01 500;
BA_REL_ "GenSigTimeoutTime" BU_SG_REL_ MRR2023 SG_ 2331595790 NR_FL_Contour_left_01_x02 500;
BA_REL_ "GenSigTimeoutTime" BU_SG_REL_ MRR2023 SG_ 2331595790 NR_FL_Contour_left_01_y02 500;
BA_REL_ "GenSigTimeoutTime" BU_SG_REL_ MRR2023 SG_ 2331595790 NR_FL_Contour_left_01_x03 500;
BA_REL_ "GenSigTimeoutTime" BU_SG_REL_ MRR2023 SG_ 2331595790 NR_FL_Contour_left_01_y03 500;
BA_REL_ "GenSigTimeoutTime" BU_SG_REL_ MRR2023 SG_ 2331595790 NR_FL_Contour_left_01_x04 500;
BA_REL_ "GenSigTimeoutTime" BU_SG_REL_ MRR2023 SG_ 2331595790 NR_FL_Contour_left_01_y04 500;
BA_REL_ "GenSigTimeoutTime" BU_SG_REL_ MRR2023 SG_ 2331595790 NR_FL_Contour_left_01_x05 500;
BA_REL_ "GenSigTimeoutTime" BU_SG_REL_ MRR2023 SG_ 2331595790 NR_FL_Contour_left_01_y05 500;
BA_REL_ "GenSigTimeoutTime" BU_SG_REL_ MRR2023 SG_ 2331595790 NR_FL_Contour_left_01_x06 500;
BA_REL_ "GenSigTimeoutTime" BU_SG_REL_ MRR2023 SG_ 2331595790 NR_FL_Contour_left_01_y06 500;
BA_REL_ "GenSigTimeoutTime" BU_SG_REL_ MRR2023 SG_ 2331595790 NR_FL_Contour_left_01_x07 500;
BA_REL_ "GenSigTimeoutTime" BU_SG_REL_ MRR2023 SG_ 2331595790 NR_FL_Contour_left_01_y07 500;
BA_REL_ "GenSigTimeoutTime" BU_SG_REL_ MRR2023 SG_ 2331595790 NR_FL_Contour_left_01_Type 500;
BA_REL_ "GenSigTimeoutTime" BU_SG_REL_ MRR2023 SG_ 2331595790 NR_FL_Contour_left_01_Age 500;
BA_REL_ "GenSigTimeoutTime" BU_SG_REL_ MRR2023 SG_ 2331595790 NR_FL_Contour_left_02_x01 500;
BA_REL_ "GenSigTimeoutTime" BU_SG_REL_ MRR2023 SG_ 2331595790 NR_FL_Contour_left_02_y01 500;
BA_REL_ "GenSigTimeoutTime" BU_SG_REL_ MRR2023 SG_ 2331595790 NR_FL_Contour_left_02_x02 500;
BA_REL_ "GenSigTimeoutTime" BU_SG_REL_ MRR2023 SG_ 2331595790 NR_FL_Contour_left_02_y02 500;
BA_REL_ "GenSigTimeoutTime" BU_SG_REL_ MRR2023 SG_ 2331595790 NR_FL_Contour_left_02_x03 500;
BA_REL_ "GenSigTimeoutTime" BU_SG_REL_ MRR2023 SG_ 2331595790 NR_FL_Contour_left_02_y03 500;
BA_REL_ "GenSigTimeoutTime" BU_SG_REL_ MRR2023 SG_ 2331595790 NR_FL_Contour_left_02_x04 500;
BA_REL_ "GenSigTimeoutTime" BU_SG_REL_ MRR2023 SG_ 2331595790 NR_FL_Contour_left_02_y04 500;
BA_REL_ "GenSigTimeoutTime" BU_SG_REL_ MRR2023 SG_ 2331595790 NR_FL_Contour_left_02_x05 500;
BA_REL_ "GenSigTimeoutTime" BU_SG_REL_ MRR2023 SG_ 2331595790 NR_FL_Contour_left_02_y05 500;
BA_REL_ "GenSigTimeoutTime" BU_SG_REL_ MRR2023 SG_ 2331595790 NR_FL_Contour_left_02_x06 500;
BA_REL_ "GenSigTimeoutTime" BU_SG_REL_ MRR2023 SG_ 2331595790 NR_FL_Contour_left_02_y06 500;
BA_REL_ "GenSigTimeoutTime" BU_SG_REL_ MRR2023 SG_ 2331595790 NR_FL_Contour_left_02_x07 500;
BA_REL_ "GenSigTimeoutTime" BU_SG_REL_ MRR2023 SG_ 2331595790 NR_FL_Contour_left_02_y07 500;
BA_REL_ "GenSigTimeoutTime" BU_SG_REL_ MRR2023 SG_ 2331595790 NR_FL_Contour_left_02_Type 500;
BA_REL_ "GenSigTimeoutTime" BU_SG_REL_ MRR2023 SG_ 2331595790 NR_FL_Contour_left_02_Age 500;
BA_REL_ "GenSigTimeoutTime" BU_SG_REL_ MRR2023 SG_ 2331595790 NR_FL_Contour_left_Linkage 500;
BA_REL_ "GenSigTimeoutTime" BU_SG_REL_ MRR2023 SG_ 2331595781 NR_FL_Header_CRC 500;
BA_REL_ "GenSigTimeoutTime" BU_SG_REL_ MRR2023 SG_ 2331595781 NR_FL_Header_BZ 500;
BA_REL_ "GenSigTimeoutTime" BU_SG_REL_ MRR2023 SG_ 2331595781 NR_FL_BlockID_01 500;
BA_REL_ "GenSigTimeoutTime" BU_SG_REL_ MRR2023 SG_ 2331595781 NR_FL_NotAvailable 500;
BA_REL_ "GenSigTimeoutTime" BU_SG_REL_ MRR2023 SG_ 2331595781 NR_FL_Failure 500;
BA_REL_ "GenSigTimeoutTime" BU_SG_REL_ MRR2023 SG_ 2331595781 NR_FL_Blindness 500;
BA_REL_ "GenSigTimeoutTime" BU_SG_REL_ MRR2023 SG_ 2331595781 NR_FL_CalibrationState 500;
BA_REL_ "GenSigTimeoutTime" BU_SG_REL_ MRR2023 SG_ 2331595781 NR_FL_Freesight_NOK 500;
BA_REL_ "GenSigTimeoutTime" BU_SG_REL_ MRR2023 SG_ 2331595781 NR_FL_MeasurementTimeLow 500;
BA_REL_ "GenSigTimeoutTime" BU_SG_REL_ MRR2023 SG_ 2331595781 NR_FL_MeasurementTimeHigh 500;
BA_REL_ "GenSigTimeoutTime" BU_SG_REL_ MRR2023 SG_ 2331595781 NR_FL_RangeDegradation_Sect1 500;
BA_REL_ "GenSigTimeoutTime" BU_SG_REL_ MRR2023 SG_ 2331595781 NR_FL_RangeDegradation_Sect2 500;
BA_REL_ "GenSigTimeoutTime" BU_SG_REL_ MRR2023 SG_ 2331595781 NR_FL_RangeDegradation_Sect3 500;
BA_REL_ "GenSigTimeoutTime" BU_SG_REL_ MRR2023 SG_ 2331595781 NR_FL_MeasurementTimeLapNumber 500;
BA_REL_ "GenSigTimeoutTime" BU_SG_REL_ MRR2023 SG_ 2331595781 NR_FL_MeasurementTimeStatus 500;
BA_REL_ "GenSigTimeoutTime" BU_SG_REL_ MRR2023 SG_ 2331595776 NR_FL_Object_01_02_CRC 500;
BA_REL_ "GenSigTimeoutTime" BU_SG_REL_ MRR2023 SG_ 2331595776 NR_FL_Object_01_02_BZ 500;
BA_REL_ "GenSigTimeoutTime" BU_SG_REL_ MRR2023 SG_ 2331595776 NR_FL_Object_01_02_BlockID_01 500;
BA_REL_ "GenSigTimeoutTime" BU_SG_REL_ MRR2023 SG_ 2331595776 NR_FL_Object_01_ID 500;
BA_REL_ "GenSigTimeoutTime" BU_SG_REL_ MRR2023 SG_ 2331595776 NR_FL_Object_01_ReferencePoint 500;
BA_REL_ "GenSigTimeoutTime" BU_SG_REL_ MRR2023 SG_ 2331595776 NR_FL_Object_01_PosX 500;
BA_REL_ "GenSigTimeoutTime" BU_SG_REL_ MRR2023 SG_ 2331595776 NR_FL_Object_01_PosXSD 500;
BA_REL_ "GenSigTimeoutTime" BU_SG_REL_ MRR2023 SG_ 2331595776 NR_FL_Object_01_PosY 500;
BA_REL_ "GenSigTimeoutTime" BU_SG_REL_ MRR2023 SG_ 2331595776 NR_FL_Object_01_PosYSD 500;
BA_REL_ "GenSigTimeoutTime" BU_SG_REL_ MRR2023 SG_ 2331595776 NR_FL_Object_01_vAbsX 500;
BA_REL_ "GenSigTimeoutTime" BU_SG_REL_ MRR2023 SG_ 2331595776 NR_FL_Object_01_vAbsXSD 500;
BA_REL_ "GenSigTimeoutTime" BU_SG_REL_ MRR2023 SG_ 2331595776 NR_FL_Object_01_vAbsY 500;
BA_REL_ "GenSigTimeoutTime" BU_SG_REL_ MRR2023 SG_ 2331595776 NR_FL_Object_01_vAbsYSD 500;
BA_REL_ "GenSigTimeoutTime" BU_SG_REL_ MRR2023 SG_ 2331595776 NR_FL_Object_01_aAbsX 500;
BA_REL_ "GenSigTimeoutTime" BU_SG_REL_ MRR2023 SG_ 2331595776 NR_FL_Object_01_aAbsXSD 500;
BA_REL_ "GenSigTimeoutTime" BU_SG_REL_ MRR2023 SG_ 2331595776 NR_FL_Object_01_aAbsY 500;
BA_REL_ "GenSigTimeoutTime" BU_SG_REL_ MRR2023 SG_ 2331595776 NR_FL_Object_01_aAbsYSD 500;
BA_REL_ "GenSigTimeoutTime" BU_SG_REL_ MRR2023 SG_ 2331595776 NR_FL_Object_01_DynamicState 500;
BA_REL_ "GenSigTimeoutTime" BU_SG_REL_ MRR2023 SG_ 2331595776 NR_FL_Object_01_YawAngle 500;
BA_REL_ "GenSigTimeoutTime" BU_SG_REL_ MRR2023 SG_ 2331595776 NR_FL_Object_01_YawAngleSD 500;
BA_REL_ "GenSigTimeoutTime" BU_SG_REL_ MRR2023 SG_ 2331595776 NR_FL_Object_01_Width 500;
BA_REL_ "GenSigTimeoutTime" BU_SG_REL_ MRR2023 SG_ 2331595776 NR_FL_Object_01_WidthSD 500;
BA_REL_ "GenSigTimeoutTime" BU_SG_REL_ MRR2023 SG_ 2331595776 NR_FL_Object_01_Length 500;
BA_REL_ "GenSigTimeoutTime" BU_SG_REL_ MRR2023 SG_ 2331595776 NR_FL_Object_01_LengthSD 500;
BA_REL_ "GenSigTimeoutTime" BU_SG_REL_ MRR2023 SG_ 2331595776 NR_FL_Object_01_Class 500;
BA_REL_ "GenSigTimeoutTime" BU_SG_REL_ MRR2023 SG_ 2331595776 NR_FL_Object_01_ClassPlausib 500;
BA_REL_ "GenSigTimeoutTime" BU_SG_REL_ MRR2023 SG_ 2331595776 NR_FL_Object_01_ExistProb 500;
BA_REL_ "GenSigTimeoutTime" BU_SG_REL_ MRR2023 SG_ 2331595776 NR_FL_Object_01_Age 500;
BA_REL_ "GenSigTimeoutTime" BU_SG_REL_ MRR2023 SG_ 2331595776 NR_FL_Object_01_YawRateAbs 500;
BA_REL_ "GenSigTimeoutTime" BU_SG_REL_ MRR2023 SG_ 2331595776 NR_FL_Object_01_YawRateAbsSD 500;
BA_REL_ "GenSigTimeoutTime" BU_SG_REL_ MRR2023 SG_ 2331595776 NR_FL_Object_01_MeasurementState 500;
BA_REL_ "GenSigTimeoutTime" BU_SG_REL_ MRR2023 SG_ 2331595776 NR_FL_Object_02_ID 500;
BA_REL_ "GenSigTimeoutTime" BU_SG_REL_ MRR2023 SG_ 2331595776 NR_FL_Object_02_ReferencePoint 500;
BA_REL_ "GenSigTimeoutTime" BU_SG_REL_ MRR2023 SG_ 2331595776 NR_FL_Object_02_PosX 500;
BA_REL_ "GenSigTimeoutTime" BU_SG_REL_ MRR2023 SG_ 2331595776 NR_FL_Object_02_PosXSD 500;
BA_REL_ "GenSigTimeoutTime" BU_SG_REL_ MRR2023 SG_ 2331595776 NR_FL_Object_02_PosY 500;
BA_REL_ "GenSigTimeoutTime" BU_SG_REL_ MRR2023 SG_ 2331595776 NR_FL_Object_02_PosYSD 500;
BA_REL_ "GenSigTimeoutTime" BU_SG_REL_ MRR2023 SG_ 2331595776 NR_FL_Object_02_vAbsX 500;
BA_REL_ "GenSigTimeoutTime" BU_SG_REL_ MRR2023 SG_ 2331595776 NR_FL_Object_02_vAbsXSD 500;
BA_REL_ "GenSigTimeoutTime" BU_SG_REL_ MRR2023 SG_ 2331595776 NR_FL_Object_02_vAbsY 500;
BA_REL_ "GenSigTimeoutTime" BU_SG_REL_ MRR2023 SG_ 2331595776 NR_FL_Object_02_vAbsYSD 500;
BA_REL_ "GenSigTimeoutTime" BU_SG_REL_ MRR2023 SG_ 2331595776 NR_FL_Object_02_aAbsX 500;
BA_REL_ "GenSigTimeoutTime" BU_SG_REL_ MRR2023 SG_ 2331595776 NR_FL_Object_02_aAbsXSD 500;
BA_REL_ "GenSigTimeoutTime" BU_SG_REL_ MRR2023 SG_ 2331595776 NR_FL_Object_02_aAbsY 500;
BA_REL_ "GenSigTimeoutTime" BU_SG_REL_ MRR2023 SG_ 2331595776 NR_FL_Object_02_aAbsYSD 500;
BA_REL_ "GenSigTimeoutTime" BU_SG_REL_ MRR2023 SG_ 2331595776 NR_FL_Object_02_DynamicState 500;
BA_REL_ "GenSigTimeoutTime" BU_SG_REL_ MRR2023 SG_ 2331595776 NR_FL_Object_02_YawAngle 500;
BA_REL_ "GenSigTimeoutTime" BU_SG_REL_ MRR2023 SG_ 2331595776 NR_FL_Object_02_YawAngleSD 500;
BA_REL_ "GenSigTimeoutTime" BU_SG_REL_ MRR2023 SG_ 2331595776 NR_FL_Object_02_Width 500;
BA_REL_ "GenSigTimeoutTime" BU_SG_REL_ MRR2023 SG_ 2331595776 NR_FL_Object_02_WidthSD 500;
BA_REL_ "GenSigTimeoutTime" BU_SG_REL_ MRR2023 SG_ 2331595776 NR_FL_Object_02_Length 500;
BA_REL_ "GenSigTimeoutTime" BU_SG_REL_ MRR2023 SG_ 2331595776 NR_FL_Object_02_LengthSD 500;
BA_REL_ "GenSigTimeoutTime" BU_SG_REL_ MRR2023 SG_ 2331595776 NR_FL_Object_02_Class 500;
BA_REL_ "GenSigTimeoutTime" BU_SG_REL_ MRR2023 SG_ 2331595776 NR_FL_Object_02_ClassPlausib 500;
BA_REL_ "GenSigTimeoutTime" BU_SG_REL_ MRR2023 SG_ 2331595776 NR_FL_Object_02_ExistProb 500;
BA_REL_ "GenSigTimeoutTime" BU_SG_REL_ MRR2023 SG_ 2331595776 NR_FL_Object_02_Age 500;
BA_REL_ "GenSigTimeoutTime" BU_SG_REL_ MRR2023 SG_ 2331595776 NR_FL_Object_02_YawRateAbs 500;
BA_REL_ "GenSigTimeoutTime" BU_SG_REL_ MRR2023 SG_ 2331595776 NR_FL_Object_02_YawRateAbsSD 500;
BA_REL_ "GenSigTimeoutTime" BU_SG_REL_ MRR2023 SG_ 2331595776 NR_FL_Object_02_MeasurementState 500;
BA_REL_ "GenSigTimeoutTime" BU_SG_REL_ MRR2023 SG_ 2331595777 NR_FL_Object_03_04_CRC 500;
BA_REL_ "GenSigTimeoutTime" BU_SG_REL_ MRR2023 SG_ 2331595777 NR_FL_Object_03_04_BZ 500;
BA_REL_ "GenSigTimeoutTime" BU_SG_REL_ MRR2023 SG_ 2331595777 NR_FL_Object_03_04_BlockID_01 500;
BA_REL_ "GenSigTimeoutTime" BU_SG_REL_ MRR2023 SG_ 2331595777 NR_FL_Object_03_ID 500;
BA_REL_ "GenSigTimeoutTime" BU_SG_REL_ MRR2023 SG_ 2331595777 NR_FL_Object_03_ReferencePoint 500;
BA_REL_ "GenSigTimeoutTime" BU_SG_REL_ MRR2023 SG_ 2331595777 NR_FL_Object_03_PosX 500;
BA_REL_ "GenSigTimeoutTime" BU_SG_REL_ MRR2023 SG_ 2331595777 NR_FL_Object_03_PosXSD 500;
BA_REL_ "GenSigTimeoutTime" BU_SG_REL_ MRR2023 SG_ 2331595777 NR_FL_Object_03_PosY 500;
BA_REL_ "GenSigTimeoutTime" BU_SG_REL_ MRR2023 SG_ 2331595777 NR_FL_Object_03_PosYSD 500;
BA_REL_ "GenSigTimeoutTime" BU_SG_REL_ MRR2023 SG_ 2331595777 NR_FL_Object_03_vAbsX 500;
BA_REL_ "GenSigTimeoutTime" BU_SG_REL_ MRR2023 SG_ 2331595777 NR_FL_Object_03_vAbsXSD 500;
BA_REL_ "GenSigTimeoutTime" BU_SG_REL_ MRR2023 SG_ 2331595777 NR_FL_Object_03_vAbsY 500;
BA_REL_ "GenSigTimeoutTime" BU_SG_REL_ MRR2023 SG_ 2331595777 NR_FL_Object_03_vAbsYSD 500;
BA_REL_ "GenSigTimeoutTime" BU_SG_REL_ MRR2023 SG_ 2331595777 NR_FL_Object_03_aAbsX 500;
BA_REL_ "GenSigTimeoutTime" BU_SG_REL_ MRR2023 SG_ 2331595777 NR_FL_Object_03_aAbsXSD 500;
BA_REL_ "GenSigTimeoutTime" BU_SG_REL_ MRR2023 SG_ 2331595777 NR_FL_Object_03_aAbsY 500;
BA_REL_ "GenSigTimeoutTime" BU_SG_REL_ MRR2023 SG_ 2331595777 NR_FL_Object_03_aAbsYSD 500;
BA_REL_ "GenSigTimeoutTime" BU_SG_REL_ MRR2023 SG_ 2331595777 NR_FL_Object_03_DynamicState 500;
BA_REL_ "GenSigTimeoutTime" BU_SG_REL_ MRR2023 SG_ 2331595777 NR_FL_Object_03_YawAngle 500;
BA_REL_ "GenSigTimeoutTime" BU_SG_REL_ MRR2023 SG_ 2331595777 NR_FL_Object_03_YawAngleSD 500;
BA_REL_ "GenSigTimeoutTime" BU_SG_REL_ MRR2023 SG_ 2331595777 NR_FL_Object_03_Width 500;
BA_REL_ "GenSigTimeoutTime" BU_SG_REL_ MRR2023 SG_ 2331595777 NR_FL_Object_03_WidthSD 500;
BA_REL_ "GenSigTimeoutTime" BU_SG_REL_ MRR2023 SG_ 2331595777 NR_FL_Object_03_Length 500;
BA_REL_ "GenSigTimeoutTime" BU_SG_REL_ MRR2023 SG_ 2331595777 NR_FL_Object_03_LengthSD 500;
BA_REL_ "GenSigTimeoutTime" BU_SG_REL_ MRR2023 SG_ 2331595777 NR_FL_Object_03_Class 500;
BA_REL_ "GenSigTimeoutTime" BU_SG_REL_ MRR2023 SG_ 2331595777 NR_FL_Object_03_ClassPlausib 500;
BA_REL_ "GenSigTimeoutTime" BU_SG_REL_ MRR2023 SG_ 2331595777 NR_FL_Object_03_ExistProb 500;
BA_REL_ "GenSigTimeoutTime" BU_SG_REL_ MRR2023 SG_ 2331595777 NR_FL_Object_03_Age 500;
BA_REL_ "GenSigTimeoutTime" BU_SG_REL_ MRR2023 SG_ 2331595777 NR_FL_Object_03_YawRateAbs 500;
BA_REL_ "GenSigTimeoutTime" BU_SG_REL_ MRR2023 SG_ 2331595777 NR_FL_Object_03_YawRateAbsSD 500;
BA_REL_ "GenSigTimeoutTime" BU_SG_REL_ MRR2023 SG_ 2331595777 NR_FL_Object_03_MeasurementState 500;
BA_REL_ "GenSigTimeoutTime" BU_SG_REL_ MRR2023 SG_ 2331595777 NR_FL_Object_04_ID 500;
BA_REL_ "GenSigTimeoutTime" BU_SG_REL_ MRR2023 SG_ 2331595777 NR_FL_Object_04_ReferencePoint 500;
BA_REL_ "GenSigTimeoutTime" BU_SG_REL_ MRR2023 SG_ 2331595777 NR_FL_Object_04_PosX 500;
BA_REL_ "GenSigTimeoutTime" BU_SG_REL_ MRR2023 SG_ 2331595777 NR_FL_Object_04_PosXSD 500;
BA_REL_ "GenSigTimeoutTime" BU_SG_REL_ MRR2023 SG_ 2331595777 NR_FL_Object_04_PosY 500;
BA_REL_ "GenSigTimeoutTime" BU_SG_REL_ MRR2023 SG_ 2331595777 NR_FL_Object_04_PosYSD 500;
BA_REL_ "GenSigTimeoutTime" BU_SG_REL_ MRR2023 SG_ 2331595777 NR_FL_Object_04_vAbsX 500;
BA_REL_ "GenSigTimeoutTime" BU_SG_REL_ MRR2023 SG_ 2331595777 NR_FL_Object_04_vAbsXSD 500;
BA_REL_ "GenSigTimeoutTime" BU_SG_REL_ MRR2023 SG_ 2331595777 NR_FL_Object_04_vAbsY 500;
BA_REL_ "GenSigTimeoutTime" BU_SG_REL_ MRR2023 SG_ 2331595777 NR_FL_Object_04_vAbsYSD 500;
BA_REL_ "GenSigTimeoutTime" BU_SG_REL_ MRR2023 SG_ 2331595777 NR_FL_Object_04_aAbsX 500;
BA_REL_ "GenSigTimeoutTime" BU_SG_REL_ MRR2023 SG_ 2331595777 NR_FL_Object_04_aAbsXSD 500;
BA_REL_ "GenSigTimeoutTime" BU_SG_REL_ MRR2023 SG_ 2331595777 NR_FL_Object_04_aAbsY 500;
BA_REL_ "GenSigTimeoutTime" BU_SG_REL_ MRR2023 SG_ 2331595777 NR_FL_Object_04_aAbsYSD 500;
BA_REL_ "GenSigTimeoutTime" BU_SG_REL_ MRR2023 SG_ 2331595777 NR_FL_Object_04_DynamicState 500;
BA_REL_ "GenSigTimeoutTime" BU_SG_REL_ MRR2023 SG_ 2331595777 NR_FL_Object_04_YawAngle 500;
BA_REL_ "GenSigTimeoutTime" BU_SG_REL_ MRR2023 SG_ 2331595777 NR_FL_Object_04_YawAngleSD 500;
BA_REL_ "GenSigTimeoutTime" BU_SG_REL_ MRR2023 SG_ 2331595777 NR_FL_Object_04_Width 500;
BA_REL_ "GenSigTimeoutTime" BU_SG_REL_ MRR2023 SG_ 2331595777 NR_FL_Object_04_WidthSD 500;
BA_REL_ "GenSigTimeoutTime" BU_SG_REL_ MRR2023 SG_ 2331595777 NR_FL_Object_04_Length 500;
BA_REL_ "GenSigTimeoutTime" BU_SG_REL_ MRR2023 SG_ 2331595777 NR_FL_Object_04_LengthSD 500;
BA_REL_ "GenSigTimeoutTime" BU_SG_REL_ MRR2023 SG_ 2331595777 NR_FL_Object_04_Class 500;
BA_REL_ "GenSigTimeoutTime" BU_SG_REL_ MRR2023 SG_ 2331595777 NR_FL_Object_04_ClassPlausib 500;
BA_REL_ "GenSigTimeoutTime" BU_SG_REL_ MRR2023 SG_ 2331595777 NR_FL_Object_04_ExistProb 500;
BA_REL_ "GenSigTimeoutTime" BU_SG_REL_ MRR2023 SG_ 2331595777 NR_FL_Object_04_Age 500;
BA_REL_ "GenSigTimeoutTime" BU_SG_REL_ MRR2023 SG_ 2331595777 NR_FL_Object_04_YawRateAbs 500;
BA_REL_ "GenSigTimeoutTime" BU_SG_REL_ MRR2023 SG_ 2331595777 NR_FL_Object_04_YawRateAbsSD 500;
BA_REL_ "GenSigTimeoutTime" BU_SG_REL_ MRR2023 SG_ 2331595777 NR_FL_Object_04_MeasurementState 500;
BA_REL_ "GenSigTimeoutTime" BU_SG_REL_ MRR2023 SG_ 2331595778 NR_FL_Object_05_06_CRC 500;
BA_REL_ "GenSigTimeoutTime" BU_SG_REL_ MRR2023 SG_ 2331595778 NR_FL_Object_05_06_BZ 500;
BA_REL_ "GenSigTimeoutTime" BU_SG_REL_ MRR2023 SG_ 2331595778 NR_FL_Object_05_06_BlockID_01 500;
BA_REL_ "GenSigTimeoutTime" BU_SG_REL_ MRR2023 SG_ 2331595778 NR_FL_Object_05_ID 500;
BA_REL_ "GenSigTimeoutTime" BU_SG_REL_ MRR2023 SG_ 2331595778 NR_FL_Object_05_ReferencePoint 500;
BA_REL_ "GenSigTimeoutTime" BU_SG_REL_ MRR2023 SG_ 2331595778 NR_FL_Object_05_PosX 500;
BA_REL_ "GenSigTimeoutTime" BU_SG_REL_ MRR2023 SG_ 2331595778 NR_FL_Object_05_PosXSD 500;
BA_REL_ "GenSigTimeoutTime" BU_SG_REL_ MRR2023 SG_ 2331595778 NR_FL_Object_05_PosY 500;
BA_REL_ "GenSigTimeoutTime" BU_SG_REL_ MRR2023 SG_ 2331595778 NR_FL_Object_05_PosYSD 500;
BA_REL_ "GenSigTimeoutTime" BU_SG_REL_ MRR2023 SG_ 2331595778 NR_FL_Object_05_vAbsX 500;
BA_REL_ "GenSigTimeoutTime" BU_SG_REL_ MRR2023 SG_ 2331595778 NR_FL_Object_05_vAbsXSD 500;
BA_REL_ "GenSigTimeoutTime" BU_SG_REL_ MRR2023 SG_ 2331595778 NR_FL_Object_05_vAbsY 500;
BA_REL_ "GenSigTimeoutTime" BU_SG_REL_ MRR2023 SG_ 2331595778 NR_FL_Object_05_vAbsYSD 500;
BA_REL_ "GenSigTimeoutTime" BU_SG_REL_ MRR2023 SG_ 2331595778 NR_FL_Object_05_aAbsX 500;
BA_REL_ "GenSigTimeoutTime" BU_SG_REL_ MRR2023 SG_ 2331595778 NR_FL_Object_05_aAbsXSD 500;
BA_REL_ "GenSigTimeoutTime" BU_SG_REL_ MRR2023 SG_ 2331595778 NR_FL_Object_05_aAbsY 500;
BA_REL_ "GenSigTimeoutTime" BU_SG_REL_ MRR2023 SG_ 2331595778 NR_FL_Object_05_aAbsYSD 500;
BA_REL_ "GenSigTimeoutTime" BU_SG_REL_ MRR2023 SG_ 2331595778 NR_FL_Object_05_DynamicState 500;
BA_REL_ "GenSigTimeoutTime" BU_SG_REL_ MRR2023 SG_ 2331595778 NR_FL_Object_05_YawAngle 500;
BA_REL_ "GenSigTimeoutTime" BU_SG_REL_ MRR2023 SG_ 2331595778 NR_FL_Object_05_YawAngleSD 500;
BA_REL_ "GenSigTimeoutTime" BU_SG_REL_ MRR2023 SG_ 2331595778 NR_FL_Object_05_Width 500;
BA_REL_ "GenSigTimeoutTime" BU_SG_REL_ MRR2023 SG_ 2331595778 NR_FL_Object_05_WidthSD 500;
BA_REL_ "GenSigTimeoutTime" BU_SG_REL_ MRR2023 SG_ 2331595778 NR_FL_Object_05_Length 500;
BA_REL_ "GenSigTimeoutTime" BU_SG_REL_ MRR2023 SG_ 2331595778 NR_FL_Object_05_LengthSD 500;
BA_REL_ "GenSigTimeoutTime" BU_SG_REL_ MRR2023 SG_ 2331595778 NR_FL_Object_05_Class 500;
BA_REL_ "GenSigTimeoutTime" BU_SG_REL_ MRR2023 SG_ 2331595778 NR_FL_Object_05_ClassPlausib 500;
BA_REL_ "GenSigTimeoutTime" BU_SG_REL_ MRR2023 SG_ 2331595778 NR_FL_Object_05_ExistProb 500;
BA_REL_ "GenSigTimeoutTime" BU_SG_REL_ MRR2023 SG_ 2331595778 NR_FL_Object_05_Age 500;
BA_REL_ "GenSigTimeoutTime" BU_SG_REL_ MRR2023 SG_ 2331595778 NR_FL_Object_05_YawRateAbs 500;
BA_REL_ "GenSigTimeoutTime" BU_SG_REL_ MRR2023 SG_ 2331595778 NR_FL_Object_05_YawRateAbsSD 500;
BA_REL_ "GenSigTimeoutTime" BU_SG_REL_ MRR2023 SG_ 2331595778 NR_FL_Object_05_MeasurementState 500;
BA_REL_ "GenSigTimeoutTime" BU_SG_REL_ MRR2023 SG_ 2331595778 NR_FL_Object_06_ID 500;
BA_REL_ "GenSigTimeoutTime" BU_SG_REL_ MRR2023 SG_ 2331595778 NR_FL_Object_06_ReferencePoint 500;
BA_REL_ "GenSigTimeoutTime" BU_SG_REL_ MRR2023 SG_ 2331595778 NR_FL_Object_06_PosX 500;
BA_REL_ "GenSigTimeoutTime" BU_SG_REL_ MRR2023 SG_ 2331595778 NR_FL_Object_06_PosXSD 500;
BA_REL_ "GenSigTimeoutTime" BU_SG_REL_ MRR2023 SG_ 2331595778 NR_FL_Object_06_PosY 500;
BA_REL_ "GenSigTimeoutTime" BU_SG_REL_ MRR2023 SG_ 2331595778 NR_FL_Object_06_PosYSD 500;
BA_REL_ "GenSigTimeoutTime" BU_SG_REL_ MRR2023 SG_ 2331595778 NR_FL_Object_06_vAbsX 500;
BA_REL_ "GenSigTimeoutTime" BU_SG_REL_ MRR2023 SG_ 2331595778 NR_FL_Object_06_vAbsXSD 500;
BA_REL_ "GenSigTimeoutTime" BU_SG_REL_ MRR2023 SG_ 2331595778 NR_FL_Object_06_vAbsY 500;
BA_REL_ "GenSigTimeoutTime" BU_SG_REL_ MRR2023 SG_ 2331595778 NR_FL_Object_06_vAbsYSD 500;
BA_REL_ "GenSigTimeoutTime" BU_SG_REL_ MRR2023 SG_ 2331595778 NR_FL_Object_06_aAbsX 500;
BA_REL_ "GenSigTimeoutTime" BU_SG_REL_ MRR2023 SG_ 2331595778 NR_FL_Object_06_aAbsXSD 500;
BA_REL_ "GenSigTimeoutTime" BU_SG_REL_ MRR2023 SG_ 2331595778 NR_FL_Object_06_aAbsY 500;
BA_REL_ "GenSigTimeoutTime" BU_SG_REL_ MRR2023 SG_ 2331595778 NR_FL_Object_06_aAbsYSD 500;
BA_REL_ "GenSigTimeoutTime" BU_SG_REL_ MRR2023 SG_ 2331595778 NR_FL_Object_06_DynamicState 500;
BA_REL_ "GenSigTimeoutTime" BU_SG_REL_ MRR2023 SG_ 2331595778 NR_FL_Object_06_YawAngle 500;
BA_REL_ "GenSigTimeoutTime" BU_SG_REL_ MRR2023 SG_ 2331595778 NR_FL_Object_06_YawAngleSD 500;
BA_REL_ "GenSigTimeoutTime" BU_SG_REL_ MRR2023 SG_ 2331595778 NR_FL_Object_06_Width 500;
BA_REL_ "GenSigTimeoutTime" BU_SG_REL_ MRR2023 SG_ 2331595778 NR_FL_Object_06_WidthSD 500;
BA_REL_ "GenSigTimeoutTime" BU_SG_REL_ MRR2023 SG_ 2331595778 NR_FL_Object_06_Length 500;
BA_REL_ "GenSigTimeoutTime" BU_SG_REL_ MRR2023 SG_ 2331595778 NR_FL_Object_06_LengthSD 500;
BA_REL_ "GenSigTimeoutTime" BU_SG_REL_ MRR2023 SG_ 2331595778 NR_FL_Object_06_Class 500;
BA_REL_ "GenSigTimeoutTime" BU_SG_REL_ MRR2023 SG_ 2331595778 NR_FL_Object_06_ClassPlausib 500;
BA_REL_ "GenSigTimeoutTime" BU_SG_REL_ MRR2023 SG_ 2331595778 NR_FL_Object_06_ExistProb 500;
BA_REL_ "GenSigTimeoutTime" BU_SG_REL_ MRR2023 SG_ 2331595778 NR_FL_Object_06_Age 500;
BA_REL_ "GenSigTimeoutTime" BU_SG_REL_ MRR2023 SG_ 2331595778 NR_FL_Object_06_YawRateAbs 500;
BA_REL_ "GenSigTimeoutTime" BU_SG_REL_ MRR2023 SG_ 2331595778 NR_FL_Object_06_YawRateAbsSD 500;
BA_REL_ "GenSigTimeoutTime" BU_SG_REL_ MRR2023 SG_ 2331595778 NR_FL_Object_06_MeasurementState 500;
BA_REL_ "GenSigTimeoutTime" BU_SG_REL_ MRR2023 SG_ 2331595779 NR_FL_Object_07_08_CRC 500;
BA_REL_ "GenSigTimeoutTime" BU_SG_REL_ MRR2023 SG_ 2331595779 NR_FL_Object_07_08_BZ 500;
BA_REL_ "GenSigTimeoutTime" BU_SG_REL_ MRR2023 SG_ 2331595779 NR_FL_Object_07_08_BlockID_01 500;
BA_REL_ "GenSigTimeoutTime" BU_SG_REL_ MRR2023 SG_ 2331595779 NR_FL_Object_07_ID 500;
BA_REL_ "GenSigTimeoutTime" BU_SG_REL_ MRR2023 SG_ 2331595779 NR_FL_Object_07_ReferencePoint 500;
BA_REL_ "GenSigTimeoutTime" BU_SG_REL_ MRR2023 SG_ 2331595779 NR_FL_Object_07_PosX 500;
BA_REL_ "GenSigTimeoutTime" BU_SG_REL_ MRR2023 SG_ 2331595779 NR_FL_Object_07_PosXSD 500;
BA_REL_ "GenSigTimeoutTime" BU_SG_REL_ MRR2023 SG_ 2331595779 NR_FL_Object_07_PosY 500;
BA_REL_ "GenSigTimeoutTime" BU_SG_REL_ MRR2023 SG_ 2331595779 NR_FL_Object_07_PosYSD 500;
BA_REL_ "GenSigTimeoutTime" BU_SG_REL_ MRR2023 SG_ 2331595779 NR_FL_Object_07_vAbsX 500;
BA_REL_ "GenSigTimeoutTime" BU_SG_REL_ MRR2023 SG_ 2331595779 NR_FL_Object_07_vAbsXSD 500;
BA_REL_ "GenSigTimeoutTime" BU_SG_REL_ MRR2023 SG_ 2331595779 NR_FL_Object_07_vAbsY 500;
BA_REL_ "GenSigTimeoutTime" BU_SG_REL_ MRR2023 SG_ 2331595779 NR_FL_Object_07_vAbsYSD 500;
BA_REL_ "GenSigTimeoutTime" BU_SG_REL_ MRR2023 SG_ 2331595779 NR_FL_Object_07_aAbsX 500;
BA_REL_ "GenSigTimeoutTime" BU_SG_REL_ MRR2023 SG_ 2331595779 NR_FL_Object_07_aAbsXSD 500;
BA_REL_ "GenSigTimeoutTime" BU_SG_REL_ MRR2023 SG_ 2331595779 NR_FL_Object_07_aAbsY 500;
BA_REL_ "GenSigTimeoutTime" BU_SG_REL_ MRR2023 SG_ 2331595779 NR_FL_Object_07_aAbsYSD 500;
BA_REL_ "GenSigTimeoutTime" BU_SG_REL_ MRR2023 SG_ 2331595779 NR_FL_Object_07_DynamicState 500;
BA_REL_ "GenSigTimeoutTime" BU_SG_REL_ MRR2023 SG_ 2331595779 NR_FL_Object_07_YawAngle 500;
BA_REL_ "GenSigTimeoutTime" BU_SG_REL_ MRR2023 SG_ 2331595779 NR_FL_Object_07_YawAngleSD 500;
BA_REL_ "GenSigTimeoutTime" BU_SG_REL_ MRR2023 SG_ 2331595779 NR_FL_Object_07_Width 500;
BA_REL_ "GenSigTimeoutTime" BU_SG_REL_ MRR2023 SG_ 2331595779 NR_FL_Object_07_WidthSD 500;
BA_REL_ "GenSigTimeoutTime" BU_SG_REL_ MRR2023 SG_ 2331595779 NR_FL_Object_07_Length 500;
BA_REL_ "GenSigTimeoutTime" BU_SG_REL_ MRR2023 SG_ 2331595779 NR_FL_Object_07_LengthSD 500;
BA_REL_ "GenSigTimeoutTime" BU_SG_REL_ MRR2023 SG_ 2331595779 NR_FL_Object_07_Class 500;
BA_REL_ "GenSigTimeoutTime" BU_SG_REL_ MRR2023 SG_ 2331595779 NR_FL_Object_07_ClassPlausib 500;
BA_REL_ "GenSigTimeoutTime" BU_SG_REL_ MRR2023 SG_ 2331595779 NR_FL_Object_07_ExistProb 500;
BA_REL_ "GenSigTimeoutTime" BU_SG_REL_ MRR2023 SG_ 2331595779 NR_FL_Object_07_Age 500;
BA_REL_ "GenSigTimeoutTime" BU_SG_REL_ MRR2023 SG_ 2331595779 NR_FL_Object_07_YawRateAbs 500;
BA_REL_ "GenSigTimeoutTime" BU_SG_REL_ MRR2023 SG_ 2331595779 NR_FL_Object_07_YawRateAbsSD 500;
BA_REL_ "GenSigTimeoutTime" BU_SG_REL_ MRR2023 SG_ 2331595779 NR_FL_Object_07_MeasurementState 500;
BA_REL_ "GenSigTimeoutTime" BU_SG_REL_ MRR2023 SG_ 2331595779 NR_FL_Object_08_ID 500;
BA_REL_ "GenSigTimeoutTime" BU_SG_REL_ MRR2023 SG_ 2331595779 NR_FL_Object_08_ReferencePoint 500;
BA_REL_ "GenSigTimeoutTime" BU_SG_REL_ MRR2023 SG_ 2331595779 NR_FL_Object_08_PosX 500;
BA_REL_ "GenSigTimeoutTime" BU_SG_REL_ MRR2023 SG_ 2331595779 NR_FL_Object_08_PosXSD 500;
BA_REL_ "GenSigTimeoutTime" BU_SG_REL_ MRR2023 SG_ 2331595779 NR_FL_Object_08_PosY 500;
BA_REL_ "GenSigTimeoutTime" BU_SG_REL_ MRR2023 SG_ 2331595779 NR_FL_Object_08_PosYSD 500;
BA_REL_ "GenSigTimeoutTime" BU_SG_REL_ MRR2023 SG_ 2331595779 NR_FL_Object_08_vAbsX 500;
BA_REL_ "GenSigTimeoutTime" BU_SG_REL_ MRR2023 SG_ 2331595779 NR_FL_Object_08_vAbsXSD 500;
BA_REL_ "GenSigTimeoutTime" BU_SG_REL_ MRR2023 SG_ 2331595779 NR_FL_Object_08_vAbsY 500;
BA_REL_ "GenSigTimeoutTime" BU_SG_REL_ MRR2023 SG_ 2331595779 NR_FL_Object_08_vAbsYSD 500;
BA_REL_ "GenSigTimeoutTime" BU_SG_REL_ MRR2023 SG_ 2331595779 NR_FL_Object_08_aAbsX 500;
BA_REL_ "GenSigTimeoutTime" BU_SG_REL_ MRR2023 SG_ 2331595779 NR_FL_Object_08_aAbsXSD 500;
BA_REL_ "GenSigTimeoutTime" BU_SG_REL_ MRR2023 SG_ 2331595779 NR_FL_Object_08_aAbsY 500;
BA_REL_ "GenSigTimeoutTime" BU_SG_REL_ MRR2023 SG_ 2331595779 NR_FL_Object_08_aAbsYSD 500;
BA_REL_ "GenSigTimeoutTime" BU_SG_REL_ MRR2023 SG_ 2331595779 NR_FL_Object_08_DynamicState 500;
BA_REL_ "GenSigTimeoutTime" BU_SG_REL_ MRR2023 SG_ 2331595779 NR_FL_Object_08_YawAngle 500;
BA_REL_ "GenSigTimeoutTime" BU_SG_REL_ MRR2023 SG_ 2331595779 NR_FL_Object_08_YawAngleSD 500;
BA_REL_ "GenSigTimeoutTime" BU_SG_REL_ MRR2023 SG_ 2331595779 NR_FL_Object_08_Width 500;
BA_REL_ "GenSigTimeoutTime" BU_SG_REL_ MRR2023 SG_ 2331595779 NR_FL_Object_08_WidthSD 500;
BA_REL_ "GenSigTimeoutTime" BU_SG_REL_ MRR2023 SG_ 2331595779 NR_FL_Object_08_Length 500;
BA_REL_ "GenSigTimeoutTime" BU_SG_REL_ MRR2023 SG_ 2331595779 NR_FL_Object_08_LengthSD 500;
BA_REL_ "GenSigTimeoutTime" BU_SG_REL_ MRR2023 SG_ 2331595779 NR_FL_Object_08_Class 500;
BA_REL_ "GenSigTimeoutTime" BU_SG_REL_ MRR2023 SG_ 2331595779 NR_FL_Object_08_ClassPlausib 500;
BA_REL_ "GenSigTimeoutTime" BU_SG_REL_ MRR2023 SG_ 2331595779 NR_FL_Object_08_ExistProb 500;
BA_REL_ "GenSigTimeoutTime" BU_SG_REL_ MRR2023 SG_ 2331595779 NR_FL_Object_08_Age 500;
BA_REL_ "GenSigTimeoutTime" BU_SG_REL_ MRR2023 SG_ 2331595779 NR_FL_Object_08_YawRateAbs 500;
BA_REL_ "GenSigTimeoutTime" BU_SG_REL_ MRR2023 SG_ 2331595779 NR_FL_Object_08_YawRateAbsSD 500;
BA_REL_ "GenSigTimeoutTime" BU_SG_REL_ MRR2023 SG_ 2331595779 NR_FL_Object_08_MeasurementState 500;
BA_REL_ "GenSigTimeoutTime" BU_SG_REL_ NR_1 SG_ 2600468567 NM_ACC_NM_State 2000;
BA_REL_ "GenSigTimeoutTime" BU_SG_REL_ NR_1 SG_ 2600468496 NM_Gateway_NM_State 2000;
BA_REL_ "GenSigTimeoutTime" BU_SG_REL_ NR_1 SG_ 2600468559 NM_Kamera_NM_State 2000;
BA_REL_ "GenSigTimeoutTime" BU_SG_REL_ NR_1 SG_ 2600468668 NM_NR_02_NM_State 2000;
BA_REL_ "GenSigTimeoutTime" BU_SG_REL_ NR_2 SG_ 2600468567 NM_ACC_NM_State 2000;
BA_REL_ "GenSigTimeoutTime" BU_SG_REL_ NR_2 SG_ 2600468496 NM_Gateway_NM_State 2000;
BA_REL_ "GenSigTimeoutTime" BU_SG_REL_ NR_2 SG_ 2600468559 NM_Kamera_NM_State 2000;
BA_REL_ "GenSigTimeoutTime" BU_SG_REL_ NR_2 SG_ 2600468667 NM_NR_01_NM_State 2000;
VAL_ 2600468567 NM_ACC_CBV_AWB 0 "Passiver_WakeUp" 1 "Aktiver_WakeUp" ;
VAL_ 2600468567 NM_ACC_CBV_CRI 0 "NM_ohne_Clusteranforderungen" 1 "NM_mit_Clusteranforderungen" ;
VAL_ 2600468567 NM_ACC_NM_State 0 "Init" 1 "NM_RM_aus_BSM" 2 "NM_RM_aus_PBSM" 4 "NM_NO_aus_RM" 8 "NM_NO_aus_RS" 16 "reserved" 32 "reserved" ;
VAL_ 2600468567 NM_ACC_Car_Wakeup 0 "Inaktiv" 1 "Car_Wakeup" ;
VAL_ 2600468567 NM_ACC_UDS_CC 0 "Inaktiv" 1 "CC_aktiv" ;
VAL_ 2600468567 NM_ACC_NM_aktiv_KL15 0 "Inaktiv" 1 "KL15_EIN" ;
VAL_ 2600468567 NM_ACC_NM_aktiv_Diagnose 0 "Init" 1 "Diagnose_aktiv" ;
VAL_ 2600468567 NM_ACC_NM_aktiv_Tmin 0 "Inaktiv" 1 "Mindestaktivzeit" ;
VAL_ 2600468567 NM_ACC_CAB_V15 0 "Init" 1 "CAB_01_Antrieb" 2 "CAB_02_Hybrid_Laden" 4 "CAB_03_Fahrwerk" 8 "CAB_04_Fahrerassistenz" 16 "CAB_05_Komfort" 32 "CAB_06_Anzeige" 64 "CAB_07_Connect" 128 "CAB_08_MIB" 256 "CAB_09_Standheizung" 512 "CAB_10_MDK" 1024 "CAB_11_VLAN_Fahrerassistenz" 4096 "CAB_13_VLAN_Connect" 8192 "CAB_14_VLAN_Infotainment" 16384 "CAB_15_Laden" 32768 "CAB_16_Licht" 65536 "CAB_17_RTM" ;
VAL_ 2600468496 NM_Gateway_CBV_AWB 0 "Passiver_WakeUp" 1 "Aktiver_WakeUp" ;
VAL_ 2600468496 NM_Gateway_CBV_CRI 0 "NM_ohne_Clusteranforderungen" 1 "NM_mit_Clusteranforderungen" ;
VAL_ 2600468496 NM_Gateway_NM_State 0 "Init" 1 "NM_RM_aus_BSM" 2 "NM_RM_aus_PBSM" 4 "NM_NO_aus_RM" 8 "NM_NO_aus_RS" 16 "reserved" 32 "reserved" ;
VAL_ 2600468496 NM_Gateway_Car_Wakeup 0 "Inaktiv" 1 "Car_Wakeup" ;
VAL_ 2600468496 NM_Gateway_UDS_CC 0 "Inaktiv" 1 "CC_aktiv" ;
VAL_ 2600468496 NM_Gateway_NM_aktiv_KL15 0 "Inaktiv" 1 "KL15_EIN" ;
VAL_ 2600468496 NM_Gateway_NM_aktiv_Diagnose 0 "Init" 1 "Diagnose_aktiv" ;
VAL_ 2600468496 NM_Gateway_NM_aktiv_Tmin 0 "Inaktiv" 1 "Mindestaktivzeit" ;
VAL_ 2600468496 NM_Gateway_NM_aktiv_Kessy 0 "Inaktiv" 1 "Kessy_aktiv" ;
VAL_ 2600468496 NM_Gateway_NM_aktiv_Energie 0 "Inaktiv" 1 "Energie_aktiv" ;
VAL_ 2600468496 NM_Gateway_NM_aktiv_Licht 0 "Inaktiv" 1 "Licht_aktiv" ;
VAL_ 2600468496 NM_Gateway_NM_aktiv_USS 0 "Inaktiv" 1 "USS_aktiv" ;
VAL_ 2600468496 NM_Gateway_NM_aktiv_IAA_PSO 0 "Inaktiv" 1 "Personalisierung_aktiv" ;
VAL_ 2600468496 NM_Gateway_NM_aktiv_CAB 0 "Inaktiv" 1 "CAB_aktiv" ;
VAL_ 2600468496 NM_Gateway_NM_aktiv_KS 0 "Inaktiv" 1 "KS_aktiv" ;
VAL_ 2600468496 NM_Gateway_NM_aktiv_PaCo 0 "Inaktiv" 1 "PaCo_aktiv" ;
VAL_ 2600468496 NM_Gateway_NM_aktiv_Standklima 0 "Inaktiv" 1 "STK_aktiv" ;
VAL_ 2600468496 NM_Gateway_NM_aktiv_ZV 0 "Inaktiv" 1 "ZV_aktiv" ;
VAL_ 2600468496 NM_Gateway_NM_aktiv_RTM 0 "Inaktiv" 1 "RTM_aktiv" ;
VAL_ 2600468496 NM_Gateway_NM_aktiv_ZM 0 "Inaktiv" 1 "ZM_aktiv" ;
VAL_ 2600468496 NM_Gateway_NM_aktiv_FoD 0 "Inaktiv" 1 "FoD_aktiv" ;
VAL_ 2600468496 NM_Gateway_CAB_V15 0 "Init" 1 "CAB_01_Antrieb" 2 "CAB_02_Hybrid_Laden" 4 "CAB_03_Fahrwerk" 8 "CAB_04_Fahrerassistenz" 16 "CAB_05_Komfort" 32 "CAB_06_Anzeige" 64 "CAB_07_Connect" 128 "CAB_08_MIB" 256 "CAB_09_Standheizung" 512 "CAB_10_MDK" 1024 "CAB_11_VLAN_Fahrerassistenz" 4096 "CAB_13_VLAN_Connect" 8192 "CAB_14_VLAN_Infotainment" 16384 "CAB_15_Laden" 32768 "CAB_16_Licht" 65536 "CAB_17_RTM" ;
VAL_ 2600468559 NM_Kamera_CBV_AWB 0 "Passiver_WakeUp" 1 "Aktiver_WakeUp" ;
VAL_ 2600468559 NM_Kamera_CBV_CRI 0 "NM_ohne_Clusteranforderungen" 1 "NM_mit_Clusteranforderungen" ;
VAL_ 2600468559 NM_Kamera_NM_State 0 "Init" 1 "NM_RM_aus_BSM" 2 "NM_RM_aus_PBSM" 4 "NM_NO_aus_RM" 8 "NM_NO_aus_RS" 16 "reserved" 32 "reserved" ;
VAL_ 2600468559 NM_Kamera_Car_Wakeup 0 "Inaktiv" 1 "Car_Wakeup" ;
VAL_ 2600468559 NM_Kamera_UDS_CC 0 "Inaktiv" 1 "CC_aktiv" ;
VAL_ 2600468559 NM_Kamera_NM_aktiv_KL15 0 "Inaktiv" 1 "KL15_EIN" ;
VAL_ 2600468559 NM_Kamera_NM_aktiv_Diagnose 0 "Init" 1 "Diagnose_aktiv" ;
VAL_ 2600468559 NM_Kamera_NM_aktiv_Tmin 0 "Inaktiv" 1 "Mindestaktivzeit" ;
VAL_ 2600468559 NM_Kamera_CAB_V15 0 "Init" 1 "CAB_01_Antrieb" 2 "CAB_02_Hybrid_Laden" 4 "CAB_03_Fahrwerk" 8 "CAB_04_Fahrerassistenz" 16 "CAB_05_Komfort" 32 "CAB_06_Anzeige" 64 "CAB_07_Connect" 128 "CAB_08_MIB" 256 "CAB_09_Standheizung" 512 "CAB_10_MDK" 1024 "CAB_11_VLAN_Fahrerassistenz" 4096 "CAB_13_VLAN_Connect" 8192 "CAB_14_VLAN_Infotainment" 16384 "CAB_15_Laden" 32768 "CAB_16_Licht" 65536 "CAB_17_RTM" ;
VAL_ 2600468667 NM_NR_01_CBV_AWB 0 "Passiver_WakeUp" 1 "Aktiver_WakeUp" ;
VAL_ 2600468667 NM_NR_01_CBV_CRI 0 "NM_ohne_Clusteranforderungen" 1 "NM_mit_Clusteranforderungen" ;
VAL_ 2600468667 NM_NR_01_NM_State 0 "Init" 1 "NM_RM_aus_BSM" 2 "NM_RM_aus_PBSM" 4 "NM_NO_aus_RM" 8 "NM_NO_aus_RS" 16 "reserved" 32 "reserved" ;
VAL_ 2600468667 NM_NR_01_Car_Wakeup 0 "Inaktiv" 1 "Car_Wakeup" ;
VAL_ 2600468667 NM_NR_01_UDS_CC 0 "Inaktiv" 1 "CC_aktiv" ;
VAL_ 2600468667 NM_NR_01_NM_aktiv_KL15 0 "Inaktiv" 1 "KL15_EIN" ;
VAL_ 2600468667 NM_NR_01_NM_aktiv_Diagnose 0 "Inaktiv" 1 "Diagnose_aktiv" ;
VAL_ 2600468667 NM_NR_01_NM_aktiv_Tmin 0 "Inaktiv" 1 "Mindestaktivzeit" ;
VAL_ 2600468667 NM_NR_01_CAB_V15 0 "Init" 1 "CAB_01_Antrieb" 2 "CAB_02_Hybrid_Laden" 4 "CAB_03_Fahrwerk" 8 "CAB_04_Fahrerassistenz" 16 "CAB_05_Komfort" 32 "CAB_06_Anzeige" 64 "CAB_07_Connect" 128 "CAB_08_MIB" 256 "CAB_09_Standheizung" 512 "CAB_10_MDK" 1024 "CAB_11_VLAN_Fahrerassistenz" 4096 "CAB_13_VLAN_Connect" 8192 "CAB_14_VLAN_Infotainment" 16384 "CAB_15_Laden" 32768 "CAB_16_Licht" 65536 "CAB_17_RTM" ;
VAL_ 2600468668 NM_NR_02_CBV_AWB 0 "Passiver_WakeUp" 1 "Aktiver_WakeUp" ;
VAL_ 2600468668 NM_NR_02_CBV_CRI 0 "NM_ohne_Clusteranforderungen" 1 "NM_mit_Clusteranforderungen" ;
VAL_ 2600468668 NM_NR_02_NM_State 0 "Init" 1 "NM_RM_aus_BSM" 2 "NM_RM_aus_PBSM" 4 "NM_NO_aus_RM" 8 "NM_NO_aus_RS" 16 "reserved" 32 "reserved" ;
VAL_ 2600468668 NM_NR_02_Car_Wakeup 0 "Inaktiv" 1 "Car_Wakeup" ;
VAL_ 2600468668 NM_NR_02_UDS_CC 0 "Inaktiv" 1 "CC_aktiv" ;
VAL_ 2600468668 NM_NR_02_NM_aktiv_KL15 0 "Inaktiv" 1 "KL15_EIN" ;
VAL_ 2600468668 NM_NR_02_NM_aktiv_Diagnose 0 "Inaktiv" 1 "Diagnose_aktiv" ;
VAL_ 2600468668 NM_NR_02_NM_aktiv_Tmin 0 "Inaktiv" 1 "Mindestaktivzeit" ;
VAL_ 2600468668 NM_NR_02_CAB_V15 0 "Init" 1 "CAB_01_Antrieb" 2 "CAB_02_Hybrid_Laden" 4 "CAB_03_Fahrwerk" 8 "CAB_04_Fahrerassistenz" 16 "CAB_05_Komfort" 32 "CAB_06_Anzeige" 64 "CAB_07_Connect" 128 "CAB_08_MIB" 256 "CAB_09_Standheizung" 512 "CAB_10_MDK" 1024 "CAB_11_VLAN_Fahrerassistenz" 4096 "CAB_13_VLAN_Connect" 8192 "CAB_14_VLAN_Infotainment" 16384 "CAB_15_Laden" 32768 "CAB_16_Licht" 65536 "CAB_17_RTM" ;
VAL_ 2589283909 NR_01_CAL_Text_Request 0 "Cal_status_display_not_active" 1 "Cal_status_display_active" ;
VAL_ 2527679889 NR_02_CAL_LgtLimV_StAcv 0 "Passive" 1 "Active" 2 "Init" 3 "Fehler" ;
VAL_ 2527679889 NR_02_CAL_LgtLimV_VDmd 125 "Neutral" 126 "Init" 127 "Fehler" ;
VAL_ 2589283912 NR_02_CAL_Text_Request 0 "Cal_status_display_not_active" 1 "Cal_status_display_active" ;
VAL_ 2331595825 NR_FL_ShortTrackCal_State 0 "inaktive" 1 "waiting" 2 "active" 3 "ok" 4 "not_ok" 5 "reserved" 6 "reserved" 7 "Init" ;
VAL_ 2331595825 NR_FL_Cal_resp 0 "OFF" 1 "active" 2 "finished" 3 "suspend" 4 "passive" 5 "reserve" 6 "reserve" 7 "failure" ;
VAL_ 2331595825 NR_FL_CalibrationMode 0 "OFF_Init" 1 "EOL_stationary" 2 "autoalignment" 3 "short_track" 4 "service_dynamic" 5 "spc_continue" 6 "service_stationary" 7 "overwrite" ;
VAL_ 2331595825 NR_FL_resp_val 1015 "not_correct_calibrated" 1016 "not_calibrated" 1017 "target_not_found" 1018 "target_power_too_high" 1019 "angle_tolerance_failure" 1020 "target_not_stable" 1021 "storage_failed" 1022 "abort" 1023 "precondition_failure" ;
VAL_ 2331595825 NR_FL_QualFactorAutoCalib 0 "unknown_Init" 1 "precise" 2 "imprecise" 3 "failure" ;
VAL_ 2331595790 NR_FL_Contour_left_01_x01 8191 "Init" ;
VAL_ 2331595790 NR_FL_Contour_left_01_y01 2047 "Init" ;
VAL_ 2331595790 NR_FL_Contour_left_01_x02 8191 "Init" ;
VAL_ 2331595790 NR_FL_Contour_left_01_y02 2047 "Init" ;
VAL_ 2331595790 NR_FL_Contour_left_01_x03 8191 "Init" ;
VAL_ 2331595790 NR_FL_Contour_left_01_y03 2047 "Init" ;
VAL_ 2331595790 NR_FL_Contour_left_01_x04 8191 "Init" ;
VAL_ 2331595790 NR_FL_Contour_left_01_y04 2047 "Init" ;
VAL_ 2331595790 NR_FL_Contour_left_01_x05 8191 "Init" ;
VAL_ 2331595790 NR_FL_Contour_left_01_y05 2047 "Init" ;
VAL_ 2331595790 NR_FL_Contour_left_01_x06 8191 "Init" ;
VAL_ 2331595790 NR_FL_Contour_left_01_y06 2047 "Init" ;
VAL_ 2331595790 NR_FL_Contour_left_01_x07 8191 "Init" ;
VAL_ 2331595790 NR_FL_Contour_left_01_y07 2047 "Init" ;
VAL_ 2331595790 NR_FL_Contour_left_01_Type 0 "inactive" 1 "continuous_structural" 2 "linked_structural" 3 "irregular_or_unknown" 4 "point" 7 "Init" ;
VAL_ 2331595790 NR_FL_Contour_left_01_Age 127 "Init" ;
VAL_ 2331595790 NR_FL_Contour_left_02_x01 8191 "Init" ;
VAL_ 2331595790 NR_FL_Contour_left_02_y01 2047 "Init" ;
VAL_ 2331595790 NR_FL_Contour_left_02_x02 8191 "Init" ;
VAL_ 2331595790 NR_FL_Contour_left_02_y02 2047 "Init" ;
VAL_ 2331595790 NR_FL_Contour_left_02_x03 8191 "Init" ;
VAL_ 2331595790 NR_FL_Contour_left_02_y03 2047 "Init" ;
VAL_ 2331595790 NR_FL_Contour_left_02_x04 8191 "Init" ;
VAL_ 2331595790 NR_FL_Contour_left_02_y04 2047 "Init" ;
VAL_ 2331595790 NR_FL_Contour_left_02_x05 8191 "Init" ;
VAL_ 2331595790 NR_FL_Contour_left_02_y05 2047 "Init" ;
VAL_ 2331595790 NR_FL_Contour_left_02_x06 8191 "Init" ;
VAL_ 2331595790 NR_FL_Contour_left_02_y06 2047 "Init" ;
VAL_ 2331595790 NR_FL_Contour_left_02_x07 8191 "Init" ;
VAL_ 2331595790 NR_FL_Contour_left_02_y07 2047 "Init" ;
VAL_ 2331595790 NR_FL_Contour_left_02_Type 0 "inactive" 1 "continuous_structural" 2 "linked_structural" 3 "irregular_or_unknown" 4 "point" 7 "Init" ;
VAL_ 2331595790 NR_FL_Contour_left_02_Age 127 "Init" ;
VAL_ 2331595790 NR_FL_Contour_left_Linkage 0 "not_linked" 1 "linked" ;
VAL_ 2331595781 NR_FL_NotAvailable 0 "available" 1 "not_available" ;
VAL_ 2331595781 NR_FL_Failure 0 "no_failure" 1 "failure" ;
VAL_ 2331595781 NR_FL_Blindness 0 "not_blind" 1 "blind" ;
VAL_ 2331595781 NR_FL_CalibrationState 0 "init" 1 "no_initial_calibration" 2 "CL15_not_confirmed" 3 "misalignment_in_normal_range" 4 "misalignment_plausibility_check" 5 "calibration_out_of_range" 6 "reserved" 7 "reserved" ;
VAL_ 2331595781 NR_FL_Freesight_NOK 0 "Freesight_OK" 1 "Freesight_NOK" ;
VAL_ 2331595781 NR_FL_MeasurementTimeLow 0 "Init" 0 "Fehler" ;
VAL_ 2331595781 NR_FL_MeasurementTimeHigh 0 "Init" 0 "Fehler" ;
VAL_ 2331595781 NR_FL_RangeDegradation_Sect1 0 "0_percent" 1 "25_percent" 2 "50_percent" 3 "75_percent" 4 "100_percent" ;
VAL_ 2331595781 NR_FL_RangeDegradation_Sect2 0 "0_percent" 1 "25_percent" 2 "50_percent" 3 "75_percent" 4 "100_percent" ;
VAL_ 2331595781 NR_FL_RangeDegradation_Sect3 0 "0_percent" 1 "25_percent" 2 "50_percent" 3 "75_percent" 4 "100_percent" ;
VAL_ 2331595781 NR_FL_MeasurementTimeLapNumber 16382 "Init" 16383 "Fehler" ;
VAL_ 2331595781 NR_FL_MeasurementTimeStatus 0 "Init" 1 "PLT_ASIL" 2 "PLT_QM" 3 "Failure" ;
VAL_ 2331595776 NR_FL_Object_01_ID 0 "No_object" 255 "Init" ;
VAL_ 2331595776 NR_FL_Object_01_ReferencePoint 0 "unknown" 1 "front_left" 2 "front_center" 3 "front_right" 4 "right_center" 5 "rear_right" 6 "rear_center" 7 "rear_left" 8 "left_center" 9 "object_center" 10 "any_side_center" 15 "Init" ;
VAL_ 2331595776 NR_FL_Object_01_PosX 16383 "Init" ;
VAL_ 2331595776 NR_FL_Object_01_PosXSD 255 "Init" ;
VAL_ 2331595776 NR_FL_Object_01_PosY 8191 "Init" ;
VAL_ 2331595776 NR_FL_Object_01_PosYSD 255 "Init" ;
VAL_ 2331595776 NR_FL_Object_01_vAbsX 4095 "Init" ;
VAL_ 2331595776 NR_FL_Object_01_vAbsXSD 63 "Init" ;
VAL_ 2331595776 NR_FL_Object_01_vAbsY 4095 "Init" ;
VAL_ 2331595776 NR_FL_Object_01_vAbsYSD 63 "Init" ;
VAL_ 2331595776 NR_FL_Object_01_aAbsX 511 "Init" ;
VAL_ 2331595776 NR_FL_Object_01_aAbsXSD 63 "Init" ;
VAL_ 2331595776 NR_FL_Object_01_aAbsY 511 "Init" ;
VAL_ 2331595776 NR_FL_Object_01_aAbsYSD 63 "Init" ;
VAL_ 2331595776 NR_FL_Object_01_DynamicState 0 "moving" 1 "stationary" 2 "stopped" 3 "Init" ;
VAL_ 2331595776 NR_FL_Object_01_YawAngle 4095 "Init" ;
VAL_ 2331595776 NR_FL_Object_01_YawAngleSD 511 "Init" ;
VAL_ 2331595776 NR_FL_Object_01_Width 255 "Init" ;
VAL_ 2331595776 NR_FL_Object_01_WidthSD 127 "Init" ;
VAL_ 2331595776 NR_FL_Object_01_Length 1023 "Init" ;
VAL_ 2331595776 NR_FL_Object_01_LengthSD 127 "Init" ;
VAL_ 2331595776 NR_FL_Object_01_Class 0 "unknown" 1 "reserved" 2 "reserved" 3 "pedestrian" 4 "reserved" 5 "bicycle" 6 "motorcycle" 7 "car" 8 "reserved" 9 "truck" 10 "reserved" 11 "reserved" 12 "reserved" 13 "reserved" 15 "Init" ;
VAL_ 2331595776 NR_FL_Object_01_ClassPlausib 15 "Init" ;
VAL_ 2331595776 NR_FL_Object_01_ExistProb 127 "Init" ;
VAL_ 2331595776 NR_FL_Object_01_Age 127 "Init" ;
VAL_ 2331595776 NR_FL_Object_01_YawRateAbs 4095 "Init" ;
VAL_ 2331595776 NR_FL_Object_01_YawRateAbsSD 63 "Init" ;
VAL_ 2331595776 NR_FL_Object_01_MeasurementState 0 "predicted" 1 "measured" ;
VAL_ 2331595776 NR_FL_Object_02_ID 0 "No_object" 255 "Init" ;
VAL_ 2331595776 NR_FL_Object_02_ReferencePoint 0 "unknown" 1 "front_left" 2 "front_center" 3 "front_right" 4 "right_center" 5 "rear_right" 6 "rear_center" 7 "rear_left" 8 "left_center" 9 "object_center" 10 "any_side_center" 15 "Init" ;
VAL_ 2331595776 NR_FL_Object_02_PosX 16383 "Init" ;
VAL_ 2331595776 NR_FL_Object_02_PosXSD 255 "Init" ;
VAL_ 2331595776 NR_FL_Object_02_PosY 8191 "Init" ;
VAL_ 2331595776 NR_FL_Object_02_PosYSD 255 "Init" ;
VAL_ 2331595776 NR_FL_Object_02_vAbsX 4095 "Init" ;
VAL_ 2331595776 NR_FL_Object_02_vAbsXSD 63 "Init" ;
VAL_ 2331595776 NR_FL_Object_02_vAbsY 4095 "Init" ;
VAL_ 2331595776 NR_FL_Object_02_vAbsYSD 63 "Init" ;
VAL_ 2331595776 NR_FL_Object_02_aAbsX 511 "Init" ;
VAL_ 2331595776 NR_FL_Object_02_aAbsXSD 63 "Init" ;
VAL_ 2331595776 NR_FL_Object_02_aAbsY 511 "Init" ;
VAL_ 2331595776 NR_FL_Object_02_aAbsYSD 63 "Init" ;
VAL_ 2331595776 NR_FL_Object_02_DynamicState 0 "moving" 1 "stationary" 2 "stopped" 3 "Init" ;
VAL_ 2331595776 NR_FL_Object_02_YawAngle 4095 "Init" ;
VAL_ 2331595776 NR_FL_Object_02_YawAngleSD 511 "Init" ;
VAL_ 2331595776 NR_FL_Object_02_Width 255 "Init" ;
VAL_ 2331595776 NR_FL_Object_02_WidthSD 127 "Init" ;
VAL_ 2331595776 NR_FL_Object_02_Length 1023 "Init" ;
VAL_ 2331595776 NR_FL_Object_02_LengthSD 127 "Init" ;
VAL_ 2331595776 NR_FL_Object_02_Class 0 "unknown" 1 "reserved" 2 "reserved" 3 "pedestrian" 4 "reserved" 5 "bicycle" 6 "motorcycle" 7 "car" 8 "reserved" 9 "truck" 10 "reserved" 11 "reserved" 12 "reserved" 13 "reserved" 15 "Init" ;
VAL_ 2331595776 NR_FL_Object_02_ClassPlausib 15 "Init" ;
VAL_ 2331595776 NR_FL_Object_02_ExistProb 127 "Init" ;
VAL_ 2331595776 NR_FL_Object_02_Age 127 "Init" ;
VAL_ 2331595776 NR_FL_Object_02_YawRateAbs 4095 "Init" ;
VAL_ 2331595776 NR_FL_Object_02_YawRateAbsSD 63 "Init" ;
VAL_ 2331595776 NR_FL_Object_02_MeasurementState 0 "predicted" 1 "measured" ;
VAL_ 2331595777 NR_FL_Object_03_ID 0 "No_object" 255 "Init" ;
VAL_ 2331595777 NR_FL_Object_03_ReferencePoint 0 "unknown" 1 "front_left" 2 "front_center" 3 "front_right" 4 "right_center" 5 "rear_right" 6 "rear_center" 7 "rear_left" 8 "left_center" 9 "object_center" 10 "any_side_center" 15 "Init" ;
VAL_ 2331595777 NR_FL_Object_03_PosX 16383 "Init" ;
VAL_ 2331595777 NR_FL_Object_03_PosXSD 255 "Init" ;
VAL_ 2331595777 NR_FL_Object_03_PosY 8191 "Init" ;
VAL_ 2331595777 NR_FL_Object_03_PosYSD 255 "Init" ;
VAL_ 2331595777 NR_FL_Object_03_vAbsX 4095 "Init" ;
VAL_ 2331595777 NR_FL_Object_03_vAbsXSD 63 "Init" ;
VAL_ 2331595777 NR_FL_Object_03_vAbsY 4095 "Init" ;
VAL_ 2331595777 NR_FL_Object_03_vAbsYSD 63 "Init" ;
VAL_ 2331595777 NR_FL_Object_03_aAbsX 511 "Init" ;
VAL_ 2331595777 NR_FL_Object_03_aAbsXSD 63 "Init" ;
VAL_ 2331595777 NR_FL_Object_03_aAbsY 511 "Init" ;
VAL_ 2331595777 NR_FL_Object_03_aAbsYSD 63 "Init" ;
VAL_ 2331595777 NR_FL_Object_03_DynamicState 0 "moving" 1 "stationary" 2 "stopped" 3 "Init" ;
VAL_ 2331595777 NR_FL_Object_03_YawAngle 4095 "Init" ;
VAL_ 2331595777 NR_FL_Object_03_YawAngleSD 511 "Init" ;
VAL_ 2331595777 NR_FL_Object_03_Width 255 "Init" ;
VAL_ 2331595777 NR_FL_Object_03_WidthSD 127 "Init" ;
VAL_ 2331595777 NR_FL_Object_03_Length 1023 "Init" ;
VAL_ 2331595777 NR_FL_Object_03_LengthSD 127 "Init" ;
VAL_ 2331595777 NR_FL_Object_03_Class 0 "unknown" 1 "reserved" 2 "reserved" 3 "pedestrian" 4 "reserved" 5 "bicycle" 6 "motorcycle" 7 "car" 8 "reserved" 9 "truck" 10 "reserved" 11 "reserved" 12 "reserved" 13 "reserved" 15 "Init" ;
VAL_ 2331595777 NR_FL_Object_03_ClassPlausib 15 "Init" ;
VAL_ 2331595777 NR_FL_Object_03_ExistProb 127 "Init" ;
VAL_ 2331595777 NR_FL_Object_03_Age 127 "Init" ;
VAL_ 2331595777 NR_FL_Object_03_YawRateAbs 4095 "Init" ;
VAL_ 2331595777 NR_FL_Object_03_YawRateAbsSD 63 "Init" ;
VAL_ 2331595777 NR_FL_Object_03_MeasurementState 0 "predicted" 1 "measured" ;
VAL_ 2331595777 NR_FL_Object_04_ID 0 "No_object" 255 "Init" ;
VAL_ 2331595777 NR_FL_Object_04_ReferencePoint 0 "unknown" 1 "front_left" 2 "front_center" 3 "front_right" 4 "right_center" 5 "rear_right" 6 "rear_center" 7 "rear_left" 8 "left_center" 9 "object_center" 10 "any_side_center" 15 "Init" ;
VAL_ 2331595777 NR_FL_Object_04_PosX 16383 "Init" ;
VAL_ 2331595777 NR_FL_Object_04_PosXSD 255 "Init" ;
VAL_ 2331595777 NR_FL_Object_04_PosY 8191 "Init" ;
VAL_ 2331595777 NR_FL_Object_04_PosYSD 255 "Init" ;
VAL_ 2331595777 NR_FL_Object_04_vAbsX 4095 "Init" ;
VAL_ 2331595777 NR_FL_Object_04_vAbsXSD 63 "Init" ;
VAL_ 2331595777 NR_FL_Object_04_vAbsY 4095 "Init" ;
VAL_ 2331595777 NR_FL_Object_04_vAbsYSD 63 "Init" ;
VAL_ 2331595777 NR_FL_Object_04_aAbsX 511 "Init" ;
VAL_ 2331595777 NR_FL_Object_04_aAbsXSD 63 "Init" ;
VAL_ 2331595777 NR_FL_Object_04_aAbsY 511 "Init" ;
VAL_ 2331595777 NR_FL_Object_04_aAbsYSD 63 "Init" ;
VAL_ 2331595777 NR_FL_Object_04_DynamicState 0 "moving" 1 "stationary" 2 "stopped" 3 "Init" ;
VAL_ 2331595777 NR_FL_Object_04_YawAngle 4095 "Init" ;
VAL_ 2331595777 NR_FL_Object_04_YawAngleSD 511 "Init" ;
VAL_ 2331595777 NR_FL_Object_04_Width 255 "Init" ;
VAL_ 2331595777 NR_FL_Object_04_WidthSD 127 "Init" ;
VAL_ 2331595777 NR_FL_Object_04_Length 1023 "Init" ;
VAL_ 2331595777 NR_FL_Object_04_LengthSD 127 "Init" ;
VAL_ 2331595777 NR_FL_Object_04_Class 0 "unknown" 1 "reserved" 2 "reserved" 3 "pedestrian" 4 "reserved" 5 "bicycle" 6 "motorcycle" 7 "car" 8 "reserved" 9 "truck" 10 "reserved" 11 "reserved" 12 "reserved" 13 "reserved" 15 "Init" ;
VAL_ 2331595777 NR_FL_Object_04_ClassPlausib 15 "Init" ;
VAL_ 2331595777 NR_FL_Object_04_ExistProb 127 "Init" ;
VAL_ 2331595777 NR_FL_Object_04_Age 127 "Init" ;
VAL_ 2331595777 NR_FL_Object_04_YawRateAbs 4095 "Init" ;
VAL_ 2331595777 NR_FL_Object_04_YawRateAbsSD 63 "Init" ;
VAL_ 2331595777 NR_FL_Object_04_MeasurementState 0 "predicted" 1 "measured" ;
VAL_ 2331595778 NR_FL_Object_05_ID 0 "No_object" 255 "Init" ;
VAL_ 2331595778 NR_FL_Object_05_ReferencePoint 0 "unknown" 1 "front_left" 2 "front_center" 3 "front_right" 4 "right_center" 5 "rear_right" 6 "rear_center" 7 "rear_left" 8 "left_center" 9 "object_center" 10 "any_side_center" 15 "Init" ;
VAL_ 2331595778 NR_FL_Object_05_PosX 16383 "Init" ;
VAL_ 2331595778 NR_FL_Object_05_PosXSD 255 "Init" ;
VAL_ 2331595778 NR_FL_Object_05_PosY 8191 "Init" ;
VAL_ 2331595778 NR_FL_Object_05_PosYSD 255 "Init" ;
VAL_ 2331595778 NR_FL_Object_05_vAbsX 4095 "Init" ;
VAL_ 2331595778 NR_FL_Object_05_vAbsXSD 63 "Init" ;
VAL_ 2331595778 NR_FL_Object_05_vAbsY 4095 "Init" ;
VAL_ 2331595778 NR_FL_Object_05_vAbsYSD 63 "Init" ;
VAL_ 2331595778 NR_FL_Object_05_aAbsX 511 "Init" ;
VAL_ 2331595778 NR_FL_Object_05_aAbsXSD 63 "Init" ;
VAL_ 2331595778 NR_FL_Object_05_aAbsY 511 "Init" ;
VAL_ 2331595778 NR_FL_Object_05_aAbsYSD 63 "Init" ;
VAL_ 2331595778 NR_FL_Object_05_DynamicState 0 "moving" 1 "stationary" 2 "stopped" 3 "Init" ;
VAL_ 2331595778 NR_FL_Object_05_YawAngle 4095 "Init" ;
VAL_ 2331595778 NR_FL_Object_05_YawAngleSD 511 "Init" ;
VAL_ 2331595778 NR_FL_Object_05_Width 255 "Init" ;
VAL_ 2331595778 NR_FL_Object_05_WidthSD 127 "Init" ;
VAL_ 2331595778 NR_FL_Object_05_Length 1023 "Init" ;
VAL_ 2331595778 NR_FL_Object_05_LengthSD 127 "Init" ;
VAL_ 2331595778 NR_FL_Object_05_Class 0 "unknown" 1 "reserved" 2 "reserved" 3 "pedestrian" 4 "reserved" 5 "bicycle" 6 "motorcycle" 7 "car" 8 "reserved" 9 "truck" 10 "reserved" 11 "reserved" 12 "reserved" 13 "reserved" 15 "Init" ;
VAL_ 2331595778 NR_FL_Object_05_ClassPlausib 15 "Init" ;
VAL_ 2331595778 NR_FL_Object_05_ExistProb 127 "Init" ;
VAL_ 2331595778 NR_FL_Object_05_Age 127 "Init" ;
VAL_ 2331595778 NR_FL_Object_05_YawRateAbs 4095 "Init" ;
VAL_ 2331595778 NR_FL_Object_05_YawRateAbsSD 63 "Init" ;
VAL_ 2331595778 NR_FL_Object_05_MeasurementState 0 "predicted" 1 "measured" ;
VAL_ 2331595778 NR_FL_Object_06_ID 0 "No_object" 255 "Init" ;
VAL_ 2331595778 NR_FL_Object_06_ReferencePoint 0 "unknown" 1 "front_left" 2 "front_center" 3 "front_right" 4 "right_center" 5 "rear_right" 6 "rear_center" 7 "rear_left" 8 "left_center" 9 "object_center" 10 "any_side_center" 15 "Init" ;
VAL_ 2331595778 NR_FL_Object_06_PosX 16383 "Init" ;
VAL_ 2331595778 NR_FL_Object_06_PosXSD 255 "Init" ;
VAL_ 2331595778 NR_FL_Object_06_PosY 8191 "Init" ;
VAL_ 2331595778 NR_FL_Object_06_PosYSD 255 "Init" ;
VAL_ 2331595778 NR_FL_Object_06_vAbsX 4095 "Init" ;
VAL_ 2331595778 NR_FL_Object_06_vAbsXSD 63 "Init" ;
VAL_ 2331595778 NR_FL_Object_06_vAbsY 4095 "Init" ;
VAL_ 2331595778 NR_FL_Object_06_vAbsYSD 63 "Init" ;
VAL_ 2331595778 NR_FL_Object_06_aAbsX 511 "Init" ;
VAL_ 2331595778 NR_FL_Object_06_aAbsXSD 63 "Init" ;
VAL_ 2331595778 NR_FL_Object_06_aAbsY 511 "Init" ;
VAL_ 2331595778 NR_FL_Object_06_aAbsYSD 63 "Init" ;
VAL_ 2331595778 NR_FL_Object_06_DynamicState 0 "moving" 1 "stationary" 2 "stopped" 3 "Init" ;
VAL_ 2331595778 NR_FL_Object_06_YawAngle 4095 "Init" ;
VAL_ 2331595778 NR_FL_Object_06_YawAngleSD 511 "Init" ;
VAL_ 2331595778 NR_FL_Object_06_Width 255 "Init" ;
VAL_ 2331595778 NR_FL_Object_06_WidthSD 127 "Init" ;
VAL_ 2331595778 NR_FL_Object_06_Length 1023 "Init" ;
VAL_ 2331595778 NR_FL_Object_06_LengthSD 127 "Init" ;
VAL_ 2331595778 NR_FL_Object_06_Class 0 "unknown" 1 "reserved" 2 "reserved" 3 "pedestrian" 4 "reserved" 5 "bicycle" 6 "motorcycle" 7 "car" 8 "reserved" 9 "truck" 10 "reserved" 11 "reserved" 12 "reserved" 13 "reserved" 15 "Init" ;
VAL_ 2331595778 NR_FL_Object_06_ClassPlausib 15 "Init" ;
VAL_ 2331595778 NR_FL_Object_06_ExistProb 127 "Init" ;
VAL_ 2331595778 NR_FL_Object_06_Age 127 "Init" ;
VAL_ 2331595778 NR_FL_Object_06_YawRateAbs 4095 "Init" ;
VAL_ 2331595778 NR_FL_Object_06_YawRateAbsSD 63 "Init" ;
VAL_ 2331595778 NR_FL_Object_06_MeasurementState 0 "predicted" 1 "measured" ;
VAL_ 2331595779 NR_FL_Object_07_ID 0 "No_object" 255 "Init" ;
VAL_ 2331595779 NR_FL_Object_07_ReferencePoint 0 "unknown" 1 "front_left" 2 "front_center" 3 "front_right" 4 "right_center" 5 "rear_right" 6 "rear_center" 7 "rear_left" 8 "left_center" 9 "object_center" 10 "any_side_center" 15 "Init" ;
VAL_ 2331595779 NR_FL_Object_07_PosX 16383 "Init" ;
VAL_ 2331595779 NR_FL_Object_07_PosXSD 255 "Init" ;
VAL_ 2331595779 NR_FL_Object_07_PosY 8191 "Init" ;
VAL_ 2331595779 NR_FL_Object_07_PosYSD 255 "Init" ;
VAL_ 2331595779 NR_FL_Object_07_vAbsX 4095 "Init" ;
VAL_ 2331595779 NR_FL_Object_07_vAbsXSD 63 "Init" ;
VAL_ 2331595779 NR_FL_Object_07_vAbsY 4095 "Init" ;
VAL_ 2331595779 NR_FL_Object_07_vAbsYSD 63 "Init" ;
VAL_ 2331595779 NR_FL_Object_07_aAbsX 511 "Init" ;
VAL_ 2331595779 NR_FL_Object_07_aAbsXSD 63 "Init" ;
VAL_ 2331595779 NR_FL_Object_07_aAbsY 511 "Init" ;
VAL_ 2331595779 NR_FL_Object_07_aAbsYSD 63 "Init" ;
VAL_ 2331595779 NR_FL_Object_07_DynamicState 0 "moving" 1 "stationary" 2 "stopped" 3 "Init" ;
VAL_ 2331595779 NR_FL_Object_07_YawAngle 4095 "Init" ;
VAL_ 2331595779 NR_FL_Object_07_YawAngleSD 511 "Init" ;
VAL_ 2331595779 NR_FL_Object_07_Width 255 "Init" ;
VAL_ 2331595779 NR_FL_Object_07_WidthSD 127 "Init" ;
VAL_ 2331595779 NR_FL_Object_07_Length 1023 "Init" ;
VAL_ 2331595779 NR_FL_Object_07_LengthSD 127 "Init" ;
VAL_ 2331595779 NR_FL_Object_07_Class 0 "unknown" 1 "reserved" 2 "reserved" 3 "pedestrian" 4 "reserved" 5 "bicycle" 6 "motorcycle" 7 "car" 8 "reserved" 9 "truck" 10 "reserved" 11 "reserved" 12 "reserved" 13 "reserved" 15 "Init" ;
VAL_ 2331595779 NR_FL_Object_07_ClassPlausib 15 "Init" ;
VAL_ 2331595779 NR_FL_Object_07_ExistProb 127 "Init" ;
VAL_ 2331595779 NR_FL_Object_07_Age 127 "Init" ;
VAL_ 2331595779 NR_FL_Object_07_YawRateAbs 4095 "Init" ;
VAL_ 2331595779 NR_FL_Object_07_YawRateAbsSD 63 "Init" ;
VAL_ 2331595779 NR_FL_Object_07_MeasurementState 0 "predicted" 1 "measured" ;
VAL_ 2331595779 NR_FL_Object_08_ID 0 "No_object" 255 "Init" ;
VAL_ 2331595779 NR_FL_Object_08_ReferencePoint 0 "unknown" 1 "front_left" 2 "front_center" 3 "front_right" 4 "right_center" 5 "rear_right" 6 "rear_center" 7 "rear_left" 8 "left_center" 9 "object_center" 10 "any_side_center" 15 "Init" ;
VAL_ 2331595779 NR_FL_Object_08_PosX 16383 "Init" ;
VAL_ 2331595779 NR_FL_Object_08_PosXSD 255 "Init" ;
VAL_ 2331595779 NR_FL_Object_08_PosY 8191 "Init" ;
VAL_ 2331595779 NR_FL_Object_08_PosYSD 255 "Init" ;
VAL_ 2331595779 NR_FL_Object_08_vAbsX 4095 "Init" ;
VAL_ 2331595779 NR_FL_Object_08_vAbsXSD 63 "Init" ;
VAL_ 2331595779 NR_FL_Object_08_vAbsY 4095 "Init" ;
VAL_ 2331595779 NR_FL_Object_08_vAbsYSD 63 "Init" ;
VAL_ 2331595779 NR_FL_Object_08_aAbsX 511 "Init" ;
VAL_ 2331595779 NR_FL_Object_08_aAbsXSD 63 "Init" ;
VAL_ 2331595779 NR_FL_Object_08_aAbsY 511 "Init" ;
VAL_ 2331595779 NR_FL_Object_08_aAbsYSD 63 "Init" ;
VAL_ 2331595779 NR_FL_Object_08_DynamicState 0 "moving" 1 "stationary" 2 "stopped" 3 "Init" ;
VAL_ 2331595779 NR_FL_Object_08_YawAngle 4095 "Init" ;
VAL_ 2331595779 NR_FL_Object_08_YawAngleSD 511 "Init" ;
VAL_ 2331595779 NR_FL_Object_08_Width 255 "Init" ;
VAL_ 2331595779 NR_FL_Object_08_WidthSD 127 "Init" ;
VAL_ 2331595779 NR_FL_Object_08_Length 1023 "Init" ;
VAL_ 2331595779 NR_FL_Object_08_LengthSD 127 "Init" ;
VAL_ 2331595779 NR_FL_Object_08_Class 0 "unknown" 1 "reserved" 2 "reserved" 3 "pedestrian" 4 "reserved" 5 "bicycle" 6 "motorcycle" 7 "car" 8 "reserved" 9 "truck" 10 "reserved" 11 "reserved" 12 "reserved" 13 "reserved" 15 "Init" ;
VAL_ 2331595779 NR_FL_Object_08_ClassPlausib 15 "Init" ;
VAL_ 2331595779 NR_FL_Object_08_ExistProb 127 "Init" ;
VAL_ 2331595779 NR_FL_Object_08_Age 127 "Init" ;
VAL_ 2331595779 NR_FL_Object_08_YawRateAbs 4095 "Init" ;
VAL_ 2331595779 NR_FL_Object_08_YawRateAbsSD 63 "Init" ;
VAL_ 2331595779 NR_FL_Object_08_MeasurementState 0 "predicted" 1 "measured" ;
